VERSION ""

NS_ :

BS_:

BU_: ACSM CAS CCC CCC_GW CID CID_C DME DSC DWA Diverse_Sender EGS FLA FRMFA FZD IHKA JBBF KBM KGM KOMBI Kombi MRSZ M_ASK PDC SM_BF SM_FA SZL SZM VDM ZBE

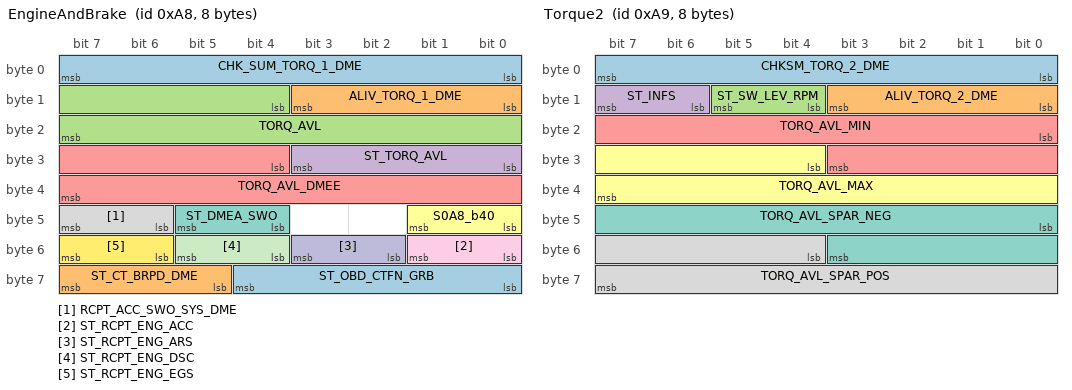
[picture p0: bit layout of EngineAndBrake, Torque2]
BO_ 168 EngineAndBrake: 8 DME
 SG_ CHK_SUM_TORQ_1_DME : 0|8@1+ (1,0) [0|255] "" Vector__XXX
 SG_ ALIV_TORQ_1_DME : 8|4@1+ (1,0) [0|15] "" Vector__XXX
 SG_ TORQ_AVL : 12|12@1- (0.5,0) [-1024|1023.5] "Nm" Vector__XXX
 SG_ ST_TORQ_AVL : 24|4@1+ (1,0) [0|15] "" Vector__XXX
 SG_ TORQ_AVL_DMEE : 28|12@1- (0.5,0) [-1024|1023.5] "Nm" Vector__XXX
 SG_ S0A8_b40 : 40|2@1+ (1,0) [0|3] "" Vector__XXX
 SG_ ST_DMEA_SWO : 44|2@1+ (1,0) [0|3] "" Vector__XXX
 SG_ RCPT_ACC_SWO_SYS_DME : 46|2@1+ (1,0) [0|3] "" Vector__XXX
 SG_ ST_RCPT_ENG_ACC : 48|2@1+ (1,0) [0|3] "" Vector__XXX
 SG_ ST_RCPT_ENG_ARS : 50|2@1+ (1,0) [0|3] "" Vector__XXX
 SG_ ST_RCPT_ENG_DSC : 52|2@1+ (1,0) [0|3] "" Vector__XXX
 SG_ ST_RCPT_ENG_EGS : 54|2@1+ (1,0) [0|3] "" Vector__XXX
 SG_ ST_OBD_CTFN_GRB : 56|5@1+ (1,0) [0|31] "" Vector__XXX
 SG_ ST_CT_BRPD_DME : 61|3@1+ (1,0) [0|7] "" Vector__XXX

BO_ 169 Torque2: 8 DME
 SG_ CHKSM_TORQ_2_DME : 0|8@1+ (1,0) [0|255] "" Vector__XXX
 SG_ ALIV_TORQ_2_DME : 8|4@1+ (1,0) [0|15] "" Vector__XXX
 SG_ ST_SW_LEV_RPM : 12|2@1+ (1,0) [0|3] "" Vector__XXX
 SG_ ST_INFS : 14|2@1+ (1,0) [0|3] "" Vector__XXX
 SG_ TORQ_AVL_MIN : 16|12@1- (0.5,0) [-1024|1023.5] "Nm" Vector__XXX
 SG_ TORQ_AVL_MAX : 28|12@1- (0.5,0) [-1024|1023.5] "Nm" Vector__XXX
 SG_ TORQ_AVL_SPAR_NEG : 40|12@1- (0.5,0) [-1024|1023.5] "Nm" Vector__XXX
 SG_ TORQ_AVL_SPAR_POS : 52|12@1- (0.5,0) [-1024|1023.5] "Nm" Vector__XXX

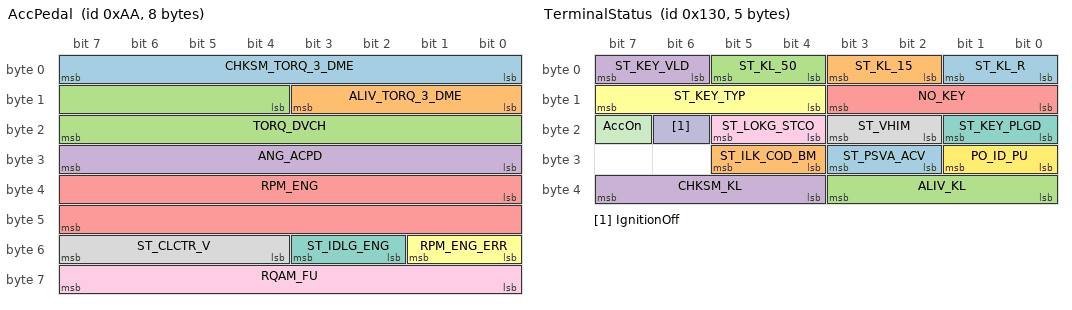
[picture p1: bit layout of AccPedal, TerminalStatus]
BO_ 170 AccPedal: 8 DME
 SG_ CHKSM_TORQ_3_DME : 0|8@1+ (1,0) [0|255] "" Vector__XXX
 SG_ ALIV_TORQ_3_DME : 8|4@1+ (1,0) [0|15] "" Vector__XXX
 SG_ TORQ_DVCH : 12|12@1- (0.5,0) [-1024|1023.5] "Nm" Vector__XXX
 SG_ ANG_ACPD : 24|8@1+ (0.39063,0) [0|99.61065] "%" Vector__XXX
 SG_ RPM_ENG : 32|16@1+ (0.25,0) [0|16383.75] "rpm" Vector__XXX
 SG_ RPM_ENG_ERR : 48|2@1+ (1,0) [0|3] "" Vector__XXX
 SG_ ST_IDLG_ENG : 50|2@1+ (1,0) [0|3] "" Vector__XXX
 SG_ ST_CLCTR_V : 52|4@1+ (1,0) [0|15] "" Vector__XXX
 SG_ RQAM_FU : 56|8@1+ (1,0) [0|255] "" Vector__XXX

BO_ 192 Alive_Central_Gateway: 2 JBBF

BO_ 196 SteeringWheelAngle: 7 DSC
 SG_ SteeringPosition : 0|16@1- (0.04395,0) [-1440.1536|1440.10965] "deg" Vector__XXX
 SG_ S0C4_b16 : 16|2@1+ (1,0) [0|3] "" Vector__XXX
 SG_ SteeringSpeed : 24|16@1- (0.04395,0) [-1440.1536|1440.10965] "deg/s" Vector__XXX
 SG_ S0C4_b40 : 40|8@1+ (1,0) [0|255] "" Vector__XXX
 SG_ S0C4_b48 : 48|2@1+ (1,0) [0|3] "" Vector__XXX
 SG_ S0C4_b50 : 50|2@1+ (1,0) [0|3] "" Vector__XXX

BO_ 200 SteeringWheelAngle_slow: 6 SZL
 SG_ SteeringPosition : 0|16@1- (0.04395,0) [-1440.1536|1440.10965] "deg" Vector__XXX
 SG_ Counter_200 : 20|4@1+ (1,0) [0|15] "" Vector__XXX
 SG_ SteeringSpeed : 24|16@1- (0.04395,0) [-1440.1536|1440.10965] "deg/s" Vector__XXX

BO_ 206 GESCHWINDIGKEIT_RAD: 8 DSC
 SG_ V_WHL_FLH : 0|16@1- (0.0625,0) [-2048|2047.9375] "km/h" Vector__XXX
 SG_ V_WHL_FRH : 16|16@1- (0.0625,0) [-2048|2047.9375] "km/h" Vector__XXX
 SG_ V_WHL_RLH : 32|16@1- (0.0625,0) [-2048|2047.9375] "km/h" Vector__XXX
 SG_ V_WHL_RRH : 48|16@1- (0.0625,0) [-2048|2047.9375] "km/h" Vector__XXX

BO_ 215 Alive_Counter_Security: 2 ACSM

BO_ 226 Status_central_locking_BFT: 8 JBBF

BO_ 230 Status_central_locking_BFTH: 8 JBBF

BO_ 234 Status_central_locking_FAT: 8 JBBF

BO_ 238 Central_locking_status_FATH: 8 JBBF

BO_ 242 Status_central_locking_HK: 8 JBBF

BO_ 246 SteuerungAu_enspiegel: 2 KGM

BO_ 250 Control_window_lifter_FAT: 3 FRMFA

BO_ 304 TerminalStatus: 5 CAS
 SG_ ST_KL_R : 0|2@1+ (1,0) [0|3] "" Vector__XXX
 SG_ ST_KL_15 : 2|2@1+ (1,0) [0|3] "" Vector__XXX
 SG_ ST_KL_50 : 4|2@1+ (1,0) [0|3] "" Vector__XXX
 SG_ ST_KEY_VLD : 6|2@1+ (1,0) [0|3] "" Vector__XXX
 SG_ NO_KEY : 8|4@1+ (1,0) [0|15] "" Vector__XXX
 SG_ ST_KEY_TYP : 12|4@1+ (1,0) [0|15] "" Vector__XXX
 SG_ ST_KEY_PLGD : 16|2@1+ (1,0) [0|3] "" Vector__XXX
 SG_ ST_VHIM : 18|2@1+ (1,0) [0|3] "" Vector__XXX
 SG_ ST_LOKG_STCO : 20|2@1+ (1,0) [0|3] "" Vector__XXX
 SG_ IgnitionOff : 22|1@1+ (1,0) [0|3] "" Vector__XXX
 SG_ AccOn : 23|1@1+ (1,0) [0|255] "" Vector__XXX
 SG_ PO_ID_PU : 24|2@1+ (1,0) [0|3] "" Vector__XXX
 SG_ ST_PSVA_ACV : 26|2@1+ (1,0) [0|3] "" Vector__XXX
 SG_ ST_ILK_COD_BM : 28|2@1+ (1,0) [0|3] "" Vector__XXX
 SG_ ALIV_KL : 32|4@1+ (1,0) [0|15] "" Vector__XXX
 SG_ CHKSM_KL : 36|4@1+ (1,0) [0|15] "" Vector__XXX

BO_ 309 CrashDisconnectControl: 2 ACSM
 SG_ CTR_CR_SWO_EKP : 0|4@1+ (1,0) [0|15] "" Vector__XXX

BO_ 370 Acknowledgment_request_KOMBInati: 5 CCC

BO_ 373 Display_motor_data: 3 DME

BO_ 405 Operation_push_button_MSA: 2 IHKA

BO_ 414 STAT_DSC: 8 DSC
 SG_ ST_CLCTR : 0|8@1+ (1,0) [0|255] "" Vector__XXX
 SG_ S19E_b8 : 8|2@1+ (1,0) [0|3] "" Vector__XXX
 SG_ ST_DSC : 10|3@1+ (1,0) [0|7] "" Vector__XXX
 SG_ S19E_b14 : 14|2@1+ (1,0) [0|3] "" Vector__XXX
 SG_ S19E_b16 : 16|2@1+ (1,0) [0|3] "" Vector__XXX
 SG_ S19E_b18 : 18|2@1+ (1,0) [0|3] "" Vector__XXX
 SG_ ALIV_19E : 20|4@1+ (1,0) [0|15] "" Vector__XXX
 SG_ S19E_b24 : 24|2@1+ (1,0) [0|3] "" Vector__XXX
 SG_ S19E_b26 : 26|2@1+ (1,0) [0|3] "" Vector__XXX
 SG_ S19E_b28 : 28|2@1+ (1,0) [0|3] "" Vector__XXX
 SG_ S19E_b30 : 30|2@1+ (1,0) [0|3] "" Vector__XXX
 SG_ ST_DCRN_AVL : 32|4@1+ (1,0) [0|15] "" Vector__XXX
 SG_ S19E_b36 : 36|2@1+ (1,0) [0|3] "" Vector__XXX
 SG_ S19E_b38 : 38|2@1+ (1,0) [0|3] "" Vector__XXX
 SG_ S19E_b40 : 40|2@1+ (1,0) [0|3] "" Vector__XXX
 SG_ S19E_b42 : 42|2@1+ (1,0) [0|3] "" Vector__XXX
 SG_ S19E_b44 : 44|2@1+ (1,0) [0|3] "" Vector__XXX
 SG_ S19E_b46 : 46|2@1+ (1,0) [0|3] "" Vector__XXX
 SG_ S19E_b48 : 48|8@1+ (1,0) [0|255] "" Vector__XXX
 SG_ CHKSM_19E : 56|8@1+ (1,0) [0|255] "" Vector__XXX

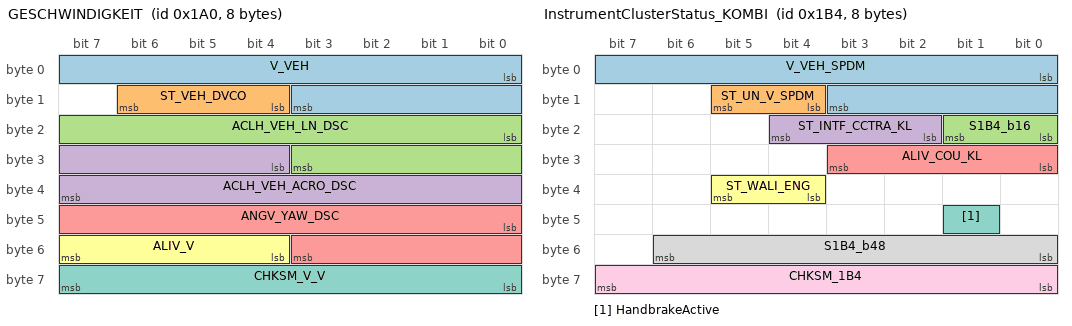
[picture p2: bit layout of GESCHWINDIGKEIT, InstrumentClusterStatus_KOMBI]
BO_ 416 GESCHWINDIGKEIT: 8 DSC
 SG_ V_VEH : 0|12@1+ (0.1,0) [0|409.5] "km/h" Vector__XXX
 SG_ ST_VEH_DVCO : 12|3@1+ (1,0) [0|7] "" Vector__XXX
 SG_ ACLH_VEH_LN_DSC : 16|12@1- (0.025,0) [-51.2|51.175] "m/s^2" Vector__XXX
 SG_ ACLH_VEH_ACRO_DSC : 28|12@1- (0.025,0) [-51.2|51.175] "m/s^2" Vector__XXX
 SG_ ANGV_YAW_DSC : 40|12@1- (0.05,0) [-102.4|102.35] "deg/s" Vector__XXX
 SG_ ALIV_V : 52|4@1+ (1,0) [0|15] "" Vector__XXX
 SG_ CHKSM_V_V : 56|8@1+ (1,0) [0|255] "" Vector__XXX

BO_ 422 DistanceRoute: 8 DSC
 SG_ S1A6_b0 : 0|16@1+ (1,0) [0|65535] "" Vector__XXX
 SG_ S1A6_b16 : 16|16@1+ (1,0) [0|65535] "" Vector__XXX
 SG_ S1A6_b32 : 32|16@1+ (1,0) [0|65535] "" Vector__XXX
 SG_ S1A6_b48 : 48|12@1+ (1,0) [0|4095] "" Vector__XXX

BO_ 426 Effect_ErgoCommander: 8 CCC

BO_ 436 InstrumentClusterStatus_KOMBI: 8 KOMBI
 SG_ V_VEH_SPDM : 0|12@1+ (0.1,0) [0|409.5] "km/h" Vector__XXX
 SG_ ST_UN_V_SPDM : 12|2@1+ (1,0) [0|3] "" Vector__XXX
 SG_ S1B4_b16 : 16|2@1+ (1,0) [0|3] "" Vector__XXX
 SG_ ST_INTF_CCTRA_KL : 18|3@1+ (1,0) [0|7] "" Vector__XXX
 SG_ ALIV_COU_KL : 24|4@1+ (1,0) [0|15] "" Vector__XXX
 SG_ ST_WALI_ENG : 36|2@1+ (1,0) [0|3] "" Vector__XXX
 SG_ HandbrakeActive : 41|1@1+ (1,0) [0|3] "" Vector__XXX
 SG_ S1B4_b48 : 48|7@1+ (1,0) [0|127] "" Vector__XXX
 SG_ CHKSM_1B4 : 56|8@1+ (1,0) [0|255] "" Vector__XXX

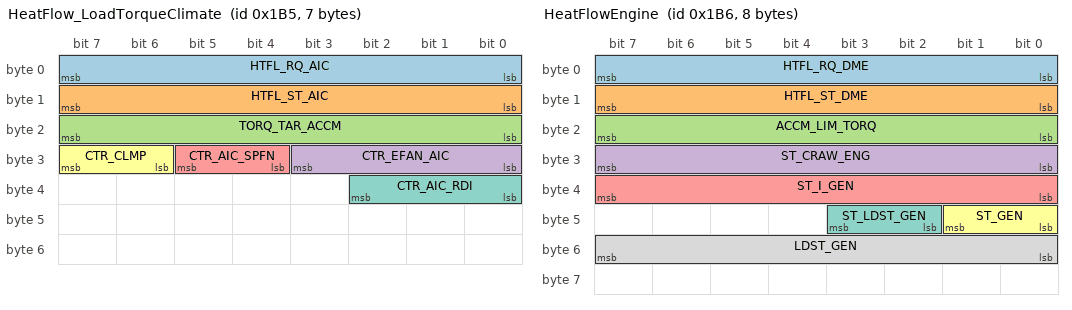
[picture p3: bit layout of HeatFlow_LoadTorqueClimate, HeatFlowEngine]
BO_ 437 HeatFlow_LoadTorqueClimate: 7 IHKA
 SG_ HTFL_RQ_AIC : 0|8@1+ (1,0) [0|255] "" Vector__XXX
 SG_ HTFL_ST_AIC : 8|8@1+ (1,0) [0|255] "" Vector__XXX
 SG_ TORQ_TAR_ACCM : 16|8@1+ (0.5,0) [0|127.5] "Nm" Vector__XXX
 SG_ CTR_EFAN_AIC : 24|4@1+ (1,0) [0|15] "" Vector__XXX
 SG_ CTR_AIC_SPFN : 28|2@1+ (1,0) [0|3] "" Vector__XXX
 SG_ CTR_CLMP : 30|2@1+ (1,0) [0|3] "" Vector__XXX
 SG_ CTR_AIC_RDI : 32|3@1+ (1,0) [0|7] "" Vector__XXX

BO_ 438 HeatFlowEngine: 8 DME
 SG_ HTFL_RQ_DME : 0|8@1+ (1,0) [0|255] "" Vector__XXX
 SG_ HTFL_ST_DME : 8|8@1+ (1,0) [0|255] "" Vector__XXX
 SG_ ACCM_LIM_TORQ : 16|8@1+ (0.5,0) [0|127.5] "Nm" Vector__XXX
 SG_ ST_CRAW_ENG : 24|8@1+ (1,0) [0|255] "A" Vector__XXX
 SG_ ST_I_GEN : 32|8@1+ (1,0) [0|255] "A" Vector__XXX
 SG_ ST_GEN : 40|2@1+ (1,0) [0|3] "" Vector__XXX
 SG_ ST_LDST_GEN : 42|2@1+ (1,0) [0|3] "" Vector__XXX
 SG_ LDST_GEN : 48|8@1+ (1,0) [0|255] "%" Vector__XXX

BO_ 450 Distance_message_PDC: 8 PDC

BO_ 454 Acoustic_message_PDC: 4 PDC

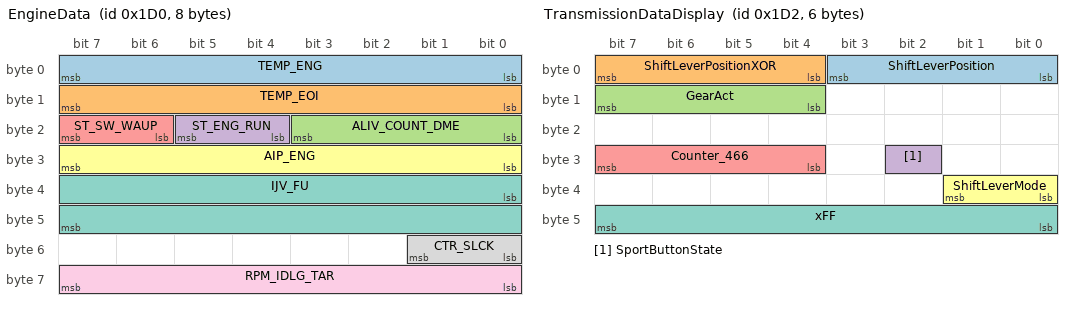
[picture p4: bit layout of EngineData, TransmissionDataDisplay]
BO_ 464 EngineData: 8 DME
 SG_ TEMP_ENG : 0|8@1+ (1,-48) [-48|207] "degC" Vector__XXX
 SG_ TEMP_EOI : 8|8@1+ (1,-48) [-48|207] "degC" Vector__XXX
 SG_ ALIV_COUNT_DME : 16|4@1+ (1,0) [0|15] "" Vector__XXX
 SG_ ST_ENG_RUN : 20|2@1+ (1,0) [0|3] "" Vector__XXX
 SG_ ST_SW_WAUP : 22|2@1+ (1,0) [0|3] "" Vector__XXX
 SG_ AIP_ENG : 24|8@1+ (2,598) [598|1108] "hPa" Vector__XXX
 SG_ IJV_FU : 32|16@1+ (1,0) [0|65535] "ul" Vector__XXX
 SG_ CTR_SLCK : 48|2@1+ (1,0) [0|3] "" Vector__XXX
 SG_ RPM_IDLG_TAR : 56|8@1+ (5,0) [0|1275] "rpm" Vector__XXX

BO_ 466 TransmissionDataDisplay: 6 EGS
 SG_ ShiftLeverPosition : 0|4@1+ (1,0) [0|8] "" Vector__XXX
 SG_ ShiftLeverPositionXOR : 4|4@1+ (1,0) [0|15] "" Vector__XXX
 SG_ GearAct : 12|4@1+ (1,-4) [0|15] "" Vector__XXX
 SG_ SportButtonState : 26|1@1+ (1,0) [0|1] "" Vector__XXX
 SG_ Counter_466 : 28|4@1+ (1,0) [0|14] "" Vector__XXX
 SG_ ShiftLeverMode : 32|2@1+ (1,0) [0|3] "" Vector__XXX
 SG_ xFF : 40|8@1+ (1,0) [0|255] "" Vector__XXX

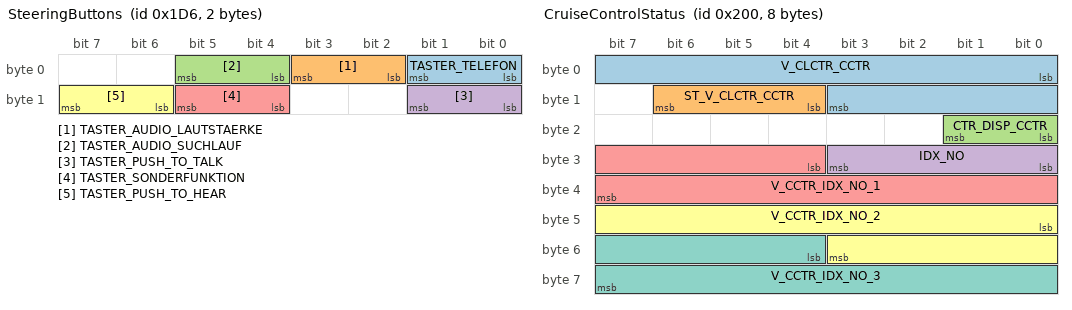
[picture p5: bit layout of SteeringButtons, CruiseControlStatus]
BO_ 470 SteeringButtons: 2 SZL
 SG_ TASTER_TELEFON : 0|2@1+ (1,0) [0|3] "" Vector__XXX
 SG_ TASTER_AUDIO_LAUTSTAERKE : 2|2@1+ (1,0) [0|3] "" Vector__XXX
 SG_ TASTER_AUDIO_SUCHLAUF : 4|2@1+ (1,0) [0|3] "" Vector__XXX
 SG_ TASTER_PUSH_TO_TALK : 8|2@1+ (1,0) [0|3] "" Vector__XXX
 SG_ TASTER_SONDERFUNKTION : 12|2@1+ (1,0) [0|3] "" Vector__XXX
 SG_ TASTER_PUSH_TO_HEAR : 14|2@1+ (1,0) [0|3] "" Vector__XXX

BO_ 473 Operation_pushbutton_MDrive: 3 SZL
 SG_ MDriveButton_inv : 6|1@1+ (1,0) [0|1] "" Vector__XXX
 SG_ MDriveButton : 14|1@1+ (1,0) [0|1] "" Vector__XXX
 SG_ Counter_1D9 : 16|4@1+ (1,0) [0|15] "" Vector__XXX

BO_ 481 Unknown_1E1: 6 Vector__XXX

BO_ 483 Operation_pushbutton_interior_li: 2 FZD

BO_ 487 Operation_seat_heating_seat_clim: 2 IHKA
 SG_ SeatHeatingButton_FA : 0|2@1+ (1,0) [0|3] "" Vector__XXX

BO_ 488 Operation_seat_heating_seat_1E8: 2 IHKA
 SG_ SeatHeatingButton_BF : 0|2@1+ (1,0) [0|3] "" Vector__XXX

BO_ 494 Steering_column_switch_operation: 2 FRMFA

BO_ 512 CruiseControlStatus: 8 DME
 SG_ V_CLCTR_CCTR : 0|12@1+ (0.1,0) [0|409.5] "km/h" Vector__XXX
 SG_ ST_V_CLCTR_CCTR : 12|3@1+ (1,0) [0|7] "" Vector__XXX
 SG_ CTR_DISP_CCTR : 16|2@1+ (1,0) [0|3] "" Vector__XXX
 SG_ IDX_NO : 24|4@1+ (1,0) [0|15] "" Vector__XXX
 SG_ V_CCTR_IDX_NO_1 : 28|12@1+ (0.1,0) [0|409.5] "km/h" Vector__XXX
 SG_ V_CCTR_IDX_NO_2 : 40|12@1+ (0.1,0) [0|409.5] "km/h" Vector__XXX
 SG_ V_CCTR_IDX_NO_3 : 52|12@1+ (0.1,0) [0|409.5] "km/h" Vector__XXX

BO_ 514 Dimming: 2 FRMFA
 SG_ DimmerPosition : 0|8@1+ (1,0) [0|255] "" Vector__XXX

BO_ 517 Acoustic_request_KOMBI: 2 KOMBI
 SG_ GongRequest : 0|4@1+ (1,0) [0|15] "" Vector__XXX

BO_ 518 Control_Display_Shiftlights: 2 DME
 SG_ ShiftlightMode : 0|8@1+ (1,0) [0|255] "" Vector__XXX
 SG_ ShiftlightParameter : 8|8@1+ (1,0) [0|255] "" Vector__XXX

BO_ 538 LampStatus: 3 FRMFA

BO_ 550 RainSensorWiperSpeed: 5 FZD
 SG_ S226_b0 : 0|8@1+ (1,0) [0|255] "" Vector__XXX
 SG_ S226_b8 : 8|16@1+ (1,0) [0|65535] "" Vector__XXX
 SG_ S226_b24 : 24|4@1+ (1,0) [0|15] "" Vector__XXX

BO_ 552 Operation_special_function: 2 CCC

BO_ 554 Status_BFS: 3 JBBF

BO_ 556 Operation_push_button_NSL: 2 FRMFA

BO_ 562 Status_FAS: 3 JBBF

BO_ 570 Status_radio_key: 4 CAS
 SG_ S23A_b8 : 8|8@1+ (1,0) [0|255] "" Vector__XXX
 SG_ KeyFobButton : 16|8@1+ (1,0) [0|255] "" Vector__XXX

BO_ 578 ClimateFrontStatus: 5 IHKA

BO_ 582 Status_air_conditioning_front_co: 5 IHKA

BO_ 586 Status_PDC: 2 PDC
 SG_ PDC_Status : 0|8@1+ (1,0) [0|255] "" Vector__XXX

BO_ 587 Status_door_sensors: 2 FRMFA

BO_ 594 Wiper_status: 2 JBBF
 SG_ WiperState : 0|8@1+ (1,0) [0|255] "" Vector__XXX

BO_ 612 iDrive_Controller_Rotation: 6 ZBE
 SG_ Counter_264 : 16|8@1+ (1,0) [0|255] "" Vector__XXX
 SG_ ControllerRotation : 24|8@1- (1,0) [-128|127] "" Vector__XXX

BO_ 615 iDrive_Controller_Buttons: 6 ZBE
 SG_ Counter_267 : 16|8@1+ (1,0) [0|255] "" Vector__XXX
 SG_ ControllerButtonPressed : 24|4@1+ (1,0) [0|15] "" Vector__XXX
 SG_ ControllerDirection : 28|4@1+ (1,0) [0|15] "" Vector__XXX
 SG_ ControllerButton : 32|8@1+ (1,0) [0|255] "" Vector__XXX

BO_ 621 Operation_blinds_MK: 3 IHKA

BO_ 622 Control_FH_SHD_central_comfort: 8 CAS

BO_ 627 EZbeCicStatusResponse: 8 Vector__XXX
 SG_ Counter_273 : 56|8@1+ (1,0) [0|255] "" Vector__XXX

BO_ 631 EZbeCicStatusResponse_277: 4 Vector__XXX
 SG_ EchoCounter_273 : 16|8@1+ (1,0) [0|255] "" Vector__XXX

BO_ 632 Navigationsgraph: 8 CCC

BO_ 634 Synchronisation_Navigationsgraph: 8 CCC

BO_ 646 Electrochromic_control: 2 FZD

BO_ 658 Control_high_beam_assistant: 2 FLA

BO_ 672 Central_locking_control: 8 CAS

BO_ 678 WiperSwitch: 2 SZL
 SG_ WISCHERTASTER : 0|8@1+ (1,0) [0|255] "" Vector__XXX
 SG_ WISCHERPOTI : 8|3@1+ (1,0) [0|7] "" Vector__XXX

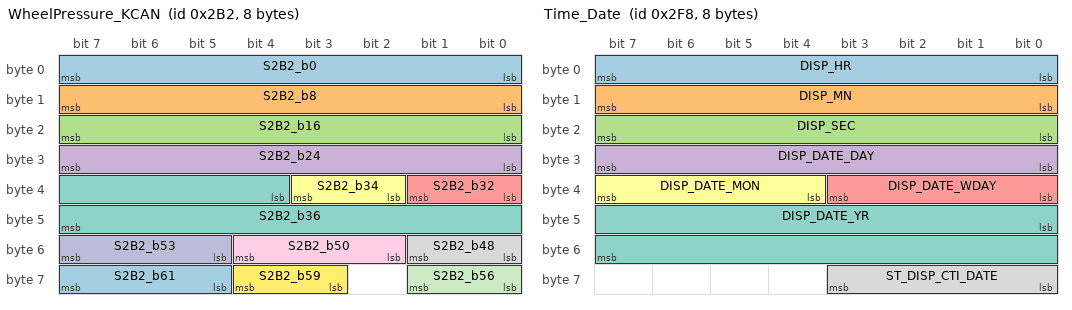
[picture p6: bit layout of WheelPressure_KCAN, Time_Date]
BO_ 690 WheelPressure_KCAN: 8 DSC
 SG_ S2B2_b0 : 0|8@1+ (1,0) [0|255] "" Vector__XXX
 SG_ S2B2_b8 : 8|8@1+ (1,0) [0|255] "" Vector__XXX
 SG_ S2B2_b16 : 16|8@1+ (1,0) [0|255] "" Vector__XXX
 SG_ S2B2_b24 : 24|8@1+ (1,0) [0|255] "" Vector__XXX
 SG_ S2B2_b32 : 32|2@1+ (1,0) [0|3] "" Vector__XXX
 SG_ S2B2_b34 : 34|2@1+ (1,0) [0|3] "" Vector__XXX
 SG_ S2B2_b36 : 36|12@1- (1,0) [-2048|2047] "" Vector__XXX
 SG_ S2B2_b48 : 48|2@1+ (1,0) [0|3] "" Vector__XXX
 SG_ S2B2_b50 : 50|3@1+ (1,0) [0|7] "" Vector__XXX
 SG_ S2B2_b53 : 53|3@1+ (1,0) [0|7] "" Vector__XXX
 SG_ S2B2_b56 : 56|2@1+ (1,0) [0|3] "" Vector__XXX
 SG_ S2B2_b59 : 59|2@1+ (1,0) [0|3] "" Vector__XXX
 SG_ S2B2_b61 : 61|3@1+ (1,0) [0|7] "" Vector__XXX

BO_ 692 DWA_Alarm: 2 DWA
 SG_ AlarmFlashHazards : 0|1@1+ (1,0) [0|1] "" Vector__XXX
 SG_ AlarmFlashXenon : 1|1@1+ (1,0) [0|1] "" Vector__XXX
 SG_ AlarmFlashAngelEyes : 2|1@1+ (1,0) [0|1] "" Vector__XXX
 SG_ ConfirmationFlash : 8|4@1+ (1,0) [0|15] "" Vector__XXX

BO_ 696 Operation_onboard_computer: 6 CCC
 SG_ SpeedWarningOn : 6|1@1+ (1,0) [0|1] "" Vector__XXX
 SG_ SpeedWarningLimit : 8|12@1+ (1,0) [0|4095] "km/h" Vector__XXX

BO_ 698 Stopwatch: 5 KOMBI

BO_ 704 LCD_lighting: 3 KOMBI
 SG_ LCD_Brightness : 0|8@1+ (1,0) [0|255] "" Vector__XXX
 SG_ S2C0_b8 : 8|8@1+ (1,0) [0|255] "" Vector__XXX
 SG_ CID_Brightness : 16|8@1+ (1,0) [0|255] "" Vector__XXX

BO_ 707 KCAN_2C3: 5 Vector__XXX

BO_ 714 Outside_temperature: 2 KOMBI

BO_ 718 Control_monitor: 3 CCC

BO_ 719 Status_of_auxiliary_water_pump: 2 JBBF

BO_ 720 Status_Sensor_AUC: 2 JBBF

BO_ 721 Status_fitting_window_V: 2 FZD

BO_ 722 Status_pressure_refrigeration_ci: 3 JBBF

BO_ 723 Status_stratification_rear: 4 JBBF

BO_ 725 Status_heating_rear_window: 2 JBBF

BO_ 726 Status_valve_air_conditioning_co: 3 JBBF

BO_ 742 Status_of_air_distribution_FA: 8 IHKA
 SG_ AutoAirDistribution : 37|1@1+ (1,0) [0|1] "" Vector__XXX
 SG_ AutoFan : 54|1@1+ (1,0) [0|1] "" Vector__XXX

BO_ 746 Status_air_distribution_BF: 8 IHKA

BO_ 750 Status_climate_additional_progra: 2 IHKA

BO_ 752 Status_air_condition_functions: 2 IHKA

BO_ 753 Status_driver_detection: 3 MRSZ

BO_ 756 Air_conditioning_control_SH_ZH_a: 4 IHKA

BO_ 758 LightControl: 2 FRMFA

BO_ 759 Units: 4 KOMBI
 SG_ DistanceUnit : 22|2@1+ (1,0) [0|3] "" Vector__XXX

BO_ 760 Time_Date: 8 KOMBI
 SG_ DISP_HR : 0|8@1+ (1,0) [0|255] "" Vector__XXX
 SG_ DISP_MN : 8|8@1+ (1,0) [0|255] "" Vector__XXX
 SG_ DISP_SEC : 16|8@1+ (1,0) [0|255] "" Vector__XXX
 SG_ DISP_DATE_DAY : 24|8@1+ (1,0) [0|255] "" Vector__XXX
 SG_ DISP_DATE_WDAY : 32|4@1+ (1,0) [0|15] "" Vector__XXX
 SG_ DISP_DATE_MON : 36|4@1+ (1,0) [0|15] "" Vector__XXX
 SG_ DISP_DATE_YR : 40|16@1+ (1,0) [0|65535] "" Vector__XXX
 SG_ ST_DISP_CTI_DATE : 56|4@1- (1,0) [-8|7] "" Vector__XXX

BO_ 762 OccupancySeatBeltContact: 5 ACSM
 SG_ NEW_SIGNAL_2 : 0|8@1+ (1,0) [0|15] "" Vector__XXX
 SG_ NEW_SIGNAL_1 : 8|8@1+ (1,0) [0|255] "" Vector__XXX

BO_ 764 TrunkStatus: 7 CAS
 SG_ ST_DSW_DRD : 8|2@1+ (1,0) [0|3] "" Vector__XXX
 SG_ ST_CT_BON : 18|2@1+ (1,0) [0|3] "" Vector__XXX

BO_ 772 Status_Gang: 2 EGS

BO_ 774 Vehicle_tilt: 2 FRMFA

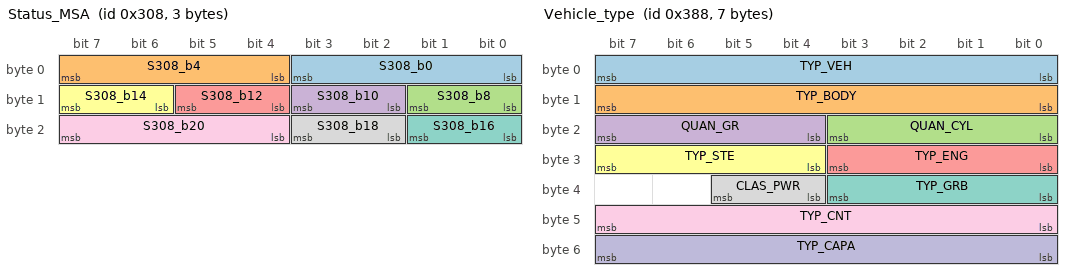
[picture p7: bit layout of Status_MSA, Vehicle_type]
BO_ 776 Status_MSA: 3 DME
 SG_ S308_b0 : 0|4@1+ (1,0) [0|15] "" Vector__XXX
 SG_ S308_b4 : 4|4@1+ (1,0) [0|15] "" Vector__XXX
 SG_ S308_b8 : 8|2@1+ (1,0) [0|3] "" Vector__XXX
 SG_ S308_b10 : 10|2@1+ (1,0) [0|3] "" Vector__XXX
 SG_ S308_b12 : 12|2@1+ (1,0) [0|3] "" Vector__XXX
 SG_ S308_b14 : 14|2@1+ (1,0) [0|3] "" Vector__XXX
 SG_ S308_b16 : 16|2@1+ (1,0) [0|3] "" Vector__XXX
 SG_ S308_b18 : 18|2@1+ (1,0) [0|3] "" Vector__XXX
 SG_ S308_b20 : 20|4@1+ (1,0) [0|15] "" Vector__XXX

BO_ 785 Refill_quantity: 2 KOMBI

BO_ 786 Service_Call_Teleservice: 2 KOMBI

BO_ 787 Status_Service_Call_Teleservice: 2 CCC

BO_ 788 Status_driving_light: 3 FZD
 SG_ HeadlightRequest : 8|8@1+ (1,0) [0|255] "" Vector__XXX

BO_ 789 Vehicle_mode: 2 SZM
 SG_ S315_b0 : 0|4@1+ (1,0) [0|15] "" Vector__XXX
 SG_ Counter_315 : 4|4@1+ (1,0) [0|15] "" Vector__XXX
 SG_ VehicleMode : 8|4@1+ (1,0) [0|15] "" Vector__XXX

BO_ 791 Operation_button_parking_aids: 2 IHKA
 SG_ PDC_Button : 0|2@1+ (1,0) [0|3] "" Vector__XXX

BO_ 793 Operation_push_button_RDC: 2 JBBF
 SG_ S319_b0 : 0|2@1+ (1,0) [0|3] "" Vector__XXX

BO_ 797 TirePressureStatus: 2 DSC
 SG_ S31D_b0 : 0|3@1+ (1,0) [0|7] "" Vector__XXX
 SG_ S31D_b3 : 3|5@1+ (1,0) [0|31] "" Vector__XXX
 SG_ S31D_b8 : 8|2@1+ (1,0) [0|3] "" Vector__XXX

BO_ 806 Status_damper_program: 2 VDM
 SG_ DamperProgram : 0|4@1+ (1,0) [0|15] "" Vector__XXX
 SG_ Counter_326 : 4|4@1+ (1,0) [0|15] "" Vector__XXX

BO_ 808 Relativzeit: 6 KOMBI

BO_ 814 Status_climate_internal_control_: 8 IHKA

BO_ 818 Driver_display_speed_range: 2 DME
 SG_ RPM_TEMP_DOM_1 : 0|8@1+ (50,0) [0|12750] "rpm" Vector__XXX
 SG_ RPM_TEMP_DOM_2 : 8|8@1+ (50,0) [0|12750] "rpm" Vector__XXX

BO_ 822 Display_check_control_message_ro: 7 KOMBI
 SG_ CC_List_MsgIndex : 0|4@1+ (1,0) [0|15] "" Vector__XXX
 SG_ CC_List_MsgCount : 4|4@1+ (1,0) [0|15] "" Vector__XXX
 SG_ CC_List_ID1 : 8|16@1+ (1,0) [0|65535] "" Vector__XXX
 SG_ CC_List_ID2 : 24|16@1+ (1,0) [0|65535] "" Vector__XXX
 SG_ CC_List_ID3 : 40|16@1+ (1,0) [0|65535] "" Vector__XXX

BO_ 824 Control_display_check_control_me: 8 KOMBI

BO_ 825 Status_display_climate: 2 CCC

BO_ 826 Status_Monitor_Front: 5 CID

BO_ 840 Uebereinstimmung_Navigationsgrap: 8 CCC

BO_ 841 Raw_data_level_tank: 5 JBBF

BO_ 844 Navigation_Gps_2: 8 CCC

BO_ 846 Navigation_System_Information: 8 CCC

BO_ 847 Status_contact_handbrake: 2 JBBF
 SG_ Handbrake_push : 0|2@1+ (1,0) [0|3] "" Vector__XXX

BO_ 860 Status_onboard_computer: 4 KOMBI
 SG_ SpeedWarningOn : 8|4@1+ (1,0) [0|15] "" Vector__XXX
 SG_ SpeedWarningLimit : 12|12@1+ (1,0) [0|4095] "km/h" Vector__XXX

BO_ 862 Onboard_computer_data_trip_data: 8 KOMBI

BO_ 864 Data_onboard_computer_start_of_j: 7 KOMBI

BO_ 866 Data_onboard_computer_average_va: 7 KOMBI

BO_ 868 Data_onboard_computer_arrival: 7 KOMBI

BO_ 870 Display_KOMBInation_external_dis: 4 KOMBI

BO_ 871 Control_display_of_demand_orient: 7 KOMBI

BO_ 877 Setting_the_driving_dynamics_swi: 6 JBBF
 SG_ PDC_Rear_OuterRight : 8|8@1+ (1,0) [0|255] "" Vector__XXX
 SG_ PDC_Rear_InnerRight : 16|8@1+ (1,0) [0|255] "" Vector__XXX
 SG_ PDC_Rear_InnerLeft : 24|8@1+ (1,0) [0|255] "" Vector__XXX
 SG_ PDC_Rear_OuterLeft : 32|8@1+ (1,0) [0|255] "" Vector__XXX

BO_ 897 EngineOilLevel: 2 DME
 SG_ FLLV_EOI : 0|8@1+ (1,0) [0|255] "" Vector__XXX
 SG_ RECM_RFLV_EOI : 8|4@1+ (1,0) [0|15] "" Vector__XXX

BO_ 904 Vehicle_type: 7 CAS
 SG_ TYP_VEH : 0|8@1+ (1,0) [0|255] "" Vector__XXX
 SG_ TYP_BODY : 8|8@1+ (1,0) [0|255] "" Vector__XXX
 SG_ QUAN_CYL : 16|4@1+ (1,0) [0|15] "" Vector__XXX
 SG_ QUAN_GR : 20|4@1+ (1,0) [0|15] "" Vector__XXX
 SG_ TYP_ENG : 24|4@1+ (1,0) [0|15] "" Vector__XXX
 SG_ TYP_STE : 28|4@1+ (1,0) [0|15] "" Vector__XXX
 SG_ TYP_GRB : 32|4@1+ (1,0) [0|15] "" Vector__XXX
 SG_ CLAS_PWR : 36|2@1+ (1,0) [0|3] "" Vector__XXX
 SG_ TYP_CNT : 40|8@1+ (1,0) [0|255] "" Vector__XXX
 SG_ TYP_CAPA : 48|8@1+ (100,0) [0|25500] "ccm" Vector__XXX

BO_ 906 KCAN_38A: 2 Vector__XXX

BO_ 907 Status_battery: 5 DME

BO_ 911 RearViewCameraSettings: 4 Vector__XXX
 SG_ Camera : 0|2@1+ (1,0) [0|3] "" Vector__XXX
 SG_ TowView : 3|1@1+ (1,0) [0|1] "" Vector__XXX
 SG_ CameraSetting1 : 8|8@1+ (1,0) [0|255] "" Vector__XXX
 SG_ CameraSetting2 : 16|8@1+ (1,0) [0|255] "" Vector__XXX

BO_ 916 RDA_request_data_storage: 8 KOMBI

BO_ 917 Coding_power_management: 5 CAS
 SG_ CLAS_BT : 0|8@1+ (1,0) [0|255] "" Vector__XXX
 SG_ QC_VEH : 8|8@1+ (1,0) [0|255] "mA" Vector__XXX
 SG_ I_SC_MIN_VEH : 16|8@1+ (1,0) [0|255] "A" Vector__XXX
 SG_ I_SC_MAX_VEH : 24|8@1+ (1,0) [0|255] "A" Vector__XXX

BO_ 921 Status_MDrive: 6 DME
 SG_ CHKSM_399 : 0|4@1+ (1,0) [0|15] "" Vector__XXX
 SG_ ALIV_399 : 4|4@1+ (1,0) [0|15] "" Vector__XXX
 SG_ S399_b8 : 8|2@1+ (1,0) [0|3] "" Vector__XXX
 SG_ S399_b10 : 10|3@1+ (1,0) [0|7] "" Vector__XXX

BO_ 923 RearViewCameraSettings_39B: 4 Vector__XXX
 SG_ CameraStatus : 0|8@1+ (1,0) [0|255] "" Vector__XXX
 SG_ CameraSetting1 : 8|8@1+ (1,0) [0|255] "" Vector__XXX
 SG_ CameraSetting2 : 16|8@1+ (1,0) [0|255] "" Vector__XXX
 SG_ TowView : 25|1@1+ (1,0) [0|1] "" Vector__XXX

BO_ 936 DmePowerCkm: 2 Vector__XXX
 SG_ PowerMode_CKM : 0|4@1+ (1,0) [0|15] "" Vector__XXX

BO_ 937 Status_motor_control_CKM: 2 DME
 SG_ PowerMode_CKM : 0|4@1+ (1,0) [0|15] "" Vector__XXX

BO_ 939 Status_Shiftlights_CKM: 2 KOMBI

BO_ 940 RunOnTimeTerminal30: 2 JBBF

BO_ 942 CameraControlFromIdrive: 2 Vector__XXX
 SG_ CameraControl : 0|8@1+ (1,0) [0|255] "" Vector__XXX

BO_ 943 PdcBusStates: 4 Vector__XXX
 SG_ Counter_3AF : 8|4@1+ (1,0) [0|15] "" Vector__XXX
 SG_ PDC_Active : 16|1@1+ (1,0) [0|1] "" Vector__XXX
 SG_ Camera_Active : 18|1@1+ (1,0) [0|1] "" Vector__XXX
 SG_ PDC_DisplayActive : 21|1@1+ (1,0) [0|1] "" Vector__XXX

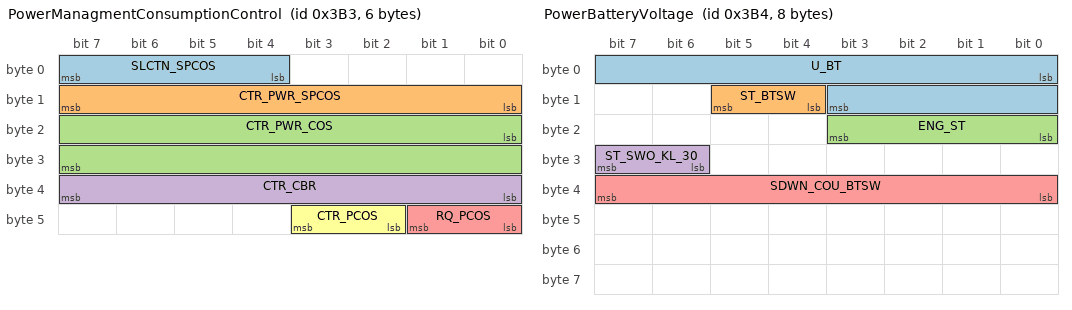
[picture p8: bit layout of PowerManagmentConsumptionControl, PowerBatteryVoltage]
BO_ 947 PowerManagmentConsumptionControl: 6 DME
 SG_ SLCTN_SPCOS : 4|4@1+ (1,0) [0|15] "" Vector__XXX
 SG_ CTR_PWR_SPCOS : 8|8@1+ (1,0) [0|255] "" Vector__XXX
 SG_ CTR_PWR_COS : 16|16@1+ (1,0) [0|65535] "" Vector__XXX
 SG_ CTR_CBR : 32|8@1+ (1,0) [0|255] "" Vector__XXX
 SG_ RQ_PCOS : 40|2@1+ (1,0) [0|3] "" Vector__XXX
 SG_ CTR_PCOS : 42|2@1+ (1,0) [0|3] "" Vector__XXX

BO_ 948 PowerBatteryVoltage: 8 DME
 SG_ U_BT : 0|12@1+ (0.015,0) [0|61.425] "V" Vector__XXX
 SG_ ST_BTSW : 12|2@1+ (1,0) [0|3] "" Vector__XXX
 SG_ ENG_ST : 16|4@1+ (1,0) [0|15] "" Vector__XXX
 SG_ ST_SWO_KL_30 : 30|2@1+ (1,0) [0|3] "" Vector__XXX
 SG_ SDWN_COU_BTSW : 32|8@1+ (1,0) [0|255] "" Vector__XXX

BO_ 950 Position_window_lifter_FAT: 3 FRMFA

BO_ 951 Position_window_lifter_FATH: 3 JBBF

BO_ 952 Position_window_regulator_BFT: 3 FRMFA

BO_ 953 Position_window_regulator_BFTH: 3 JBBF

BO_ 957 Status_consumer_shutdown: 2 FRMFA
 SG_ ConsumerShutdown : 0|2@1+ (1,0) [0|3] "" Vector__XXX

BO_ 958 PowerRunningTime: 2 CAS
 SG_ FLLUPT_GPWSUP : 0|12@1+ (10,0) [0|40950] "s" Vector__XXX

BO_ 961 Configuration_BFS: 3 SM_BF

BO_ 964 Status_EDCK_CKM: 2 JBBF

BO_ 970 KonfigurationM_Drive: 5 M_ASK

BO_ 972 KCAN_3CC: 7 Vector__XXX

BO_ 981 Status_central_locking_CKM: 2 CAS

BO_ 983 Status_DWA_CKM: 3 FZD
 SG_ LockVisualSignal_CKM : 0|2@1+ (1,0) [0|3] "" Vector__XXX

BO_ 985 Status_RLS_CKM: 2 FZD

BO_ 987 Status_memory_positions_CKM: 2 SM_FA
 SG_ SeatLastPosition_CKM : 0|8@1+ (1,0) [0|255] "" Vector__XXX

BO_ 989 Status_light_CKM: 3 FRMFA
 SG_ DaytimeRunningLights_CKM : 16|2@1+ (1,0) [0|3] "" Vector__XXX

BO_ 991 Status_Klima_CKM: 3 IHKA
 SG_ AutoFanIntensity : 4|4@1+ (1,0) [0|15] "" Vector__XXX

BO_ 1009 StatusLichtErweitertCkm: 2 FRMFA

BO_ 1015 KCAN_3F7: 8 Vector__XXX

BO_ 1040 KCAN_410: 4 Vector__XXX

BO_ 1041 KCAN_411: 3 Vector__XXX

BO_ 1043 KCAN_413: 8 Vector__XXX

BO_ 1045 KCAN_415: 7 Vector__XXX

BO_ 1078 KCAN_436: 2 Vector__XXX

BO_ 1152 NetworkManagmentKGM: 8 KGM
 SG_ S480_b0 : 0|1@1+ (1,0) [0|1] "" Vector__XXX

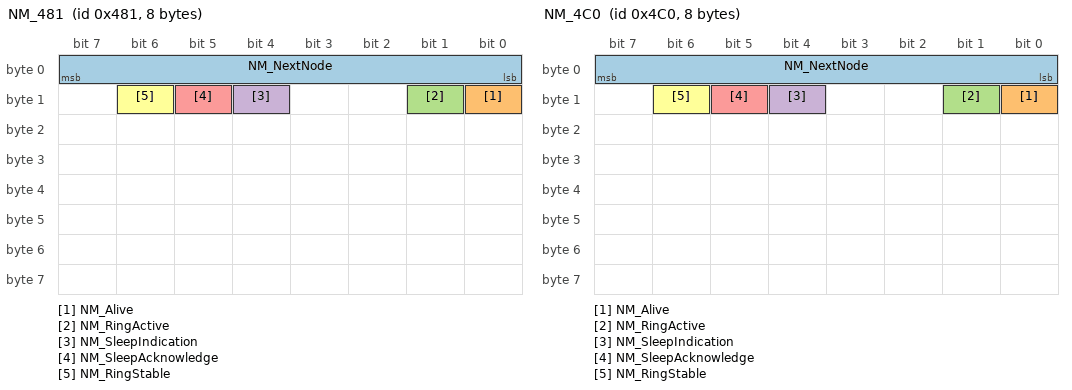
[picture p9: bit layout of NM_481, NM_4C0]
BO_ 1153 NM_481: 8 ACSM
 SG_ NM_NextNode : 0|8@1+ (1,0) [0|255] "" Vector__XXX
 SG_ NM_Alive : 8|1@1+ (1,0) [0|1] "" Vector__XXX
 SG_ NM_RingActive : 9|1@1+ (1,0) [0|1] "" Vector__XXX
 SG_ NM_SleepIndication : 12|1@1+ (1,0) [0|1] "" Vector__XXX
 SG_ NM_SleepAcknowledge : 13|1@1+ (1,0) [0|1] "" Vector__XXX
 SG_ NM_RingStable : 14|1@1+ (1,0) [0|1] "" Vector__XXX

BO_ 1216 NM_4C0: 8 CAS
 SG_ NM_NextNode : 0|8@1+ (1,0) [0|255] "" Vector__XXX
 SG_ NM_Alive : 8|1@1+ (1,0) [0|1] "" Vector__XXX
 SG_ NM_RingActive : 9|1@1+ (1,0) [0|1] "" Vector__XXX
 SG_ NM_SleepIndication : 12|1@1+ (1,0) [0|1] "" Vector__XXX
 SG_ NM_SleepAcknowledge : 13|1@1+ (1,0) [0|1] "" Vector__XXX
 SG_ NM_RingStable : 14|1@1+ (1,0) [0|1] "" Vector__XXX

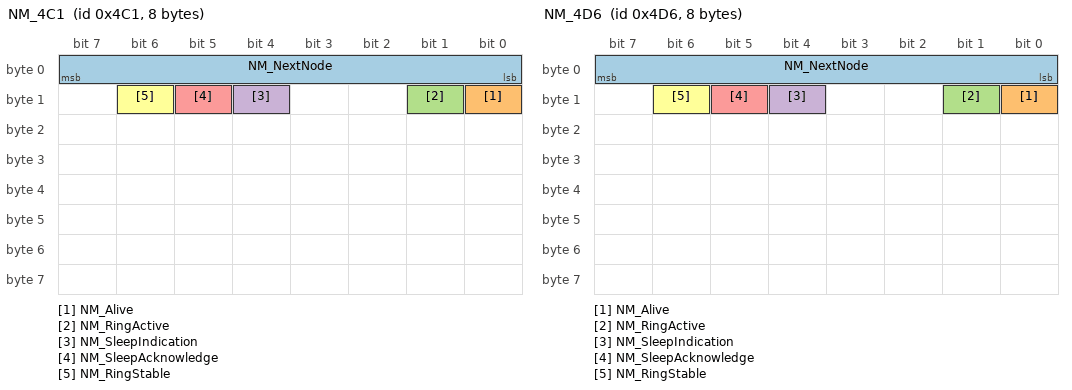
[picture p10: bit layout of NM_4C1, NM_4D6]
BO_ 1217 NM_4C1: 8 DWA
 SG_ NM_NextNode : 0|8@1+ (1,0) [0|255] "" Vector__XXX
 SG_ NM_Alive : 8|1@1+ (1,0) [0|1] "" Vector__XXX
 SG_ NM_RingActive : 9|1@1+ (1,0) [0|1] "" Vector__XXX
 SG_ NM_SleepIndication : 12|1@1+ (1,0) [0|1] "" Vector__XXX
 SG_ NM_SleepAcknowledge : 13|1@1+ (1,0) [0|1] "" Vector__XXX
 SG_ NM_RingStable : 14|1@1+ (1,0) [0|1] "" Vector__XXX

BO_ 1238 NM_4D6: 8 FZD
 SG_ NM_NextNode : 0|8@1+ (1,0) [0|255] "" Vector__XXX
 SG_ NM_Alive : 8|1@1+ (1,0) [0|1] "" Vector__XXX
 SG_ NM_RingActive : 9|1@1+ (1,0) [0|1] "" Vector__XXX
 SG_ NM_SleepIndication : 12|1@1+ (1,0) [0|1] "" Vector__XXX
 SG_ NM_SleepAcknowledge : 13|1@1+ (1,0) [0|1] "" Vector__XXX
 SG_ NM_RingStable : 14|1@1+ (1,0) [0|1] "" Vector__XXX

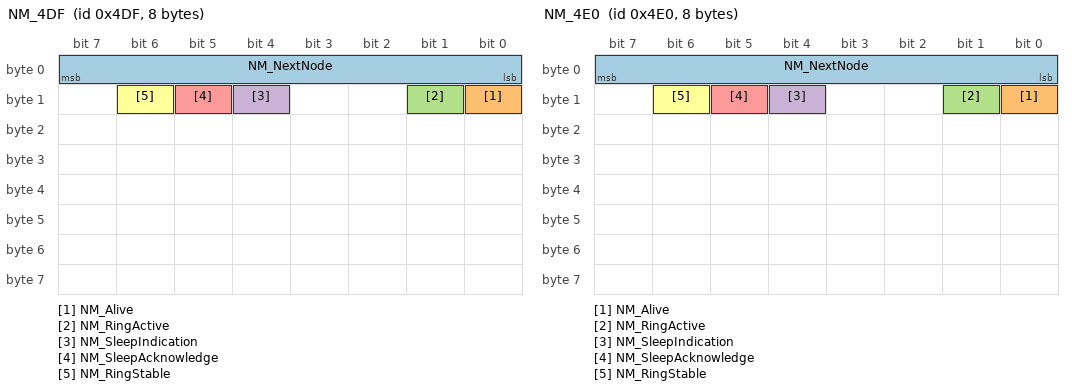
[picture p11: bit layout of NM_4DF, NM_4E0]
BO_ 1247 NM_4DF: 8 FLA
 SG_ NM_NextNode : 0|8@1+ (1,0) [0|255] "" Vector__XXX
 SG_ NM_Alive : 8|1@1+ (1,0) [0|1] "" Vector__XXX
 SG_ NM_RingActive : 9|1@1+ (1,0) [0|1] "" Vector__XXX
 SG_ NM_SleepIndication : 12|1@1+ (1,0) [0|1] "" Vector__XXX
 SG_ NM_SleepAcknowledge : 13|1@1+ (1,0) [0|1] "" Vector__XXX
 SG_ NM_RingStable : 14|1@1+ (1,0) [0|1] "" Vector__XXX

BO_ 1248 NM_4E0: 8 Kombi
 SG_ NM_NextNode : 0|8@1+ (1,0) [0|255] "" Vector__XXX
 SG_ NM_Alive : 8|1@1+ (1,0) [0|1] "" Vector__XXX
 SG_ NM_RingActive : 9|1@1+ (1,0) [0|1] "" Vector__XXX
 SG_ NM_SleepIndication : 12|1@1+ (1,0) [0|1] "" Vector__XXX
 SG_ NM_SleepAcknowledge : 13|1@1+ (1,0) [0|1] "" Vector__XXX
 SG_ NM_RingStable : 14|1@1+ (1,0) [0|1] "" Vector__XXX

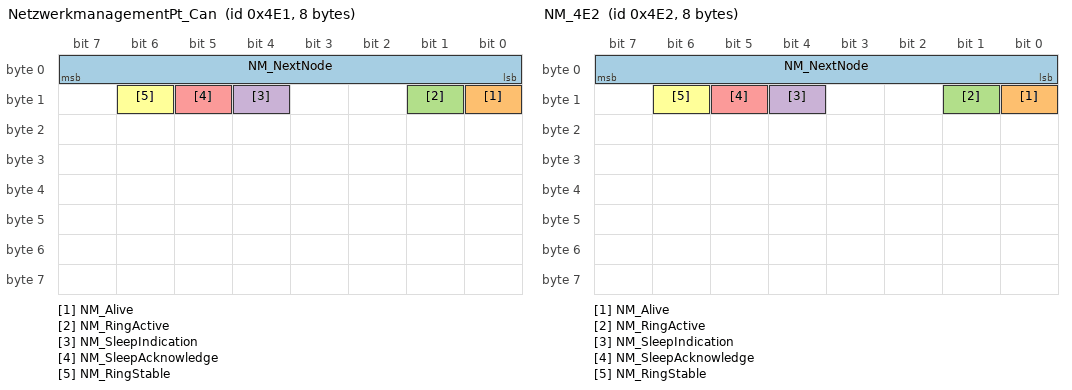
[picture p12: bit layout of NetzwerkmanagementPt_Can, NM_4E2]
BO_ 1249 NetzwerkmanagementPt_Can: 8 Diverse_Sender
 SG_ NM_NextNode : 0|8@1+ (1,0) [0|255] "" Vector__XXX
 SG_ NM_Alive : 8|1@1+ (1,0) [0|1] "" Vector__XXX
 SG_ NM_RingActive : 9|1@1+ (1,0) [0|1] "" Vector__XXX
 SG_ NM_SleepIndication : 12|1@1+ (1,0) [0|1] "" Vector__XXX
 SG_ NM_SleepAcknowledge : 13|1@1+ (1,0) [0|1] "" Vector__XXX
 SG_ NM_RingStable : 14|1@1+ (1,0) [0|1] "" Vector__XXX

BO_ 1250 NM_4E2: 8 CCC_GW
 SG_ NM_NextNode : 0|8@1+ (1,0) [0|255] "" Vector__XXX
 SG_ NM_Alive : 8|1@1+ (1,0) [0|1] "" Vector__XXX
 SG_ NM_RingActive : 9|1@1+ (1,0) [0|1] "" Vector__XXX
 SG_ NM_SleepIndication : 12|1@1+ (1,0) [0|1] "" Vector__XXX
 SG_ NM_SleepAcknowledge : 13|1@1+ (1,0) [0|1] "" Vector__XXX
 SG_ NM_RingStable : 14|1@1+ (1,0) [0|1] "" Vector__XXX

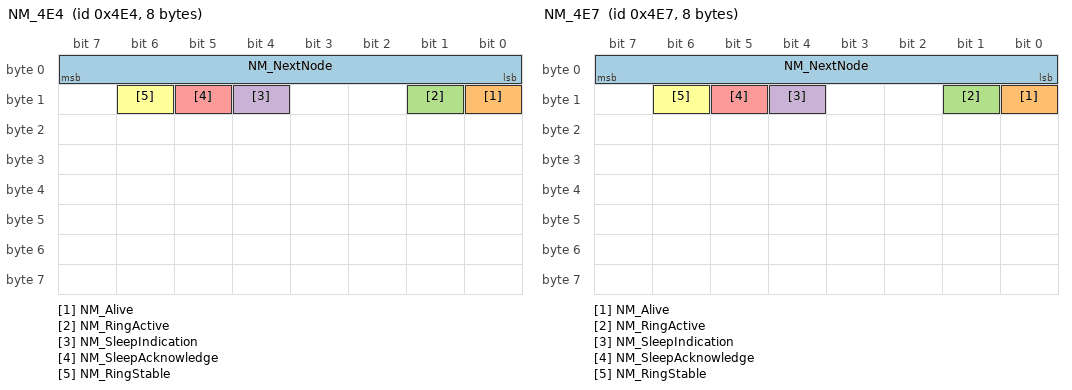
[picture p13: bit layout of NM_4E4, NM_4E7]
BO_ 1252 NM_4E4: 8 PDC
 SG_ NM_NextNode : 0|8@1+ (1,0) [0|255] "" Vector__XXX
 SG_ NM_Alive : 8|1@1+ (1,0) [0|1] "" Vector__XXX
 SG_ NM_RingActive : 9|1@1+ (1,0) [0|1] "" Vector__XXX
 SG_ NM_SleepIndication : 12|1@1+ (1,0) [0|1] "" Vector__XXX
 SG_ NM_SleepAcknowledge : 13|1@1+ (1,0) [0|1] "" Vector__XXX
 SG_ NM_RingStable : 14|1@1+ (1,0) [0|1] "" Vector__XXX

BO_ 1255 NM_4E7: 8 ZBE
 SG_ NM_NextNode : 0|8@1+ (1,0) [0|255] "" Vector__XXX
 SG_ NM_Alive : 8|1@1+ (1,0) [0|1] "" Vector__XXX
 SG_ NM_RingActive : 9|1@1+ (1,0) [0|1] "" Vector__XXX
 SG_ NM_SleepIndication : 12|1@1+ (1,0) [0|1] "" Vector__XXX
 SG_ NM_SleepAcknowledge : 13|1@1+ (1,0) [0|1] "" Vector__XXX
 SG_ NM_RingStable : 14|1@1+ (1,0) [0|1] "" Vector__XXX

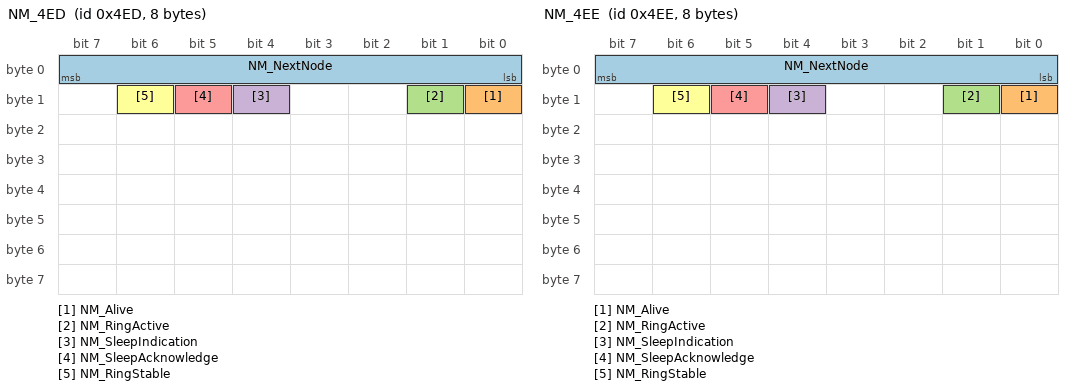
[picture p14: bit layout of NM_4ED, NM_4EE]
BO_ 1261 NM_4ED: 8 SM_FA
 SG_ NM_NextNode : 0|8@1+ (1,0) [0|255] "" Vector__XXX
 SG_ NM_Alive : 8|1@1+ (1,0) [0|1] "" Vector__XXX
 SG_ NM_RingActive : 9|1@1+ (1,0) [0|1] "" Vector__XXX
 SG_ NM_SleepIndication : 12|1@1+ (1,0) [0|1] "" Vector__XXX
 SG_ NM_SleepAcknowledge : 13|1@1+ (1,0) [0|1] "" Vector__XXX
 SG_ NM_RingStable : 14|1@1+ (1,0) [0|1] "" Vector__XXX

BO_ 1262 NM_4EE: 8 SM_BF
 SG_ NM_NextNode : 0|8@1+ (1,0) [0|255] "" Vector__XXX
 SG_ NM_Alive : 8|1@1+ (1,0) [0|1] "" Vector__XXX
 SG_ NM_RingActive : 9|1@1+ (1,0) [0|1] "" Vector__XXX
 SG_ NM_SleepIndication : 12|1@1+ (1,0) [0|1] "" Vector__XXX
 SG_ NM_SleepAcknowledge : 13|1@1+ (1,0) [0|1] "" Vector__XXX
 SG_ NM_RingStable : 14|1@1+ (1,0) [0|1] "" Vector__XXX

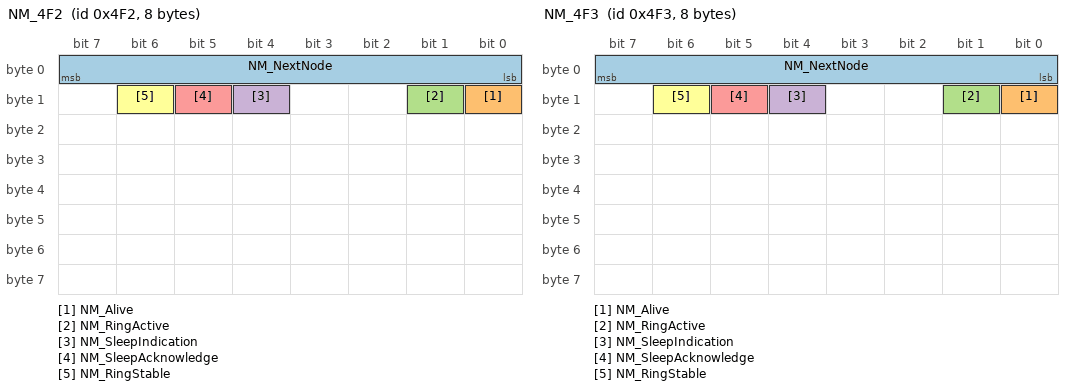
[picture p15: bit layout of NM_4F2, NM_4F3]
BO_ 1266 NM_4F2: 8 FRMFA
 SG_ NM_NextNode : 0|8@1+ (1,0) [0|255] "" Vector__XXX
 SG_ NM_Alive : 8|1@1+ (1,0) [0|1] "" Vector__XXX
 SG_ NM_RingActive : 9|1@1+ (1,0) [0|1] "" Vector__XXX
 SG_ NM_SleepIndication : 12|1@1+ (1,0) [0|1] "" Vector__XXX
 SG_ NM_SleepAcknowledge : 13|1@1+ (1,0) [0|1] "" Vector__XXX
 SG_ NM_RingStable : 14|1@1+ (1,0) [0|1] "" Vector__XXX

BO_ 1267 NM_4F3: 8 CID_C
 SG_ NM_NextNode : 0|8@1+ (1,0) [0|255] "" Vector__XXX
 SG_ NM_Alive : 8|1@1+ (1,0) [0|1] "" Vector__XXX
 SG_ NM_RingActive : 9|1@1+ (1,0) [0|1] "" Vector__XXX
 SG_ NM_SleepIndication : 12|1@1+ (1,0) [0|1] "" Vector__XXX
 SG_ NM_SleepAcknowledge : 13|1@1+ (1,0) [0|1] "" Vector__XXX
 SG_ NM_RingStable : 14|1@1+ (1,0) [0|1] "" Vector__XXX

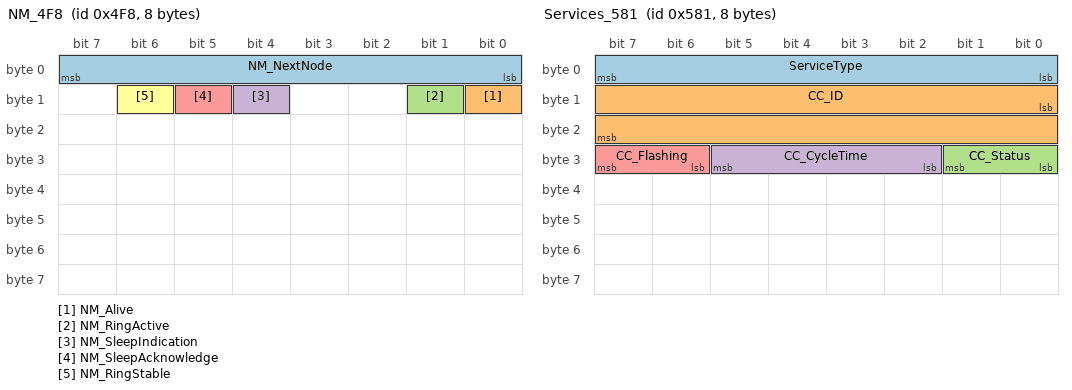
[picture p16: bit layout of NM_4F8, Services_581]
BO_ 1272 NM_4F8: 8 IHKA
 SG_ NM_NextNode : 0|8@1+ (1,0) [0|255] "" Vector__XXX
 SG_ NM_Alive : 8|1@1+ (1,0) [0|1] "" Vector__XXX
 SG_ NM_RingActive : 9|1@1+ (1,0) [0|1] "" Vector__XXX
 SG_ NM_SleepIndication : 12|1@1+ (1,0) [0|1] "" Vector__XXX
 SG_ NM_SleepAcknowledge : 13|1@1+ (1,0) [0|1] "" Vector__XXX
 SG_ NM_RingStable : 14|1@1+ (1,0) [0|1] "" Vector__XXX

BO_ 1408 ServicesKGM: 8 KGM
 SG_ S580_b0 : 0|1@1+ (1,0) [0|1] "" Vector__XXX

BO_ 1409 Services_581: 8 ACSM
 SG_ ServiceType : 0|8@1+ (1,0) [0|255] "" Vector__XXX
 SG_ CC_ID : 8|16@1+ (1,0) [0|65535] "" Vector__XXX
 SG_ CC_Status : 24|2@1+ (1,0) [0|3] "" Vector__XXX
 SG_ CC_CycleTime : 26|4@1+ (1,0) [0|15] "s" Vector__XXX
 SG_ CC_Flashing : 30|2@1+ (1,0) [0|3] "" Vector__XXX

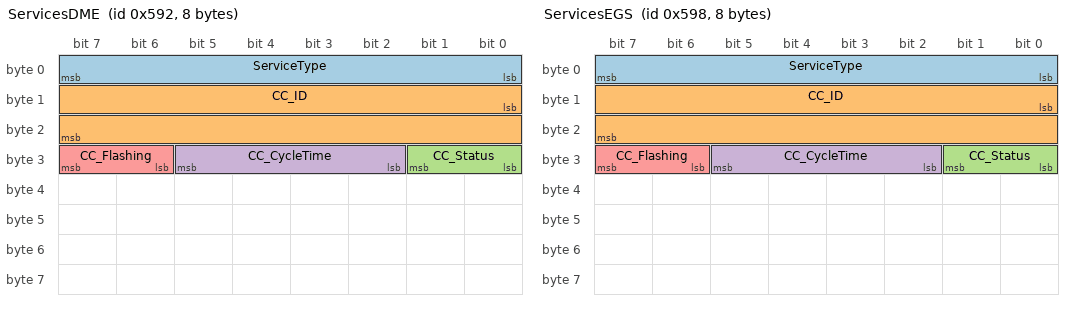
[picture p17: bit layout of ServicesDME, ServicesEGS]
BO_ 1426 ServicesDME: 8 DME
 SG_ ServiceType : 0|8@1+ (1,0) [0|255] "" Vector__XXX
 SG_ CC_ID : 8|16@1+ (1,0) [0|65535] "" Vector__XXX
 SG_ CC_Status : 24|2@1+ (1,0) [0|3] "" Vector__XXX
 SG_ CC_CycleTime : 26|4@1+ (1,0) [0|15] "s" Vector__XXX
 SG_ CC_Flashing : 30|2@1+ (1,0) [0|3] "" Vector__XXX

BO_ 1432 ServicesEGS: 8 EGS
 SG_ ServiceType : 0|8@1+ (1,0) [0|255] "" Vector__XXX
 SG_ CC_ID : 8|16@1+ (1,0) [0|65535] "" Vector__XXX
 SG_ CC_Status : 24|2@1+ (1,0) [0|3] "" Vector__XXX
 SG_ CC_CycleTime : 26|4@1+ (1,0) [0|15] "s" Vector__XXX
 SG_ CC_Flashing : 30|2@1+ (1,0) [0|3] "" Vector__XXX

BO_ 1449 ServicesDSC: 8 DSC
 SG_ S5A9_b0 : 0|1@1+ (1,0) [0|1] "" Vector__XXX

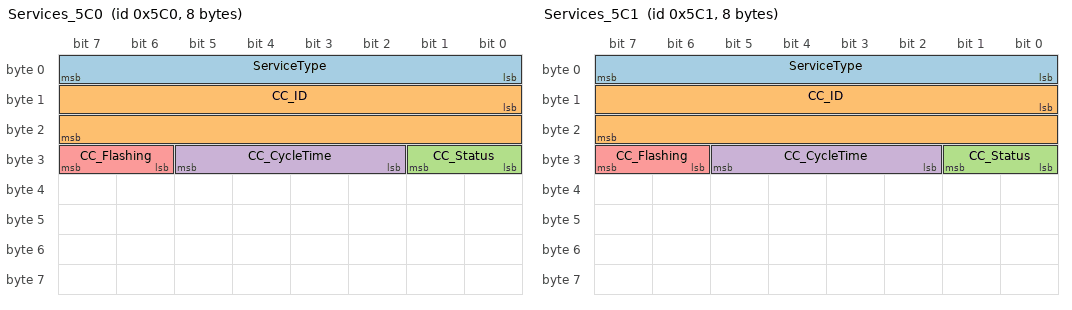
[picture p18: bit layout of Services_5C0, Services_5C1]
BO_ 1472 Services_5C0: 8 CAS
 SG_ ServiceType : 0|8@1+ (1,0) [0|255] "" Vector__XXX
 SG_ CC_ID : 8|16@1+ (1,0) [0|65535] "" Vector__XXX
 SG_ CC_Status : 24|2@1+ (1,0) [0|3] "" Vector__XXX
 SG_ CC_CycleTime : 26|4@1+ (1,0) [0|15] "s" Vector__XXX
 SG_ CC_Flashing : 30|2@1+ (1,0) [0|3] "" Vector__XXX

BO_ 1473 Services_5C1: 8 DWA
 SG_ ServiceType : 0|8@1+ (1,0) [0|255] "" Vector__XXX
 SG_ CC_ID : 8|16@1+ (1,0) [0|65535] "" Vector__XXX
 SG_ CC_Status : 24|2@1+ (1,0) [0|3] "" Vector__XXX
 SG_ CC_CycleTime : 26|4@1+ (1,0) [0|15] "s" Vector__XXX
 SG_ CC_Flashing : 30|2@1+ (1,0) [0|3] "" Vector__XXX

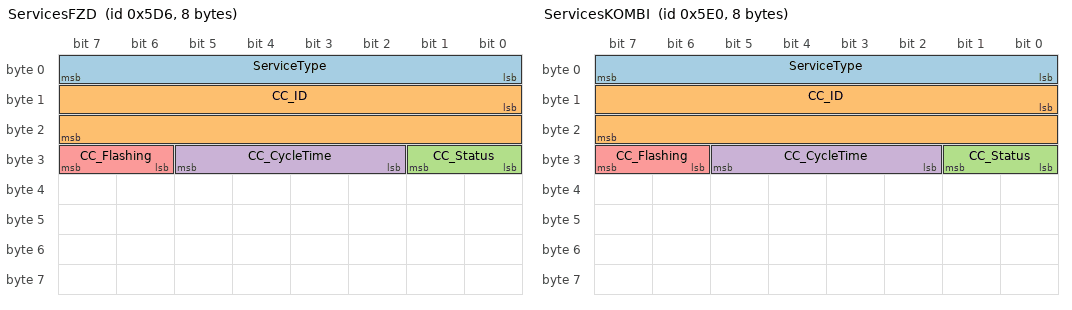
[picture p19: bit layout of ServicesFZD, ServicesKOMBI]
BO_ 1494 ServicesFZD: 8 FZD
 SG_ ServiceType : 0|8@1+ (1,0) [0|255] "" Vector__XXX
 SG_ CC_ID : 8|16@1+ (1,0) [0|65535] "" Vector__XXX
 SG_ CC_Status : 24|2@1+ (1,0) [0|3] "" Vector__XXX
 SG_ CC_CycleTime : 26|4@1+ (1,0) [0|15] "s" Vector__XXX
 SG_ CC_Flashing : 30|2@1+ (1,0) [0|3] "" Vector__XXX

BO_ 1504 ServicesKOMBI: 8 KOMBI
 SG_ ServiceType : 0|8@1+ (1,0) [0|255] "" Vector__XXX
 SG_ CC_ID : 8|16@1+ (1,0) [0|65535] "" Vector__XXX
 SG_ CC_Status : 24|2@1+ (1,0) [0|3] "" Vector__XXX
 SG_ CC_CycleTime : 26|4@1+ (1,0) [0|15] "s" Vector__XXX
 SG_ CC_Flashing : 30|2@1+ (1,0) [0|3] "" Vector__XXX

BO_ 1506 Services_5E2: 8 CCC_GW
 SG_ ServiceType : 0|8@1+ (1,0) [0|255] "" Vector__XXX
 SG_ CC_ID : 8|16@1+ (1,0) [0|65535] "" Vector__XXX
 SG_ CC_Status : 24|2@1+ (1,0) [0|3] "" Vector__XXX
 SG_ CC_CycleTime : 26|4@1+ (1,0) [0|15] "s" Vector__XXX
 SG_ CC_Flashing : 30|2@1+ (1,0) [0|3] "" Vector__XXX

BO_ 1511 Services_5E7: 8 ZBE
 SG_ ServiceType : 0|8@1+ (1,0) [0|255] "" Vector__XXX
 SG_ CC_ID : 8|16@1+ (1,0) [0|65535] "" Vector__XXX
 SG_ CC_Status : 24|2@1+ (1,0) [0|3] "" Vector__XXX
 SG_ CC_CycleTime : 26|4@1+ (1,0) [0|15] "s" Vector__XXX
 SG_ CC_Flashing : 30|2@1+ (1,0) [0|3] "" Vector__XXX

BO_ 1522 ServicesKBM: 8 KBM
 SG_ ServiceType : 0|8@1+ (1,0) [0|255] "" Vector__XXX
 SG_ CC_ID : 8|16@1+ (1,0) [0|65535] "" Vector__XXX
 SG_ CC_Status : 24|2@1+ (1,0) [0|3] "" Vector__XXX
 SG_ CC_CycleTime : 26|4@1+ (1,0) [0|15] "s" Vector__XXX
 SG_ CC_Flashing : 30|2@1+ (1,0) [0|3] "" Vector__XXX

BO_ 1523 Services_5F3: 8 CID_C
 SG_ ServiceType : 0|8@1+ (1,0) [0|255] "" Vector__XXX
 SG_ CC_ID : 8|16@1+ (1,0) [0|65535] "" Vector__XXX
 SG_ CC_Status : 24|2@1+ (1,0) [0|3] "" Vector__XXX
 SG_ CC_CycleTime : 26|4@1+ (1,0) [0|15] "s" Vector__XXX
 SG_ CC_Flashing : 30|2@1+ (1,0) [0|3] "" Vector__XXX

BO_ 1528 Services_5F8: 8 IHKA
 SG_ ServiceType : 0|8@1+ (1,0) [0|255] "" Vector__XXX
 SG_ CC_ID : 8|16@1+ (1,0) [0|65535] "" Vector__XXX
 SG_ CC_Status : 24|2@1+ (1,0) [0|3] "" Vector__XXX
 SG_ CC_CycleTime : 26|4@1+ (1,0) [0|15] "s" Vector__XXX
 SG_ CC_Flashing : 30|2@1+ (1,0) [0|3] "" Vector__XXX

BO_ 1987 CasSteuerung1: 8 CAS

CM_ "BMW E8x/E9x K-CAN (body CAN, 100 kbit/s): frames seen on the K-CAN of an E92 M3 DCT 2011 trace (superwofy/E9X-M-CAN-Integration-Module, MIT), plus K-CAN frames from the superwofy notes. Generated by build_kcan_dbc.py. Signals from BMW_E9x_PT-CAN_full.dbc (frames the JBE copies from PT-CAN) and from the superwofy notes; names from SPdaten JBBF70.prg, community DBC and E65 list. See BMW_E9x_K-CAN.md";
CM_ BO_ 168 "E92 M3 DCT 2011 K-CAN trace (superwofy/E9X-M-CAN-Integration-Module, MIT): 5185 frames, DLC {8: 5185}, median interval 100 ms | Also on PT-CAN (JBE gateway); signals copied from BMW_E9x_PT-CAN_full.dbc | community DBC name: EngineAndBrake | SPdaten JBBF70.prg: 'Drehmoment 1 K-CAN' from DME1/DDE1 | E65 message list: 'Drehmoment 1 K-CAN' from DME1/DDE1";
CM_ SG_ 168 CHK_SUM_TORQ_1_DME "BMW 8-bit checksum: s = sum(other bytes) + (ID & 0xFF) + (ID >> 8); chk = (s & 0xFF) + (s >> 8) - verified 100 % in 320i log | previous name (community DBC): Checksum_EngineAndBrake | BMW name CHK_SUM_TORQ_1_DME - E65 doc (HeinrichG-V12/E65_ReverseEngineering, Bosch MED9.2.1)";
CM_ SG_ 168 ALIV_TORQ_1_DME "Counter TORQ_1 | 4-bit alive counter, counts 0..14 (320i log) | BMW name ALIV_TORQ_1_DME - E65 doc (HeinrichG-V12/E65_ReverseEngineering, Bosch MED9.2.1)";
CM_ SG_ 168 TORQ_AVL "Engine torque without inertia - combustion torque | factor 0.5 Nm (log-verified) | previous name (community DBC): EngineTorque | BMW name TORQ_AVL - E65 doc (HeinrichG-V12/E65_ReverseEngineering, Bosch MED9.2.1)";
CM_ SG_ 168 ST_TORQ_AVL "MK60E5 FW 7846816A (M3) signal (internal var 0xB4), meaning unknown | community DBC defined EngineTorqueWoInterv 24|16@1 here | previous name (firmware field): S0A8_b24 | BMW name ST_TORQ_AVL (status moment intervention) - E65 doc (HeinrichG-V12/E65_ReverseEngineering, Bosch MED9.2.1)";
CM_ SG_ 168 TORQ_AVL_DMEE "BMW name TORQ_AVL_DMEE - E65 doc (HeinrichG-V12/E65_ReverseEngineering, Bosch MED9.2.1); E65 definition, not yet verified on E9x";
CM_ SG_ 168 S0A8_b40 "MK60E5 FW 7846816A (M3) signal (internal var 0xB0), meaning unknown";
CM_ SG_ 168 ST_DMEA_SWO "BMW name ST_DMEA_SWO (acc relevant motronic error) - E65 doc (HeinrichG-V12/E65_ReverseEngineering, Bosch MED9.2.1)";
CM_ SG_ 168 RCPT_ACC_SWO_SYS_DME "BMW name RCPT_ACC_SWO_SYS_DME - E65 doc (HeinrichG-V12/E65_ReverseEngineering, Bosch MED9.2.1); E65 definition, not yet verified on E9x";
CM_ SG_ 168 ST_RCPT_ENG_ACC "BMW name ST_RCPT_ENG_ACC - E65 doc (HeinrichG-V12/E65_ReverseEngineering, Bosch MED9.2.1)";
CM_ SG_ 168 ST_RCPT_ENG_ARS "BMW name ST_RCPT_ENG_ARS - E65 doc (HeinrichG-V12/E65_ReverseEngineering, Bosch MED9.2.1)";
CM_ SG_ 168 ST_RCPT_ENG_DSC "BMW name ST_RCPT_ENG_DSC - E65 doc (HeinrichG-V12/E65_ReverseEngineering, Bosch MED9.2.1)";
CM_ SG_ 168 ST_RCPT_ENG_EGS "BMW name ST_RCPT_ENG_EGS - E65 doc (HeinrichG-V12/E65_ReverseEngineering, Bosch MED9.2.1)";
CM_ SG_ 168 ST_OBD_CTFN_GRB "BMW name ST_OBD_CTFN_GRB - E65 doc (HeinrichG-V12/E65_ReverseEngineering, Bosch MED9.2.1); E65 definition, not yet verified on E9x";
CM_ SG_ 168 ST_CT_BRPD_DME "MK60E5 FW 7846816A (M3) signal (internal var 0xAC), meaning unknown | community DBC flags here: bit 61 = BrakePressed, bit 62 = Brake_active2 | previous name (firmware field): S0A8_b61 | BMW name ST_CT_BRPD_DME - E65 doc (HeinrichG-V12/E65_ReverseEngineering, Bosch MED9.2.1)";
CM_ BO_ 169 "E92 M3 DCT 2011 K-CAN trace (superwofy/E9X-M-CAN-Integration-Module, MIT): 5185 frames, DLC {8: 5185}, median interval 100 ms | Also on PT-CAN (JBE gateway); signals copied from BMW_E9x_PT-CAN_full.dbc | community DBC name: Torque2 | SPdaten JBBF70.prg: 'Drehmoment 2' from DME1/DDE1 | E65 message list: 'Drehmoment 2' from DME1/DDE1";
CM_ SG_ 169 CHKSM_TORQ_2_DME "BMW 8-bit checksum: s = sum(other bytes) + (ID & 0xFF) + (ID >> 8); chk = (s & 0xFF) + (s >> 8) - verified 100 % in 320i log | BMW name CHKSM_TORQ_2_DME - E65 doc (HeinrichG-V12/E65_ReverseEngineering, Bosch MED9.2.1)";
CM_ SG_ 169 ALIV_TORQ_2_DME "Counter TORQ_2 | 4-bit alive counter, counts 0..14 (320i log) | BMW name ALIV_TORQ_2_DME - E65 doc (HeinrichG-V12/E65_ReverseEngineering, Bosch MED9.2.1)";
CM_ SG_ 169 ST_SW_LEV_RPM "BMW name ST_SW_LEV_RPM - E65 doc (HeinrichG-V12/E65_ReverseEngineering, Bosch MED9.2.1)";
CM_ SG_ 169 ST_INFS "BMW name ST_INFS - E65 doc (HeinrichG-V12/E65_ReverseEngineering, Bosch MED9.2.1)";
CM_ SG_ 169 TORQ_AVL_MIN "BMW name TORQ_AVL_MIN - E65 doc (HeinrichG-V12/E65_ReverseEngineering, Bosch MED9.2.1)";
CM_ SG_ 169 TORQ_AVL_MAX "BMW name TORQ_AVL_MAX - E65 doc (HeinrichG-V12/E65_ReverseEngineering, Bosch MED9.2.1)";
CM_ SG_ 169 TORQ_AVL_SPAR_NEG "BMW name TORQ_AVL_SPAR_NEG - E65 doc (HeinrichG-V12/E65_ReverseEngineering, Bosch MED9.2.1)";
CM_ SG_ 169 TORQ_AVL_SPAR_POS "BMW name TORQ_AVL_SPAR_POS - E65 doc (HeinrichG-V12/E65_ReverseEngineering, Bosch MED9.2.1)";
CM_ BO_ 170 "E92 M3 DCT 2011 K-CAN trace (superwofy/E9X-M-CAN-Integration-Module, MIT): 5185 frames, DLC {8: 5185}, median interval 100 ms | Also on PT-CAN (JBE gateway); signals copied from BMW_E9x_PT-CAN_full.dbc | community DBC name: AccPedal | SPdaten JBBF70.prg: 'Drehmoment 3 K-CAN' from DME1/DDE1 | E65 message list: 'Drehmoment 3 K-CAN' from DME1/DDE1";
CM_ SG_ 170 CHKSM_TORQ_3_DME "BMW 8-bit checksum: s = sum(other bytes) + (ID & 0xFF) + (ID >> 8); chk = (s & 0xFF) + (s >> 8) - verified 100 % in 320i log | previous name (community DBC): Checksum_170 | BMW name CHKSM_TORQ_3_DME - E65 doc (HeinrichG-V12/E65_ReverseEngineering, Bosch MED9.2.1)";
CM_ SG_ 170 ALIV_TORQ_3_DME "4-bit alive counter, counts 0..14 (320i log) | previous name (community DBC): Counter_170 | BMW name ALIV_TORQ_3_DME - E65 doc (HeinrichG-V12/E65_ReverseEngineering, Bosch MED9.2.1)";
CM_ SG_ 170 TORQ_DVCH "'Drehmoment 3' (BN2000). Scale 0.5 Nm assumed like 0x0A8/0x0A9; -0.5..3 Nm at idle. Replaces community AcceleratorPedalPercentage 16|16, which overlaps this field (phantom 10.2 % whenever the torque is negative) | previous name (firmware field): TORQ_3 | BMW name TORQ_DVCH - E65 doc (HeinrichG-V12/E65_ReverseEngineering, Bosch MED9.2.1)";
CM_ SG_ 170 ANG_ACPD "Accelerator pedal angle byte read by DSC (brake standby, TIS); 0 at idle; scaling unknown | previous name (firmware field): PedalAngle_raw | BMW name ANG_ACPD (accelerator pedal angle) - E65 doc (HeinrichG-V12/E65_ReverseEngineering, Bosch MED9.2.1)";
CM_ SG_ 170 RPM_ENG "previous name (community DBC): EngineSpeed | BMW name RPM_ENG - E65 doc (HeinrichG-V12/E65_ReverseEngineering, Bosch MED9.2.1)";
CM_ SG_ 170 RPM_ENG_ERR "MK60E5 FW 7846816A (M3) signal (internal var 0x82), meaning unknown | previous name (firmware field): S0AA_b48 | BMW name RPM_ENG_ERR - E65 doc (HeinrichG-V12/E65_ReverseEngineering, Bosch MED9.2.1)";
CM_ SG_ 170 ST_IDLG_ENG "MK60E5 FW 7846816A (M3) signal (internal var 0x98), meaning unknown | community DBC flags here: bit 50 = ThrottlelPressed | previous name (firmware field): S0AA_b50 | BMW name ST_IDLG_ENG - E65 doc (HeinrichG-V12/E65_ReverseEngineering, Bosch MED9.2.1)";
CM_ SG_ 170 ST_CLCTR_V "MK60E5 FW 7846816A (M3) signal (internal var 0x92), meaning unknown | community DBC flags here: bit 52 = AcceleratorPedalPressed, bit 53 = KickDownPressed, bit 54 = CruisePedalActive, bit 55 = CruisePedalInactive | previous name (firmware field): S0AA_b52 | BMW name ST_CLCTR_V - E65 doc (HeinrichG-V12/E65_ReverseEngineering, Bosch MED9.2.1); the community DBC flags were bit readings of this enum: bit 52 = pedal pressed (9), bit 53 = transgress/kickdown (0xA/0xB), bit 54 = cruise regulation (4..7), bit 55 = no cruise/ACC regulation (8..0xB)";
CM_ SG_ 170 RQAM_FU "BMW name RQAM_FU - E65 doc (HeinrichG-V12/E65_ReverseEngineering, Bosch MED9.2.1); E65 definition, not yet verified on E9x";
CM_ BO_ 192 "E92 M3 DCT 2011 K-CAN trace (superwofy/E9X-M-CAN-Integration-Module, MIT): 2593 frames, DLC {2: 2593}, median interval 200 ms | SPdaten JBBF70.prg: 'Alive Zentrales Gateway' from JBBF | E65 message list: 'Alive Zentrales Gateway' from KGM | undefined bits changing in the trace: [0, 1, 2, 3]";
CM_ BO_ 196 "E92 M3 DCT 2011 K-CAN trace (superwofy/E9X-M-CAN-Integration-Module, MIT): 2593 frames, DLC {7: 2593}, median interval 200 ms | Also on PT-CAN (JBE gateway); signals copied from BMW_E9x_PT-CAN_full.dbc | community DBC name: SteeringWheelAngle | SPdaten JBBF70.prg: 'Lenkradwinkel K-CAN' from EHB3 | E65 message list: 'Lenkradwinkel K-CAN' from DXC_RB/DSC_RB/DSC_CT";
CM_ SG_ 196 SteeringPosition "Scale 0.04395 deg per bit (angle: same raw value in 0x0C4 (DSC) and 0x0C8 (SZL) in the E92 M3 K-CAN trace; same unit as F-CAN 0x0C9 LW_OBEN (DSC_87.prg) assumed (inference); E65 doc STWA); previous community factor 0.0428317";
CM_ SG_ 196 S0C4_b16 "MK60E5 FW 7846816A (M3) signal (internal var 0x52), meaning unknown";
CM_ SG_ 196 SteeringSpeed "Scale 0.04395 deg/s per bit (angle rate: scale from the E65 doc (STWA_V), not verified on E9x); previous community factor 0.0428317";
CM_ SG_ 196 S0C4_b40 "MK60E5 FW 7846816A (M3) signal (internal var 0x54), meaning unknown";
CM_ SG_ 196 S0C4_b48 "MK60E5 FW 7846816A (M3) signal (internal var 0x2E), meaning unknown";
CM_ SG_ 196 S0C4_b50 "MK60E5 FW 7846816A (M3) signal (internal var 0x5E), meaning unknown";
CM_ BO_ 200 "E92 M3 DCT 2011 K-CAN trace (superwofy/E9X-M-CAN-Integration-Module, MIT): 2583 frames, DLC {6: 2583}, median interval 200 ms | Also on PT-CAN (JBE gateway); signals copied from BMW_E9x_PT-CAN_full.dbc | community DBC name: SteeringWheelAngle_slow | SPdaten JBBF70.prg: 'Lenkradwinkel Oben F-CAN' from SZL_LWS/SZL_LWS | superwofy note: '0xC8 Steering angle.txt' | E65 message list: 'Lenkradwinkel Oben K-CAN' from SZL_LWS | undefined bits changing in the trace: [18, 44, 45, 46, 47]";
CM_ SG_ 200 SteeringPosition "Scale 0.04395 deg per bit (angle: same raw value in 0x0C4 (DSC) and 0x0C8 (SZL) in the E92 M3 K-CAN trace; same unit as F-CAN 0x0C9 LW_OBEN (DSC_87.prg) assumed (inference); E65 doc STWA); previous community factor 0.0428317";
CM_ SG_ 200 SteeringSpeed "Scale 0.04395 deg/s per bit (angle rate: scale from the E65 doc (STWA_V), not verified on E9x); previous community factor 0.0428317";
CM_ BO_ 206 "E92 M3 DCT 2011 K-CAN trace (superwofy/E9X-M-CAN-Integration-Module, MIT): 5184 frames, DLC {8: 5184}, median interval 100 ms | Also on PT-CAN (JBE gateway); signals copied from BMW_E9x_PT-CAN_full.dbc | community DBC name: GESCHWINDIGKEIT_RAD | SPdaten JBBF70.prg: 'Radgeschwindigkeit F-CAN' from EHB3/EHB3 | E65 message list: 'Radgeschwindigkeit K-CAN' from DXC_RB/DSC_RB/DSC_CT";
CM_ SG_ 206 V_WHL_FLH "BMW name V_WHL_FLH - E65 doc (HeinrichG-V12/E65_ReverseEngineering, Bosch MED9.2.1)";
CM_ SG_ 206 V_WHL_FRH "BMW name V_WHL_FRH - E65 doc (HeinrichG-V12/E65_ReverseEngineering, Bosch MED9.2.1)";
CM_ SG_ 206 V_WHL_RLH "BMW name V_WHL_RLH - E65 doc (HeinrichG-V12/E65_ReverseEngineering, Bosch MED9.2.1)";
CM_ SG_ 206 V_WHL_RRH "BMW name V_WHL_RRH - E65 doc (HeinrichG-V12/E65_ReverseEngineering, Bosch MED9.2.1)";
CM_ BO_ 215 "E92 M3 DCT 2011 K-CAN trace (superwofy/E9X-M-CAN-Integration-Module, MIT): 2063 frames, DLC {2: 2063}, median interval 200 ms | SPdaten JBBF70.prg: 'Alive Zähler Sicherheit' from ACSM | E65 message list: 'Alive ZÃ¤hler Sicherheit' from ACSM | undefined bits changing in the trace: [0, 1, 2, 3, 4, 5, 6, 7]";
CM_ BO_ 226 "E92 M3 DCT 2011 K-CAN trace (superwofy/E9X-M-CAN-Integration-Module, MIT): 259 frames, DLC {8: 259}, median interval 160 ms | SPdaten JBBF70.prg: 'Status Zentralverriegelung BFT' from JBBF | E65 message list: 'Status Zentralverriegelung BFT' from KGM | undefined bits changing in the trace: [1]";
CM_ BO_ 230 "E92 M3 DCT 2011 K-CAN trace (superwofy/E9X-M-CAN-Integration-Module, MIT): 255 frames, DLC {8: 255}, median interval 160 ms | SPdaten JBBF70.prg: 'Status Zentralverriegelung BFTH' from JBBF | E65 message list: 'Status Zentralverriegelung BFTH' from KBM | undefined bits changing in the trace: [1]";
CM_ BO_ 234 "E92 M3 DCT 2011 K-CAN trace (superwofy/E9X-M-CAN-Integration-Module, MIT): 255 frames, DLC {8: 255}, median interval 160 ms | SPdaten JBBF70.prg: 'Status Zentralverriegelung FAT' from JBBF | E65 message list: 'Status Zentralverriegelung FAT' from KGM | undefined bits changing in the trace: [1, 24]";
CM_ BO_ 238 "E92 M3 DCT 2011 K-CAN trace (superwofy/E9X-M-CAN-Integration-Module, MIT): 257 frames, DLC {8: 257}, median interval 160 ms | SPdaten JBBF70.prg: 'Status Zentralverriegelung FATH' from JBBF | E65 message list: 'Status Zentralverriegelung FATH' from KBM | undefined bits changing in the trace: [1]";
CM_ BO_ 242 "E92 M3 DCT 2011 K-CAN trace (superwofy/E9X-M-CAN-Integration-Module, MIT): 62 frames, DLC {8: 62}, median interval 10003 ms | SPdaten JBBF70.prg: 'Status Zentralverriegelung HK' from JBBF | E65 message list: 'Status Zentralverriegelung HK' from KBM | undefined bits changing in the trace: [1, 2, 3]";
CM_ BO_ 246 "E92 M3 DCT 2011 K-CAN trace (superwofy/E9X-M-CAN-Integration-Module, MIT): 8 frames, DLC {2: 8}, median interval 150 ms | E65 message list: 'Steuerung AuÃŸenspiegel' from KGM";
CM_ BO_ 250 "E92 M3 DCT 2011 K-CAN trace (superwofy/E9X-M-CAN-Integration-Module, MIT): 12 frames, DLC {3: 12}, median interval 110 ms | SPdaten JBBF70.prg: 'Steuerung Fensterheber FAT' from FRMFA | E65 message list: 'Steuerung Fensterheber FAT' from KGM | undefined bits changing in the trace: [0, 1, 2]";
CM_ BO_ 304 "E92 M3 DCT 2011 K-CAN trace (superwofy/E9X-M-CAN-Integration-Module, MIT): 23761 frames, DLC {5: 23761}, median interval 100 ms | Also on PT-CAN (JBE gateway); signals copied from BMW_E9x_PT-CAN_full.dbc | community DBC name: TerminalStatus | SPdaten JBBF70.prg: 'Klemmenstatus' from CAS/CAS | E65 message list: 'Klemmenstatus' from CAS | undefined bits changing in the trace: [30, 31]";
CM_ SG_ 304 ST_KL_R "MK60E5 FW 7846816A (M3) signal (internal var 0x7A), meaning unknown | previous name (firmware field): S130_b0 | BMW name ST_KL_R - E65 doc (HeinrichG-V12/E65_ReverseEngineering, Bosch MED9.2.1)";
CM_ SG_ 304 ST_KL_15 "MK60E5 FW 7846816A (M3) signal (internal var 0xA2), meaning unknown | previous name (firmware field): S130_b2 | BMW name ST_KL_15 - E65 doc (HeinrichG-V12/E65_ReverseEngineering, Bosch MED9.2.1)";
CM_ SG_ 304 ST_KL_50 "MK60E5 FW 7846816A (M3) signal (internal var 0xA3), meaning unknown | previous name (firmware field): S130_b4 | BMW name ST_KL_50 - E65 doc (HeinrichG-V12/E65_ReverseEngineering, Bosch MED9.2.1)";
CM_ SG_ 304 ST_KEY_VLD "BMW name ST_KEY_VLD - E65 doc (HeinrichG-V12/E65_ReverseEngineering, Bosch MED9.2.1); replaces S130_b6 6|1 (community DBC ranks below E65)";
CM_ SG_ 304 NO_KEY "BMW name NO_KEY - E65 doc (HeinrichG-V12/E65_ReverseEngineering, Bosch MED9.2.1); E65 definition, not yet verified on E9x";
CM_ SG_ 304 ST_KEY_TYP "BMW name ST_KEY_TYP - E65 doc (HeinrichG-V12/E65_ReverseEngineering, Bosch MED9.2.1); E65 definition, not yet verified on E9x";
CM_ SG_ 304 ST_KEY_PLGD "BMW name ST_KEY_PLGD - E65 doc (HeinrichG-V12/E65_ReverseEngineering, Bosch MED9.2.1); E65 definition, not yet verified on E9x";
CM_ SG_ 304 ST_VHIM "BMW name ST_VHIM - E65 doc (HeinrichG-V12/E65_ReverseEngineering, Bosch MED9.2.1); E65 definition, not yet verified on E9x";
CM_ SG_ 304 ST_LOKG_STCO "BMW name ST_LOKG_STCO - E65 doc (HeinrichG-V12/E65_ReverseEngineering, Bosch MED9.2.1); E65 definition, not yet verified on E9x";
CM_ SG_ 304 PO_ID_PU "BMW name PO_ID_PU - E65 doc (HeinrichG-V12/E65_ReverseEngineering, Bosch MED9.2.1); E65 definition, not yet verified on E9x";
CM_ SG_ 304 ST_PSVA_ACV "BMW name ST_PSVA_ACV - E65 doc (HeinrichG-V12/E65_ReverseEngineering, Bosch MED9.2.1); E65 definition, not yet verified on E9x";
CM_ SG_ 304 ST_ILK_COD_BM "BMW name ST_ILK_COD_BM - E65 doc (HeinrichG-V12/E65_ReverseEngineering, Bosch MED9.2.1); E65 definition, not yet verified on E9x";
CM_ SG_ 304 ALIV_KL "4-bit alive counter, counts 0..14 (320i log) | previous name (community DBC): Counter_304 | BMW name ALIV_KL - E65 doc (HeinrichG-V12/E65_ReverseEngineering, Bosch MED9.2.1)";
CM_ SG_ 304 CHKSM_KL "BMW 4-bit checksum: s = fold8(sum(bytes, checksum nibble = 0) + 0x31); chk = ((s >> 4) + (s & 0xF)) & 0xF - verified 100 % in 320i log | previous name (community DBC): Checksum_304 | BMW name CHKSM_KL - E65 doc (HeinrichG-V12/E65_ReverseEngineering, Bosch MED9.2.1)";
CM_ BO_ 309 "E92 M3 DCT 2011 K-CAN trace (superwofy/E9X-M-CAN-Integration-Module, MIT): 41 frames, DLC {2: 41}, median interval 10000 ms | Also on PT-CAN (JBE gateway); signals copied from BMW_E9x_PT-CAN_full.dbc | community DBC name: CrashDisconnectControl | SPdaten JBBF70.prg: 'Steuerung Crashabschaltung EKP' from ACSM | E65 message list: 'Steuerung Crashabschaltung EKP' from ACSM";
CM_ SG_ 309 CTR_CR_SWO_EKP "BMW name CTR_CR_SWO_EKP (Steuerung Crash Abschaltung EKP) - MEVD17.2 function description 15.3.3.1-DSPLECU_CO.md; range/values: 0101b - Keine 1010b - 1111b - Crashabschaltung EKP Crashabschaltung EKP Signal ungültig; raw value (no conversion given)";
CM_ BO_ 370 "E92 M3 DCT 2011 K-CAN trace (superwofy/E9X-M-CAN-Integration-Module, MIT): 96 frames, DLC {5: 96}, median interval 5000 ms | SPdaten JBBF70.prg: 'Quittierung Anforderung Kombi' from CHAMP_M_ASK2/CCC_GW | E65 message list: 'Quittierung Anforderung Kombi' from M_ASK/CCC_GW | undefined bits changing in the trace: [0, 1, 2, 3, 4, 5, 6, 7, 8, 9, 10, 11, 12, 13, 14, 15, 16, 17, 18, 19, 20, 21, 22, 23, 24, 25, 26, 27, 29, 30, 31, 32]";
CM_ BO_ 373 "E92 M3 DCT 2011 K-CAN trace (superwofy/E9X-M-CAN-Integration-Module, MIT): 5185 frames, DLC {3: 5185}, median interval 100 ms | Also on PT-CAN (JBE gateway); signals copied from BMW_E9x_PT-CAN_full.dbc | community DBC name: Display_motor_data | SPdaten JBBF70.prg: 'Anzeige Motordaten' from DME1/DDE1 | undefined bits changing in the trace: [0, 1, 2, 3, 10, 11, 12, 13, 14, 15, 16, 17, 18, 19, 20]";
CM_ BO_ 405 "E92 M3 DCT 2011 K-CAN trace (superwofy/E9X-M-CAN-Integration-Module, MIT): 60 frames, DLC {2: 60}, median interval 9998 ms | SPdaten JBBF70.prg: 'Bedienung Taster MSA' from IHKA | undefined bits changing in the trace: [0, 2]";
CM_ BO_ 414 "E92 M3 DCT 2011 K-CAN trace (superwofy/E9X-M-CAN-Integration-Module, MIT): 2644 frames, DLC {8: 2644}, median interval 200 ms | Also on PT-CAN (JBE gateway); signals copied from BMW_E9x_PT-CAN_full.dbc | community DBC name: STAT_DSC | SPdaten JBBF70.prg: 'Status DSC K-CAN' from EHB3 | E65 message list: 'Status DSC K-CAN' from DXC_RB/DSC_RB/DSC_CT";
CM_ SG_ 414 ST_CLCTR "BMW name ST_CLCTR - E65 doc (HeinrichG-V12/E65_ReverseEngineering, Bosch MED9.2.1) | superwofy/E9X-M-CAN-Integration-Module notes (MIT): firmware evaluate_dsc_status(): bit field of active regulations, 0x01 ABS, 0x02 ASC, 0x04 DSC, 0x08 HBA, 0x10 MSR, 0x20 EBV, 0x40 dyno mode, 0xFF invalid; bits combine";
CM_ SG_ 414 S19E_b8 "MK60E5 FW 7846816A (M3) signal (internal var 0x37), meaning unknown";
CM_ SG_ 414 ST_DSC "BMW name ST_DSC - E65 doc (HeinrichG-V12/E65_ReverseEngineering, Bosch MED9.2.1) | superwofy/E9X-M-CAN-Integration-Module notes (MIT): firmware evaluate_dsc_status(): 0 DSC on, 1 DSC off, 2 DSC fault, 4 DTC/MDM, 5 ABS fault, 6 undervoltage, 7 invalid; the E92 M3 trace shows 0, 1, 2, 4 and 6";
CM_ SG_ 414 S19E_b14 "MK60E5 FW 7846816A (M3) signal (internal var 0x3E), meaning unknown";
CM_ SG_ 414 S19E_b16 "MK60E5 FW 7846816A (M3) signal (internal var 0x43), meaning unknown";
CM_ SG_ 414 S19E_b18 "MK60E5 FW 7846816A (M3) signal (internal var 0x41), meaning unknown";
CM_ SG_ 414 ALIV_19E "MK60E5 FW 7846816A (M3) signal (internal var 0x29), meaning unknown | 4-bit alive counter, counts 0..14 (320i log); advances only about every 2nd frame";
CM_ SG_ 414 S19E_b24 "MK60E5 FW 7846816A (M3) signal (internal var 0x12), meaning unknown";
CM_ SG_ 414 S19E_b26 "MK60E5 FW 7846816A (M3) signal (internal var 0x2C), meaning unknown";
CM_ SG_ 414 S19E_b28 "MK60E5 FW 7846816A (M3) signal (internal var 0x51), meaning unknown";
CM_ SG_ 414 S19E_b30 "MK60E5 FW 7846816A (M3) signal (internal var 0x3A), meaning unknown";
CM_ SG_ 414 ST_DCRN_AVL "BMW name ST_DCRN_AVL - E65 doc (HeinrichG-V12/E65_ReverseEngineering, Bosch MED9.2.1)";
CM_ SG_ 414 S19E_b36 "MK60E5 FW 7846816A (M3) signal (internal var 0x39), meaning unknown";
CM_ SG_ 414 S19E_b38 "MK60E5 FW 7846816A (M3) signal (internal var 0x46), meaning unknown";
CM_ SG_ 414 S19E_b40 "MK60E5 FW 7846816A (M3) signal (internal var 0x47), meaning unknown";
CM_ SG_ 414 S19E_b42 "MK60E5 FW 7846816A (M3) signal (internal var 0x38), meaning unknown";
CM_ SG_ 414 S19E_b44 "MK60E5 FW 7846816A (M3) signal (internal var 0x1F), meaning unknown";
CM_ SG_ 414 S19E_b46 "MK60E5 FW 7846816A (M3) signal (internal var 0x42), meaning unknown";
CM_ SG_ 414 S19E_b48 "MK60E5 FW 7846816A (M3) signal (internal var 0x36), meaning unknown";
CM_ SG_ 414 CHKSM_19E "BMW 8-bit checksum: s = sum(other bytes) + (ID & 0xFF) + (ID >> 8); chk = (s & 0xFF) + (s >> 8) - verified 100 % in 320i log";
CM_ BO_ 416 "E92 M3 DCT 2011 K-CAN trace (superwofy/E9X-M-CAN-Integration-Module, MIT): 5200 frames, DLC {8: 5200}, median interval 100 ms | Also on PT-CAN (JBE gateway); signals copied from BMW_E9x_PT-CAN_full.dbc | community DBC name: GESCHWINDIGKEIT | SPdaten JBBF70.prg: 'Geschwindigkeit K-CAN' from EHB3 | superwofy note: '0x1A0 Speed.txt' | E65 message list: 'Geschwindigkeit K-CAN' from DXC_RB/DSC_RB/DSC_CT";
CM_ SG_ 416 V_VEH "BMW name V_VEH - E65 doc (HeinrichG-V12/E65_ReverseEngineering, Bosch MED9.2.1)";
CM_ SG_ 416 ST_VEH_DVCO "BMW name ST_VEH_DVCO (status vehicle driver choice) - E65 doc (HeinrichG-V12/E65_ReverseEngineering, Bosch MED9.2.1)";
CM_ SG_ 416 ACLH_VEH_LN_DSC "BMW name ACLH_VEH_LN_DSC (horizontal longitudinal acceleration) - E65 doc (HeinrichG-V12/E65_ReverseEngineering, Bosch MED9.2.1)";
CM_ SG_ 416 ACLH_VEH_ACRO_DSC "BMW name ACLH_VEH_ACRO_DSC (horizontal cross acceleration) - E65 doc (HeinrichG-V12/E65_ReverseEngineering, Bosch MED9.2.1)";
CM_ SG_ 416 ANGV_YAW_DSC "BMW name ANGV_YAW_DSC (yaw angle) - E65 doc (HeinrichG-V12/E65_ReverseEngineering, Bosch MED9.2.1)";
CM_ SG_ 416 ALIV_V "4-bit alive counter, counts 0..14 (320i log) | BMW name ALIV_V - E65 doc (HeinrichG-V12/E65_ReverseEngineering, Bosch MED9.2.1)";
CM_ SG_ 416 CHKSM_V_V "BMW 8-bit checksum: s = sum(other bytes) + (ID & 0xFF) + (ID >> 8); chk = (s & 0xFF) + (s >> 8) - verified 100 % in 320i log | BMW name CHKSM_V_V - E65 doc (HeinrichG-V12/E65_ReverseEngineering, Bosch MED9.2.1)";
CM_ BO_ 422 "E92 M3 DCT 2011 K-CAN trace (superwofy/E9X-M-CAN-Integration-Module, MIT): 5184 frames, DLC {8: 5184}, median interval 100 ms | Also on PT-CAN (JBE gateway); signals copied from BMW_E9x_PT-CAN_full.dbc | community DBC name: DistanceRoute | SPdaten JBBF70.prg: 'Wegstrecke' from EHB3 | E65 message list: 'Wegstrecke' from DXC_RB/DSC_RB/DSC_CT";
CM_ SG_ 422 S1A6_b0 "MK60E5 FW 7846816A (M3) signal (internal var 0x6D), meaning unknown";
CM_ SG_ 422 S1A6_b16 "MK60E5 FW 7846816A (M3) signal (internal var 0x23), meaning unknown";
CM_ SG_ 422 S1A6_b32 "MK60E5 FW 7846816A (M3) signal (internal var 0x24), meaning unknown";
CM_ SG_ 422 S1A6_b48 "MK60E5 FW 7846816A (M3) signal (internal var 0x25), meaning unknown";
CM_ BO_ 426 "E92 M3 DCT 2011 K-CAN trace (superwofy/E9X-M-CAN-Integration-Module, MIT): 1 frames, DLC {8: 1} | SPdaten JBBF70.prg: 'Effekt ErgoCommander' from CHAMP_M_ASK2/CCC_GW | E65 message list: 'Effekt ErgoCommander' from M_ASK/CCC_GW";
CM_ BO_ 436 "E92 M3 DCT 2011 K-CAN trace (superwofy/E9X-M-CAN-Integration-Module, MIT): 4128 frames, DLC {8: 4128}, median interval 100 ms | Also on PT-CAN (JBE gateway); signals copied from BMW_E9x_PT-CAN_full.dbc | community DBC name: InstrumentClusterStatus_KOMBI | SPdaten JBBF70.prg: 'Status Kombi' from Kombi | E65 message list: 'Status Kombi' from Kombi | undefined bits changing in the trace: [33, 34, 38, 40, 42, 46]";
CM_ SG_ 436 V_VEH_SPDM "MK60E5 FW 7846816A (M3) signal (internal var 0x77), meaning unknown | previous name (firmware field): S1B4_b0 | BMW name V_VEH_SPDM - E65 doc (HeinrichG-V12/E65_ReverseEngineering, Bosch MED9.2.1)";
CM_ SG_ 436 ST_UN_V_SPDM "MK60E5 FW 7846816A (M3) signal (internal var 0xC0), meaning unknown | previous name (firmware field): S1B4_b12 | BMW name ST_UN_V_SPDM (status unit speedometer) - E65 doc (HeinrichG-V12/E65_ReverseEngineering, Bosch MED9.2.1)";
CM_ SG_ 436 S1B4_b16 "MK60E5 FW 7846816A (M3) signal (internal var 0xB2), meaning unknown";
CM_ SG_ 436 ST_INTF_CCTRA_KL "MK60E5 FW 7846816A (M3) signal (internal var 0x91), meaning unknown | previous name (firmware field): S1B4_b18 | BMW name ST_INTF_CCTRA_KL (status unit speedometer) - E65 doc (HeinrichG-V12/E65_ReverseEngineering, Bosch MED9.2.1)";
CM_ SG_ 436 ALIV_COU_KL "MK60E5 FW 7846816A (M3) signal (internal var 0xCA), meaning unknown | previous name (firmware field): S1B4_b24 | BMW name ALIV_COU_KL - E65 doc (HeinrichG-V12/E65_ReverseEngineering, Bosch MED9.2.1)";
CM_ SG_ 436 ST_WALI_ENG "BMW name ST_WALI_ENG (MIL indicator) - E65 doc (HeinrichG-V12/E65_ReverseEngineering, Bosch MED9.2.1); E65 definition, not yet verified on E9x";
CM_ SG_ 436 S1B4_b48 "MK60E5 FW 7846816A (M3) signal (internal var 0xA0), meaning unknown";
CM_ SG_ 436 CHKSM_1B4 "BMW 8-bit checksum: s = sum(other bytes) + (ID & 0xFF) + (ID >> 8); chk = (s & 0xFF) + (s >> 8) - verified 100 % in 320i log";
CM_ BO_ 437 "E92 M3 DCT 2011 K-CAN trace (superwofy/E9X-M-CAN-Integration-Module, MIT): 628 frames, DLC {7: 628}, median interval 1000 ms | Also on PT-CAN (JBE gateway); signals copied from BMW_E9x_PT-CAN_full.dbc | community DBC name: HeatFlow_LoadTorqueClimate | SPdaten JBBF70.prg: 'Wärmestrom/Lastmoment Klima' from IHKA | E65 message list: 'WÃ¤rmestrom/Lastmoment Klima' from IHKA";
CM_ SG_ 437 HTFL_RQ_AIC "BMW name HTFL_RQ_AIC (not used at the moment, always 0xFF) - E65 doc (HeinrichG-V12/E65_ReverseEngineering, Bosch MED9.2.1); E65 definition, not yet verified on E9x";
CM_ SG_ 437 HTFL_ST_AIC "BMW name HTFL_ST_AIC (not used at the moment, always 0xFF) - E65 doc (HeinrichG-V12/E65_ReverseEngineering, Bosch MED9.2.1); E65 definition, not yet verified on E9x";
CM_ SG_ 437 TORQ_TAR_ACCM "BMW name TORQ_TAR_ACCM - E65 doc (HeinrichG-V12/E65_ReverseEngineering, Bosch MED9.2.1); E65 definition, not yet verified on E9x";
CM_ SG_ 437 CTR_EFAN_AIC "BMW name CTR_EFAN_AIC (level / fan speed) - E65 doc (HeinrichG-V12/E65_ReverseEngineering, Bosch MED9.2.1); E65 definition, not yet verified on E9x";
CM_ SG_ 437 CTR_AIC_SPFN "BMW name CTR_AIC_SPFN - E65 doc (HeinrichG-V12/E65_ReverseEngineering, Bosch MED9.2.1); E65 definition, not yet verified on E9x";
CM_ SG_ 437 CTR_CLMP "BMW name CTR_CLMP - E65 doc (HeinrichG-V12/E65_ReverseEngineering, Bosch MED9.2.1); E65 definition, not yet verified on E9x";
CM_ SG_ 437 CTR_AIC_RDI "BMW name CTR_AIC_RDI (air condition readyness) - E65 doc (HeinrichG-V12/E65_ReverseEngineering, Bosch MED9.2.1); E65 definition, not yet verified on E9x";
CM_ BO_ 438 "E92 M3 DCT 2011 K-CAN trace (superwofy/E9X-M-CAN-Integration-Module, MIT): 518 frames, DLC {8: 518}, median interval 1000 ms | Also on PT-CAN (JBE gateway); signals copied from BMW_E9x_PT-CAN_full.dbc; PT-CAN DLC 7 | community DBC name: HeatFlowEngine | SPdaten JBBF70.prg: 'Wärmestrom Motor' from DME1/DDE1 | E65 message list: 'WÃ¤rmestrom Motor' from DME1/DDE1";
CM_ SG_ 438 HTFL_RQ_DME "BMW name HTFL_RQ_DME (not used at the moment, always 0xFF) - E65 doc (HeinrichG-V12/E65_ReverseEngineering, Bosch MED9.2.1); E65 definition, not yet verified on E9x";
CM_ SG_ 438 HTFL_ST_DME "BMW name HTFL_ST_DME (not used at the moment, always 0xFF) - E65 doc (HeinrichG-V12/E65_ReverseEngineering, Bosch MED9.2.1); E65 definition, not yet verified on E9x";
CM_ SG_ 438 ACCM_LIM_TORQ "BMW name ACCM_LIM_TORQ (torque limit) - E65 doc (HeinrichG-V12/E65_ReverseEngineering, Bosch MED9.2.1); E65 definition, not yet verified on E9x";
CM_ SG_ 438 ST_CRAW_ENG "BMW name ST_CRAW_ENG (current requirement engine) - E65 doc (HeinrichG-V12/E65_ReverseEngineering, Bosch MED9.2.1); E65 definition, not yet verified on E9x";
CM_ SG_ 438 ST_I_GEN "BMW name ST_I_GEN (generator current) - E65 doc (HeinrichG-V12/E65_ReverseEngineering, Bosch MED9.2.1); E65 definition, not yet verified on E9x";
CM_ SG_ 438 ST_GEN "BMW name ST_GEN (generator status) - E65 doc (HeinrichG-V12/E65_ReverseEngineering, Bosch MED9.2.1); E65 definition, not yet verified on E9x";
CM_ SG_ 438 ST_LDST_GEN "BMW name ST_LDST_GEN (load condition generator electrical/thermal) - E65 doc (HeinrichG-V12/E65_ReverseEngineering, Bosch MED9.2.1); E65 definition, not yet verified on E9x";
CM_ SG_ 438 LDST_GEN "BMW name LDST_GEN (load signal received from the generator) - E65 doc (HeinrichG-V12/E65_ReverseEngineering, Bosch MED9.2.1); E65 definition, not yet verified on E9x";
CM_ BO_ 450 "E92 M3 DCT 2011 K-CAN trace (superwofy/E9X-M-CAN-Integration-Module, MIT): 293 frames, DLC {8: 293}, median interval 450 ms | SPdaten JBBF70.prg: 'Abstandsmeldung PDC' from PDC | E65 message list: 'Abstandsmeldung PDC' from PDC | undefined bits changing in the trace: [0, 1, 2, 3, 4, 5, 7, 8, 9, 10, 11, 12, 13, 14, 16, 17, 18, 19, 20, 21, 22, 24, 25, 26, 27, 28, 29, 30, 32, 33, 34, 35, 36, 37, 38, 39, 40, 41, 42, 43, 44, 45, 46, 47, 48, 49, 50, 51, 52, 53, 54, 56, 57, 58, 59, 60, 61, 62]";
CM_ BO_ 454 "E92 M3 DCT 2011 K-CAN trace (superwofy/E9X-M-CAN-Integration-Module, MIT): 142 frames, DLC {4: 142}, median interval 2048 ms | SPdaten JBBF70.prg: 'Akustikmeldung PDC' from PDC | E65 message list: 'Akustikmeldung PDC' from PDC | undefined bits changing in the trace: [17]";
CM_ BO_ 464 "E92 M3 DCT 2011 K-CAN trace (superwofy/E9X-M-CAN-Integration-Module, MIT): 5185 frames, DLC {8: 5185}, median interval 100 ms | Also on PT-CAN (JBE gateway); signals copied from BMW_E9x_PT-CAN_full.dbc | community DBC name: EngineData | SPdaten JBBF70.prg: 'Motordaten' from DME1/DDE1 | E65 message list: 'Motordaten' from DME1/DDE1";
CM_ SG_ 464 TEMP_ENG "BMW name TEMP_ENG - E65 doc (HeinrichG-V12/E65_ReverseEngineering, Bosch MED9.2.1)";
CM_ SG_ 464 TEMP_EOI "BMW name TEMP_EOI - E65 doc (HeinrichG-V12/E65_ReverseEngineering, Bosch MED9.2.1)";
CM_ SG_ 464 ALIV_COUNT_DME "previous name (community DBC): Counter_464 | BMW name ALIV_COUNT_DME - E65 doc (HeinrichG-V12/E65_ReverseEngineering, Bosch MED9.2.1)";
CM_ SG_ 464 ST_ENG_RUN "E65 name: ST_ENGINE_RUN | BMW name ST_ENGINE_RUN (Status engine run) - E65 doc (HeinrichG-V12/E65_ReverseEngineering, Bosch MED9.2.1)";
CM_ SG_ 464 ST_SW_WAUP "BMW name ST_SW_WAUP (Warm-up status) - E65 doc (HeinrichG-V12/E65_ReverseEngineering, Bosch MED9.2.1)";
CM_ SG_ 464 AIP_ENG "BMW name AIP_ENG - E65 doc (HeinrichG-V12/E65_ReverseEngineering, Bosch MED9.2.1)";
CM_ SG_ 464 IJV_FU "BMW name IJV_FU - E65 doc (HeinrichG-V12/E65_ReverseEngineering, Bosch MED9.2.1)";
CM_ SG_ 464 CTR_SLCK "E65 name: CTL_SLCK | BMW name CTL_SLCK (Shift lock control) - E65 doc (HeinrichG-V12/E65_ReverseEngineering, Bosch MED9.2.1)";
CM_ SG_ 464 RPM_IDLG_TAR "E65 name: RPM_IDLE_TARGET | BMW name RPM_IDLE_TARGET - E65 doc (HeinrichG-V12/E65_ReverseEngineering, Bosch MED9.2.1)";
CM_ BO_ 466 "E92 M3 DCT 2011 K-CAN trace (superwofy/E9X-M-CAN-Integration-Module, MIT): 2634 frames, DLC {6: 2634}, median interval 200 ms | Also on PT-CAN (JBE gateway); signals copied from BMW_E9x_PT-CAN_full.dbc | community DBC name: TransmissionDataDisplay | SPdaten JBBF70.prg: 'Anzeige Getriebedaten' from EGS_EL | superwofy note: '0x1D2 Gear display.txt' | E65 message list: 'Anzeige Getriebedaten' from SMG_M/SMG/EGS_MECH+NAVI/EGS_MECH/DKG | undefined bits changing in the trace: [8, 27, 35]";
CM_ SG_ 466 GearAct "TransmissionDataDisplay";
CM_ SG_ 466 ShiftLeverMode "On the dashboard, there are displayed: D1...D7 in Normal. S1...S6 in Sport. M1..M7 in Manual";
CM_ BO_ 470 "E92 M3 DCT 2011 K-CAN trace (superwofy/E9X-M-CAN-Integration-Module, MIT): 563 frames, DLC {2: 563}, median interval 1000 ms | Also on PT-CAN (JBE gateway); signals copied from BMW_E9x_PT-CAN_full.dbc | community DBC name: SteeringButtons | SPdaten JBBF70.prg: 'Bedienung Taster Audio/Telefon' from SZL_LWS/SZL_LWS | superwofy note: '0x1D6 Steering Wheel MFL buttons.txt' | E65 message list: 'Bedienung Taster Audio/Telefon' from SZL_LWS";
CM_ SG_ 470 TASTER_TELEFON "DSC_87.prg job STATUS_F_CAN_TASTER_AUDIO_TEL result STAT_TASTER_TELEFON (TEL_Status aus F_CAN Telegramm); value table SGBD | replaces community signals Telephone 0|1";
CM_ SG_ 470 TASTER_AUDIO_LAUTSTAERKE "DSC_87.prg job STATUS_F_CAN_TASTER_AUDIO_TEL result STAT_TASTER_AUDIO_LAUTSTAERKE (TEL_Status aus F_CAN Telegramm); value table SGBD | replaces community signals Volume_UP 3|1, Volume_DOWN 2|1";
CM_ SG_ 470 TASTER_AUDIO_SUCHLAUF "DSC_87.prg job STATUS_F_CAN_TASTER_AUDIO_TEL result STAT_TASTER_AUDIO_SUCHLAUF (TEL_Status aus F_CAN Telegramm); value table SGBD | replaces community signals Next_up 5|1, Previous_down 4|1";
CM_ SG_ 470 TASTER_PUSH_TO_TALK "DSC_87.prg job STATUS_F_CAN_TASTER_AUDIO_TEL result STAT_TASTER_PUSH_TO_TALK (TEL_Status aus F_CAN Telegramm); value table SGBD | replaces community signals VoiceControl 8|1";
CM_ SG_ 470 TASTER_SONDERFUNKTION "DSC_87.prg job STATUS_F_CAN_TASTER_AUDIO_TEL result STAT_TASTER_SONDERFUNKTION (TEL_Status aus F_CAN Telegramm); value table SGBD";
CM_ SG_ 470 TASTER_PUSH_TO_HEAR "DSC_87.prg job STATUS_F_CAN_TASTER_AUDIO_TEL result STAT_TASTER_PUSH_TO_HEAR (TEL_Status aus F_CAN Telegramm); value table SGBD";
CM_ BO_ 473 "Not in the E92 M3 trace (CCC iDrive or option not fitted on that car); DLC from the superwofy note | SPdaten JBBF70.prg: 'Bedienung Taster M-Drive' from SZL_LWS/SZL_LWS | superwofy note: '0x1D9 Steering Wheel M button status.txt' | E65 message list: 'Bedienung Taster M-Drive' from SZL_LWS";
CM_ SG_ 473 MDriveButton_inv "superwofy/E9X-M-CAN-Integration-Module notes (MIT) (0x1D9 Steering Wheel M button status.txt): byte 0 = 0xFF released, 0xBF pressed";
CM_ SG_ 473 MDriveButton "superwofy/E9X-M-CAN-Integration-Module notes (MIT) (0x1D9 Steering Wheel M button status.txt): byte 1 = 0x3F released, 0x7F pressed";
CM_ SG_ 473 Counter_1D9 "superwofy/E9X-M-CAN-Integration-Module notes (MIT) (0x1D9 Steering Wheel M button status.txt): low nibble of byte 2 counts 0..15; sent every 1 s, every 100 ms while the button is pressed";
CM_ BO_ 481 "E92 M3 DCT 2011 K-CAN trace (superwofy/E9X-M-CAN-Integration-Module, MIT): 2600 frames, DLC {6: 2600}, median interval 200 ms | Also on PT-CAN (JBE gateway); signals copied from BMW_E9x_PT-CAN_full.dbc | undefined bits changing in the trace: [0, 1, 2, 3, 4, 5, 8, 9, 10, 11, 16]";
CM_ BO_ 483 "E92 M3 DCT 2011 K-CAN trace (superwofy/E9X-M-CAN-Integration-Module, MIT): 4 frames, DLC {2: 4} | SPdaten JBBF70.prg: 'Bedienung Taster Innenbeleuchtung' from FZD | undefined bits changing in the trace: [0]";
CM_ BO_ 487 "E92 M3 DCT 2011 K-CAN trace (superwofy/E9X-M-CAN-Integration-Module, MIT): 15 frames, DLC {2: 15}, median interval 97 ms | SPdaten JBBF70.prg: 'Bedienung Sitzheizung/Sitzklima FA' from IHKA | superwofy note: '0x1E7 Seat heating button driver.txt' | E65 message list: 'Bedienung Sitzheizung/Sitzklima FA' from SZM_MIT_KBUS/SZM";
CM_ SG_ 487 SeatHeatingButton_FA "superwofy/E9X-M-CAN-Integration-Module notes (MIT) (0x1E7 Seat heating button driver.txt): driver seat heating button: byte 0 = 0xFC released, 0xFD pressed";
CM_ BO_ 488 "E92 M3 DCT 2011 K-CAN trace (superwofy/E9X-M-CAN-Integration-Module, MIT): 13 frames, DLC {2: 13}, median interval 93 ms | SPdaten JBBF70.prg: 'Bedienung Sitzheizung/Sitzklima BF' from IHKA | E65 message list: 'Bedienung Sitzheizung/Sitzklima BF' from SZM_MIT_KBUS/SZM";
CM_ SG_ 488 SeatHeatingButton_BF "superwofy/E9X-M-CAN-Integration-Module notes (MIT) (by analogy with 0x1E7 (passenger side); the M3 trace shows the same FC/FD values): passenger seat heating button (by analogy with 0x1E7)";
CM_ BO_ 494 "E92 M3 DCT 2011 K-CAN trace (superwofy/E9X-M-CAN-Integration-Module, MIT): 520 frames, DLC {2: 520}, median interval 1000 ms | SPdaten JBBF70.prg: 'Bedienung Lenkstockstaster' from FRMFA | E65 message list: 'Bedienung Lenkstockstaster' from SZL_LWS";
CM_ BO_ 512 "E92 M3 DCT 2011 K-CAN trace (superwofy/E9X-M-CAN-Integration-Module, MIT): 2009 frames, DLC {8: 2009}, median interval 200 ms | Also on PT-CAN (JBE gateway); signals copied from BMW_E9x_PT-CAN_full.dbc | community DBC name: CruiseControlStatus | SPdaten JBBF70.prg: 'Regelgeschwindigkeit Stufentempomat' from DME1/DDE1 | E65 message list: 'Regelgeschwindigkeit Stufentempomat' from DME1/DDE1 | undefined bits changing in the trace: [18, 20]";
CM_ SG_ 512 V_CLCTR_CCTR "BMW name V_CLCTR_CCTR - E65 doc (HeinrichG-V12/E65_ReverseEngineering, Bosch MED9.2.1); replaces CruiseControlSetpointSpeed 7|8 (community CruiseControlSetpointSpeed used only the low byte)";
CM_ SG_ 512 ST_V_CLCTR_CCTR "BMW name ST_V_CLCTR_CCTR - E65 doc (HeinrichG-V12/E65_ReverseEngineering, Bosch MED9.2.1); replaces CruiseCoontrolActiveFlag 13|1, CruiseControlInactiveFlag 12|1 (enum 1 = inactive / 2 = active matches the community DBC flags at bits 12/13)";
CM_ SG_ 512 CTR_DISP_CCTR "BMW name CTR_DISP_CCTR - E65 doc (HeinrichG-V12/E65_ReverseEngineering, Bosch MED9.2.1); E65 definition, not yet verified on E9x";
CM_ SG_ 512 IDX_NO "BMW name IDX_NO - E65 doc (HeinrichG-V12/E65_ReverseEngineering, Bosch MED9.2.1); E65 definition, not yet verified on E9x";
CM_ SG_ 512 V_CCTR_IDX_NO_1 "BMW name V_CCTR_IDX_NO_1 - E65 doc (HeinrichG-V12/E65_ReverseEngineering, Bosch MED9.2.1); E65 definition, not yet verified on E9x";
CM_ SG_ 512 V_CCTR_IDX_NO_2 "BMW name V_CCTR_IDX_NO_2 - E65 doc (HeinrichG-V12/E65_ReverseEngineering, Bosch MED9.2.1); E65 definition, not yet verified on E9x";
CM_ SG_ 512 V_CCTR_IDX_NO_3 "BMW name V_CCTR_IDX_NO_3 - E65 doc (HeinrichG-V12/E65_ReverseEngineering, Bosch MED9.2.1); E65 definition, not yet verified on E9x";
CM_ BO_ 514 "E92 M3 DCT 2011 K-CAN trace (superwofy/E9X-M-CAN-Integration-Module, MIT): 106 frames, DLC {2: 106}, median interval 5000 ms | Also on PT-CAN (JBE gateway); signals copied from BMW_E9x_PT-CAN_full.dbc | community DBC name: Dimming | SPdaten JBBF70.prg: 'Dimmung' from FRMFA | SPdaten JBBF70.prg: 'Dimmung' from Kombi | superwofy note: '0x202 Dimming.txt' | E65 message list: 'Dimmung' from LM";
CM_ SG_ 514 DimmerPosition "superwofy/E9X-M-CAN-Integration-Module notes (MIT) (0x202 Dimming.txt): instrument lighting dimmer, sent by KOMBI; intermediate values occur (0x7E in the M3 trace) | superwofy/E9X-M-CAN-Integration-Module notes (MIT) (0x202 Dimming.txt): instrument lighting dimmer, sent by KOMBI; intermediate values occur (0x7E in the M3 trace)";
CM_ BO_ 517 "E92 M3 DCT 2011 K-CAN trace (superwofy/E9X-M-CAN-Integration-Module, MIT): 6 frames, DLC {2: 6}, median interval 56 ms | SPdaten JBBF70.prg: 'Akustikanforderung Kombi' from Kombi | superwofy note: '0x205 Kombi CC gong.txt' | E65 message list: 'Akustikanforderung Kombi' from Kombi";
CM_ SG_ 517 GongRequest "superwofy/E9X-M-CAN-Integration-Module notes (MIT) (0x205 Kombi CC gong.txt): acoustic request to KOMBI";
CM_ BO_ 518 "Not in the E92 M3 trace (CCC iDrive or option not fitted on that car); DLC from the superwofy note | SPdaten JBBF70.prg: 'Steuerung Anzeige Shiftlights' from DME1 | superwofy note: '0x206 M3 DCT shiftlights.txt' | E65 message list: 'Steuerung Anzeige Shiftlights' from DME1";
CM_ SG_ 518 ShiftlightMode "superwofy/E9X-M-CAN-Integration-Module notes (MIT) (0x206 M3 DCT shiftlights.txt): M3 DCT shift lights (DME to KOMBI)";
CM_ SG_ 518 ShiftlightParameter "superwofy/E9X-M-CAN-Integration-Module notes (MIT) (0x206 M3 DCT shiftlights.txt): 0x3E with mode 0x86, 0x00 otherwise; meaning unknown";
CM_ BO_ 538 "E92 M3 DCT 2011 K-CAN trace (superwofy/E9X-M-CAN-Integration-Module, MIT): 224 frames, DLC {3: 224}, median interval 300 ms | Also on PT-CAN (JBE gateway); signals copied from BMW_E9x_PT-CAN_full.dbc | community DBC name: LampStatus | SPdaten JBBF70.prg: 'Lampenzustand' from FRMFA | E65 message list: 'Lampenzustand' from LM | undefined bits changing in the trace: [0, 2, 6, 7, 8, 9, 12, 13]";
CM_ BO_ 550 "E92 M3 DCT 2011 K-CAN trace (superwofy/E9X-M-CAN-Integration-Module, MIT): 53 frames, DLC {5: 53}, median interval 8192 ms | Also on PT-CAN (JBE gateway); signals copied from BMW_E9x_PT-CAN_full.dbc | community DBC name: RainSensorWiperSpeed | SPdaten JBBF70.prg: 'Regensensor-Wischergeschwindigkeit' from FZD | E65 message list: 'Regensensor-Wischergeschwindigkeit' from RLS | E65 message list: 'Regensensor-Wischergeschwindigkeit' from LM | undefined bits changing in the trace: [30]";
CM_ SG_ 550 S226_b0 "MK60E5 FW 7846816A (M3) signal (internal var 0x87), meaning unknown";
CM_ SG_ 550 S226_b8 "MK60E5 FW 7846816A (M3) signal (internal var 0xC1), meaning unknown";
CM_ SG_ 550 S226_b24 "MK60E5 FW 7846816A (M3) signal (internal var 0x06), meaning unknown";
CM_ BO_ 552 "E92 M3 DCT 2011 K-CAN trace (superwofy/E9X-M-CAN-Integration-Module, MIT): 1 frames, DLC {2: 1} | SPdaten JBBF70.prg: 'Bedienung Sonderfunktion' from CHAMP_M_ASK2/CCC_GW | SPdaten JBBF70.prg: 'Bedienung Sonderfunktion' from RAD1 | E65 message list: 'Bedienung Sonderfunktion' from M_ASK/CCC_GW | E65 message list: 'Bedienung Sonderfunktion' from CCC_MM";
CM_ BO_ 554 "E92 M3 DCT 2011 K-CAN trace (superwofy/E9X-M-CAN-Integration-Module, MIT): 54 frames, DLC {3: 54}, median interval 10001 ms | SPdaten JBBF70.prg: 'Status BFS' from SM_BF | SPdaten JBBF70.prg: 'Status BFS' from JBBF | E65 message list: 'Status BFS' from SM_BF | undefined bits changing in the trace: [4, 5]";
CM_ BO_ 556 "E92 M3 DCT 2011 K-CAN trace (superwofy/E9X-M-CAN-Integration-Module, MIT): 13 frames, DLC {2: 13}, median interval 150 ms | SPdaten JBBF70.prg: 'Bedienung Taster NSL' from FRMFA | undefined bits changing in the trace: [0, 1]";
CM_ BO_ 562 "E92 M3 DCT 2011 K-CAN trace (superwofy/E9X-M-CAN-Integration-Module, MIT): 54 frames, DLC {3: 54}, median interval 10003 ms | SPdaten JBBF70.prg: 'Status FAS' from SM_FA | SPdaten JBBF70.prg: 'Status FAS' from JBBF | E65 message list: 'Status FAS' from SM_FA | undefined bits changing in the trace: [4, 5]";
CM_ BO_ 570 "E92 M3 DCT 2011 K-CAN trace (superwofy/E9X-M-CAN-Integration-Module, MIT): 26 frames, DLC {4: 26}, median interval 100 ms | SPdaten JBBF70.prg: 'Status Funkschlüssel' from CAS | superwofy note: '0x23A Lock unlock.txt' | E65 message list: 'Status FunkschlÃ¼ssel' from CAS";
CM_ SG_ 570 S23A_b8 "superwofy/E9X-M-CAN-Integration-Module notes (MIT) (0x23A Lock unlock.txt): 0x30 normally, 0x33 after a lock command";
CM_ SG_ 570 KeyFobButton "superwofy/E9X-M-CAN-Integration-Module notes (MIT) (0x23A Lock unlock.txt): radio key button (CAS)";
CM_ BO_ 578 "E92 M3 DCT 2011 K-CAN trace (superwofy/E9X-M-CAN-Integration-Module, MIT): 65 frames, DLC {5: 65}, median interval 9997 ms | Also on PT-CAN (JBE gateway); signals copied from BMW_E9x_PT-CAN_full.dbc | community DBC name: ClimateFrontStatus | SPdaten JBBF70.prg: 'Status Klima Front' from IHKA | E65 message list: 'Status Klima Front' from IHKA | undefined bits changing in the trace: [4, 5, 8]";
CM_ BO_ 582 "E92 M3 DCT 2011 K-CAN trace (superwofy/E9X-M-CAN-Integration-Module, MIT): 500 frames, DLC {5: 500}, median interval 998 ms | SPdaten JBBF70.prg: 'Status Klima Front Bedienteil' from IHKA | undefined bits changing in the trace: [10, 11, 16, 17, 18, 19, 20, 21, 22]";
CM_ BO_ 586 "E92 M3 DCT 2011 K-CAN trace (superwofy/E9X-M-CAN-Integration-Module, MIT): 201 frames, DLC {2: 201}, median interval 2048 ms | SPdaten JBBF70.prg: 'Status PDC' from PDC | superwofy note: '0x24A PDC status.txt' | E65 message list: 'Status PDC' from PDC";
CM_ SG_ 586 PDC_Status "superwofy/E9X-M-CAN-Integration-Module notes (MIT) (0x24A PDC status.txt)";
CM_ BO_ 587 "E92 M3 DCT 2011 K-CAN trace (superwofy/E9X-M-CAN-Integration-Module, MIT): 73 frames, DLC {2: 73}, median interval 9999 ms | SPdaten JBBF70.prg: 'Status Türsensoren' from FRMFA | undefined bits changing in the trace: [0]";
CM_ BO_ 594 "E92 M3 DCT 2011 K-CAN trace (superwofy/E9X-M-CAN-Integration-Module, MIT): 23 frames, DLC {2: 23}, median interval 50 ms | SPdaten JBBF70.prg: 'Wischerstatus' from JBBF | superwofy note: '0x252 Wiper status.txt' | E65 message list: 'Wischerstatus' from KBM";
CM_ SG_ 594 WiperState "superwofy/E9X-M-CAN-Integration-Module notes (MIT) (0x252 Wiper status.txt): sent twice per event";
CM_ BO_ 612 "E92 M3 DCT 2011 K-CAN trace (superwofy/E9X-M-CAN-Integration-Module, MIT): 105 frames, DLC {6: 105}, median interval 91 ms | undefined bits changing in the trace: [32, 33, 34, 35, 36, 37, 38, 39]";
CM_ SG_ 612 Counter_264 "superwofy/E9X-M-CAN-Integration-Module notes (MIT) (0x1B8 CCC ZBE.txt (CIC rotation)): increments with every message";
CM_ SG_ 612 ControllerRotation "superwofy/E9X-M-CAN-Integration-Module notes (MIT) (0x1B8 CCC ZBE.txt (CIC rotation)): iDrive controller (CIC): +1 per detent clockwise, -1 anti-clockwise; wraps below 0 (0xFB..0xFE in the M3 trace)";
CM_ BO_ 615 "E92 M3 DCT 2011 K-CAN trace (superwofy/E9X-M-CAN-Integration-Module, MIT): 164 frames, DLC {6: 164}, median interval 155 ms";
CM_ SG_ 615 Counter_267 "superwofy/E9X-M-CAN-Integration-Module notes (MIT) (0x1B8 CCC ZBE.txt (CIC buttons)): increments with every change";
CM_ SG_ 615 ControllerButtonPressed "superwofy/E9X-M-CAN-Integration-Module notes (MIT) (0x1B8 CCC ZBE.txt (CIC buttons))";
CM_ SG_ 615 ControllerDirection "superwofy/E9X-M-CAN-Integration-Module notes (MIT) (0x1B8 CCC ZBE.txt (CIC buttons)): only north documented";
CM_ SG_ 615 ControllerButton "superwofy/E9X-M-CAN-Integration-Module notes (MIT) (0x1B8 CCC ZBE.txt (CIC buttons)): iDrive controller (CIC) button; only these codes documented";
CM_ BO_ 621 "E92 M3 DCT 2011 K-CAN trace (superwofy/E9X-M-CAN-Integration-Module, MIT): 6 frames, DLC {3: 6}, median interval 101 ms | SPdaten JBBF70.prg: 'Bedienung Rollos MK' from IHR/IHKR/IHKA | E65 message list: 'Bedienung Rollos MK' from unbekannt | undefined bits changing in the trace: [0]";
CM_ BO_ 622 "E92 M3 DCT 2011 K-CAN trace (superwofy/E9X-M-CAN-Integration-Module, MIT): 267 frames, DLC {8: 267}, median interval 2000 ms | SPdaten JBBF70.prg: 'Steuerung FH/SHD Zentrale (Komfort)' from CAS | E65 message list: 'Steuerung FH/SHD Zentrale (Komfort)' from CAS | undefined bits changing in the trace: [6, 14, 22]";
CM_ BO_ 627 "E92 M3 DCT 2011 K-CAN trace (superwofy/E9X-M-CAN-Integration-Module, MIT): 10 frames, DLC {8: 10}, median interval 16741 ms | superwofy note: '0x273 0x277 E zbe cic status response.txt' | superwofy note: '0x273 CIC status.txt'";
CM_ SG_ 627 Counter_273 "superwofy/E9X-M-CAN-Integration-Module notes (MIT) (0x273 CIC status.txt): CIC status counter: +1 every 2 s, restarts at 1 after a CIC reboot";
CM_ BO_ 631 "E92 M3 DCT 2011 K-CAN trace (superwofy/E9X-M-CAN-Integration-Module, MIT): 25 frames, DLC {4: 25}, median interval 161 ms | superwofy note: '0x273 0x277 E zbe cic status response.txt'";
CM_ SG_ 631 EchoCounter_273 "superwofy/E9X-M-CAN-Integration-Module notes (MIT) (0x273 0x277 E zbe cic status response.txt): iDrive controller response: echoes byte 7 of 0x273";
CM_ BO_ 632 "E92 M3 DCT 2011 K-CAN trace (superwofy/E9X-M-CAN-Integration-Module, MIT): 117 frames, DLC {8: 117}, median interval 155 ms | SPdaten ACC2.prg: 'Navigationsgraph' from CCC | E65 message list: 'Navigationsgraph' from CCC_GW | undefined bits changing in the trace: [0, 1, 2, 3, 4, 5, 6, 8, 9, 10, 11, 12, 13, 14, 16, 17, 28, 29, 30, 31, 32, 33, 34, 35, 36, 37, 38, 39, 40, 41, 42, 43, 44, 45, 46, 47, 48, 49, 50, 51, 52, 53, 58, 59, 60, 61, 62, 63]";
CM_ BO_ 634 "E92 M3 DCT 2011 K-CAN trace (superwofy/E9X-M-CAN-Integration-Module, MIT): 38 frames, DLC {8: 38}, median interval 680 ms | SPdaten ACC2.prg: 'Synchronisation_Navigationsgraph' from CCC | E65 message list: 'Synchronisation Navigationsgraph' from CCC_GW | undefined bits changing in the trace: [0, 1, 2, 8, 9, 10, 11, 12, 13, 16, 17, 18, 19, 20, 21, 22, 23, 24, 25, 26, 27, 28, 29, 30, 31, 50, 57, 59, 62]";
CM_ BO_ 646 "E92 M3 DCT 2011 K-CAN trace (superwofy/E9X-M-CAN-Integration-Module, MIT): 787 frames, DLC {2: 787}, median interval 512 ms | SPdaten JBBF70.prg: 'Steuerung Elektrochrom Abblenden' from FZD | undefined bits changing in the trace: [0]";
CM_ BO_ 658 "E92 M3 DCT 2011 K-CAN trace (superwofy/E9X-M-CAN-Integration-Module, MIT): 104 frames, DLC {2: 104}, median interval 3995 ms | SPdaten JBBF70.prg: 'Steuerung Fernlicht-Assistent' from FLA | E65 message list: 'Steuerung Fernlicht-Assistent' from FLA | undefined bits changing in the trace: [10, 11, 12]";
CM_ BO_ 672 "E92 M3 DCT 2011 K-CAN trace (superwofy/E9X-M-CAN-Integration-Module, MIT): 118 frames, DLC {8: 118}, median interval 5000 ms | SPdaten JBBF70.prg: 'Steuerung Zentralverriegelung' from CAS | E65 message list: 'Steuerung Zentralverriegelung' from CAS | undefined bits changing in the trace: [0, 1, 3, 4, 5, 7, 8, 9, 11, 12, 13, 15, 20, 21, 23, 24, 33, 34, 35, 36, 42, 48, 49, 54, 58]";
CM_ BO_ 678 "E92 M3 DCT 2011 K-CAN trace (superwofy/E9X-M-CAN-Integration-Module, MIT): 524 frames, DLC {2: 524}, median interval 1000 ms | Also on PT-CAN (JBE gateway); signals copied from BMW_E9x_PT-CAN_full.dbc | community DBC name: WiperSwitch | SPdaten JBBF70.prg: 'Bedienung Wischertaster' from SZL_LWS/SZL_LWS | E65 message list: 'Bedienung Wischertaster' from SZL_LWS";
CM_ SG_ 678 WISCHERTASTER "MK60E5 FW 7846816A (M3) signal (internal var 0x88), meaning unknown | community DBC flags here: bit 0 = AutoWipersOn | previous name (firmware field): S2A6_b0 | DSC_87.prg job STATUS_F_CAN_WISCHERTASTER result STAT_WISCHERTASTER (Status_Bit aus SG Antwort); value table SGBD";
CM_ SG_ 678 WISCHERPOTI "MK60E5 FW 7846816A (M3) signal (internal var 0x8E), meaning unknown | previous name (firmware field): S2A6_b8 | DSC_87.prg job STATUS_F_CAN_WISCHERTASTER result STAT_WISCHERPOTI (Status_Bit aus SG Antwort); value table SGBD";
CM_ BO_ 690 "E92 M3 DCT 2011 K-CAN trace (superwofy/E9X-M-CAN-Integration-Module, MIT): 7430 frames, DLC {8: 7430}, median interval 76 ms | Also on PT-CAN (JBE gateway); signals copied from BMW_E9x_PT-CAN_full.dbc | community DBC name: WheelPressure_KCAN | SPdaten JBBF70.prg: 'Raddrücke K-CAN' from EHB3 | E65 message list: 'RaddrÃ¼cke K-CAN' from DXC_RB/DSC_RB/DSC_CT";
CM_ SG_ 690 S2B2_b0 "MK60E5 FW 7846816A (M3) signal (internal var 0x26), meaning unknown";
CM_ SG_ 690 S2B2_b8 "MK60E5 FW 7846816A (M3) signal (internal var 0x1B), meaning unknown";
CM_ SG_ 690 S2B2_b16 "MK60E5 FW 7846816A (M3) signal (internal var 0x1C), meaning unknown";
CM_ SG_ 690 S2B2_b24 "MK60E5 FW 7846816A (M3) signal (internal var 0x1D), meaning unknown";
CM_ SG_ 690 S2B2_b32 "MK60E5 FW 7846816A (M3) signal (internal var 0x1E), meaning unknown";
CM_ SG_ 690 S2B2_b34 "MK60E5 FW 7846816A (M3) signal (internal var 0x56), meaning unknown";
CM_ SG_ 690 S2B2_b36 "MK60E5 FW 7846816A (M3) signal (internal var 0x55), meaning unknown";
CM_ SG_ 690 S2B2_b48 "MK60E5 FW 7846816A (M3) signal (internal var 0x18), meaning unknown";
CM_ SG_ 690 S2B2_b50 "MK60E5 FW 7846816A (M3) signal (internal var 0x4A), meaning unknown";
CM_ SG_ 690 S2B2_b53 "MK60E5 FW 7846816A (M3) signal (internal var 0x4B), meaning unknown";
CM_ SG_ 690 S2B2_b56 "MK60E5 FW 7846816A (M3) signal (internal var 0x35), meaning unknown";
CM_ SG_ 690 S2B2_b59 "MK60E5 FW 7846816A (M3) signal (internal var 0x48), meaning unknown";
CM_ SG_ 690 S2B2_b61 "MK60E5 FW 7846816A (M3) signal (internal var 0x3D), meaning unknown";
CM_ BO_ 692 "E92 M3 DCT 2011 K-CAN trace (superwofy/E9X-M-CAN-Integration-Module, MIT): 6 frames, DLC {2: 6}, median interval 200 ms | SPdaten JBBF70.prg: 'DWA-Alarm' from FZD | SPdaten JBBF70.prg: 'DWA-Alarm' from DWA | superwofy note: '0x2B4 Alarm lights control.txt' | E65 message list: 'DWA-Alarm' from DWA";
CM_ SG_ 692 AlarmFlashHazards "superwofy/E9X-M-CAN-Integration-Module notes (MIT) (0x2B4 Alarm lights control.txt): continuous flashing of the hazard lights (bit 3 has no effect)";
CM_ SG_ 692 AlarmFlashXenon "superwofy/E9X-M-CAN-Integration-Module notes (MIT) (0x2B4 Alarm lights control.txt): continuous headlight flashing";
CM_ SG_ 692 AlarmFlashAngelEyes "superwofy/E9X-M-CAN-Integration-Module notes (MIT) (0x2B4 Alarm lights control.txt): continuous angel-eye flashing";
CM_ SG_ 692 ConfirmationFlash "superwofy/E9X-M-CAN-Integration-Module notes (MIT) (0x2B4 Alarm lights control.txt): DWA lock/unlock confirmation";
CM_ BO_ 696 "Not in the E92 M3 trace (CCC iDrive or option not fitted on that car); DLC from the superwofy note | SPdaten JBBF70.prg: 'Bedienung Bordcomputer' from CHAMP_M_ASK2/CCC_GW | superwofy note: '0x2B8 Operation on-board computer and speed warning setting.txt' | E65 message list: 'Bedienung Bordcomputer' from M_ASK/CCC_GW";
CM_ SG_ 696 SpeedWarningOn "superwofy/E9X-M-CAN-Integration-Module notes (MIT) (0x2B8 Operation on-board computer and speed warning setting.txt): byte 0 = 0x7E on, 0x3E off (CIC to KOMBI)";
CM_ SG_ 696 SpeedWarningLimit "superwofy/E9X-M-CAN-Integration-Module notes (MIT) (0x2B8 Operation on-board computer and speed warning setting.txt): speed limit; 6..330 km/h observed";
CM_ BO_ 698 "E92 M3 DCT 2011 K-CAN trace (superwofy/E9X-M-CAN-Integration-Module, MIT): 84 frames, DLC {5: 84}, median interval 5000 ms | SPdaten JBBF70.prg: 'Stoppuhr' from Kombi | E65 message list: 'Stoppuhr' from Kombi | undefined bits changing in the trace: [36, 37]";
CM_ BO_ 704 "E92 M3 DCT 2011 K-CAN trace (superwofy/E9X-M-CAN-Integration-Module, MIT): 55 frames, DLC {3: 55}, median interval 10000 ms | Also on PT-CAN (JBE gateway); signals copied from BMW_E9x_PT-CAN_full.dbc | community DBC name: LCD_lighting | SPdaten JBBF70.prg: 'LCD-Leuchtdichte' from Kombi | superwofy note: '0x2C0 Kombi LCD brightness.txt' | E65 message list: 'LCD-Leuchtdichte' from Kombi";
CM_ SG_ 704 LCD_Brightness "superwofy/E9X-M-CAN-Integration-Module notes (MIT) (0x2C0 Kombi LCD brightness.txt): KOMBI LCD brightness: 0x3F in darkness, up to 0xF4 in bright light | superwofy/E9X-M-CAN-Integration-Module notes (MIT) (0x2C0 Kombi LCD brightness.txt): KOMBI LCD brightness: 0x3F in darkness, up to 0xF4 in bright light";
CM_ SG_ 704 S2C0_b8 "superwofy/E9X-M-CAN-Integration-Module notes (MIT) (0x2C0 Kombi LCD brightness.txt): 0x00/0x7F/0x81/0xE0 observed; meaning unknown | superwofy/E9X-M-CAN-Integration-Module notes (MIT) (0x2C0 Kombi LCD brightness.txt): 0x00/0x7F/0x81/0xE0 observed; meaning unknown";
CM_ SG_ 704 CID_Brightness "superwofy/E9X-M-CAN-Integration-Module notes (MIT) (0x2C0 Kombi LCD brightness.txt): central display (CID) follows this byte, 0..0xFE | superwofy/E9X-M-CAN-Integration-Module notes (MIT) (0x2C0 Kombi LCD brightness.txt): central display (CID) follows this byte, 0..0xFE";
CM_ BO_ 707 "E92 M3 DCT 2011 K-CAN trace (superwofy/E9X-M-CAN-Integration-Module, MIT): 86 frames, DLC {5: 86}, median interval 4999 ms | undefined bits changing in the trace: [0, 1, 2, 3, 10, 12]";
CM_ BO_ 714 "E92 M3 DCT 2011 K-CAN trace (superwofy/E9X-M-CAN-Integration-Module, MIT): 532 frames, DLC {2: 532}, median interval 1000 ms | SPdaten JBBF70.prg: 'Außentemperatur' from Kombi | E65 message list: 'AuÃŸentemperatur' from Kombi";
CM_ BO_ 718 "E92 M3 DCT 2011 K-CAN trace (superwofy/E9X-M-CAN-Integration-Module, MIT): 43 frames, DLC {3: 43}, median interval 10001 ms | SPdaten JBBF70.prg: 'Steuerung Monitor' from CHAMP_M_ASK2/CCC_GW | E65 message list: 'Steuerung Monitor' from M_ASK/CCC_GW | undefined bits changing in the trace: [16]";
CM_ BO_ 719 "E92 M3 DCT 2011 K-CAN trace (superwofy/E9X-M-CAN-Integration-Module, MIT): 33 frames, DLC {2: 33}, median interval 20006 ms | Also on PT-CAN (JBE gateway); signals copied from BMW_E9x_PT-CAN_full.dbc | community DBC name: Status_of_auxiliary_water_pump | SPdaten JBBF70.prg: 'Status Zusatzwasserpumpe' from JBBF | undefined bits changing in the trace: [0, 1]";
CM_ BO_ 720 "E92 M3 DCT 2011 K-CAN trace (superwofy/E9X-M-CAN-Integration-Module, MIT): 22 frames, DLC {2: 22}, median interval 20007 ms | SPdaten JBBF70.prg: 'Status Sensor AUC' from JBBF";
CM_ BO_ 721 "E92 M3 DCT 2011 K-CAN trace (superwofy/E9X-M-CAN-Integration-Module, MIT): 20 frames, DLC {2: 20}, median interval 20481 ms | SPdaten JBBF70.prg: 'Status Beschlag Scheibe V' from FZD";
CM_ BO_ 722 "E92 M3 DCT 2011 K-CAN trace (superwofy/E9X-M-CAN-Integration-Module, MIT): 67 frames, DLC {3: 67}, median interval 4244 ms | SPdaten JBBF70.prg: 'Status Druck Kältekreislauf' from JBBF | undefined bits changing in the trace: [0, 1, 2, 3, 4]";
CM_ BO_ 723 "E92 M3 DCT 2011 K-CAN trace (superwofy/E9X-M-CAN-Integration-Module, MIT): 23 frames, DLC {4: 23}, median interval 20007 ms | SPdaten JBBF70.prg: 'Status Schichtung Fond' from JBBF | undefined bits changing in the trace: [0, 1, 2, 3, 4, 5, 6, 7]";
CM_ BO_ 725 "E92 M3 DCT 2011 K-CAN trace (superwofy/E9X-M-CAN-Integration-Module, MIT): 136 frames, DLC {2: 136}, median interval 3001 ms | SPdaten JBBF70.prg: 'Status Heizung Heckscheibe' from JBBF | E65 message list: 'Status Heizung Heckscheibe' from IHKA";
CM_ BO_ 726 "E92 M3 DCT 2011 K-CAN trace (superwofy/E9X-M-CAN-Integration-Module, MIT): 21 frames, DLC {3: 21}, median interval 20007 ms | SPdaten JBBF70.prg: 'Status Ventil Klimakompressor' from JBBF";
CM_ BO_ 742 "E92 M3 DCT 2011 K-CAN trace (superwofy/E9X-M-CAN-Integration-Module, MIT): 150 frames, DLC {8: 150}, median interval 160 ms | SPdaten JBBF70.prg: 'Status Klima Luftverteilung FA' from IHKA | superwofy note: '0x2E6 0x3DF auto climate status.txt' | E65 message list: 'Status Klima Luftverteilung FA' from IHKA | undefined bits changing in the trace: [0, 1, 2, 3, 5, 6, 8, 9, 10, 11, 13, 16, 17, 18, 19, 20, 21, 22, 40, 41, 42]";
CM_ SG_ 742 AutoAirDistribution "superwofy/E9X-M-CAN-Integration-Module notes (MIT) (0x2E6 0x3DF auto climate status.txt): byte 4 = 0x20 when on";
CM_ SG_ 742 AutoFan "superwofy/E9X-M-CAN-Integration-Module notes (MIT) (0x2E6 0x3DF auto climate status.txt): byte 6 = 0x7F auto, 0x3F manual";
CM_ BO_ 746 "E92 M3 DCT 2011 K-CAN trace (superwofy/E9X-M-CAN-Integration-Module, MIT): 45 frames, DLC {8: 45}, median interval 9998 ms | SPdaten JBBF70.prg: 'Status Klima Luftverteilung BF' from IHKA | E65 message list: 'Status Klima Luftverteilung BF' from IHKA";
CM_ BO_ 750 "E92 M3 DCT 2011 K-CAN trace (superwofy/E9X-M-CAN-Integration-Module, MIT): 6 frames, DLC {2: 6}, median interval 159 ms | SPdaten JBBF70.prg: 'Status Klima Zusatzprogramme' from IHKA | E65 message list: 'Status Klima Zusatzprogramme' from IHKA";
CM_ BO_ 752 "E92 M3 DCT 2011 K-CAN trace (superwofy/E9X-M-CAN-Integration-Module, MIT): 208 frames, DLC {2: 208}, median interval 2000 ms | SPdaten JBBF70.prg: 'Status Klima Standfunktionen' from IHKA | E65 message list: 'Status Klima Standfunktionen' from IHKA";
CM_ BO_ 753 "E92 M3 DCT 2011 K-CAN trace (superwofy/E9X-M-CAN-Integration-Module, MIT): 415 frames, DLC {3: 415}, median interval 1000 ms | Also on PT-CAN (JBE gateway); signals copied from BMW_E9x_PT-CAN_full.dbc | community DBC name: Status_driver_detection | SPdaten JBBF70.prg: 'Status Fahrererkennung' from MRSZ/ACSM | undefined bits changing in the trace: [0, 1, 2, 3, 4, 8, 9, 10, 11, 16, 17]";
CM_ BO_ 756 "E92 M3 DCT 2011 K-CAN trace (superwofy/E9X-M-CAN-Integration-Module, MIT): 89 frames, DLC {4: 89}, median interval 4998 ms | SPdaten JBBF70.prg: 'Steuerung Klima SH/ZH Zusatzwasserpumpe' from IHR/IHKR/IHKA | E65 message list: 'Steuerung Klima SH/ZH Zusatzwasserpumpe' from IHKA";
CM_ BO_ 758 "E92 M3 DCT 2011 K-CAN trace (superwofy/E9X-M-CAN-Integration-Module, MIT): 129 frames, DLC {2: 129}, median interval 5010 ms | Also on PT-CAN (JBE gateway); signals copied from BMW_E9x_PT-CAN_full.dbc | community DBC name: LightControl | SPdaten JBBF70.prg: 'Steuerung Licht' from FRMFA | E65 message list: 'Steuerung Licht' from KBM | undefined bits changing in the trace: [0, 2, 4, 6, 8, 10]";
CM_ BO_ 759 "E92 M3 DCT 2011 K-CAN trace (superwofy/E9X-M-CAN-Integration-Module, MIT): 6 frames, DLC {4: 6}, median interval 175 ms | SPdaten JBBF70.prg: 'Einheiten' from Kombi | superwofy note: '0x2F7 Kombi Units.txt' | E65 message list: 'Einheiten' from M_ASK/CCC_GW | E65 message list: 'Einheiten' from CCC_MM";
CM_ SG_ 759 DistanceUnit "superwofy/E9X-M-CAN-Integration-Module notes (MIT) (0x2F7 Kombi Units.txt): byte 2 = 0x79 km, 0xB9 miles; sent 3 times at terminal R";
CM_ BO_ 760 "E92 M3 DCT 2011 K-CAN trace (superwofy/E9X-M-CAN-Integration-Module, MIT): 47 frames, DLC {8: 47}, median interval 14997 ms | Also on PT-CAN (JBE gateway); signals copied from BMW_E9x_PT-CAN_full.dbc | community DBC name: Time_Date | SPdaten JBBF70.prg: 'Uhrzeit/Datum' from Kombi | E65 message list: 'Uhrzeit/Datum' from Kombi";
CM_ SG_ 760 DISP_HR "BMW name DISP_HR (Anzeige Stunde [-]) - MEVD17.2 function description 15.3.3.1-DSPLECU_CO.md; range/values: 0 - 254; raw value (no conversion given)";
CM_ SG_ 760 DISP_MN "BMW name DISP_MN (Anzeige Minute [-]) - MEVD17.2 function description 15.3.3.1-DSPLECU_CO.md; range/values: 0 - 254; raw value (no conversion given)";
CM_ SG_ 760 DISP_SEC "BMW name DISP_SEC (Anzeige Sekunde[-]) - MEVD17.2 function description 15.3.3.1-DSPLECU_CO.md; range/values: 0 - 254; raw value (no conversion given)";
CM_ SG_ 760 DISP_DATE_DAY "BMW name DISP_DATE_DAY (Anzeige Tag [-]) - MEVD17.2 function description 15.3.3.1-DSPLECU_CO.md; range/values: 1 - 31; raw value (no conversion given)";
CM_ SG_ 760 DISP_DATE_WDAY "BMW name DISP_DATE_WDAY (Anzeige Wochentag [-]) - MEVD17.2 function description 15.3.3.1-DSPLECU_CO.md; range/values: 1 - 7; raw value (no conversion given)";
CM_ SG_ 760 DISP_DATE_MON "BMW name DISP_DATE_MON (Anzeige Monat [-]) - MEVD17.2 function description 15.3.3.1-DSPLECU_CO.md; range/values: 1 - 15 - Signal 12 ungültig; raw value (no conversion given)";
CM_ SG_ 760 DISP_DATE_YR "BMW name DISP_DATE_YR (Anzeige Jahr [-]) - MEVD17.2 function description 15.3.3.1-DSPLECU_CO.md; range/values: 1 - 65534 [-]; raw value (no conversion given)";
CM_ SG_ 760 ST_DISP_CTI_DATE "BMW name ST_DISP_CTI_DATE (Status Anzeige Uhrzeit [-]) - MEVD17.2 function description 15.3.3.1-DSPLECU_CO.md; range/values: ---0 Daten nicht ---1 Daten --0- --1-1111 gültig gültig Winterzeit Sommerzeit Signal ungültig; raw value (no conversion given)";
CM_ BO_ 762 "E92 M3 DCT 2011 K-CAN trace (superwofy/E9X-M-CAN-Integration-Module, MIT): 88 frames, DLC {5: 88}, median interval 5000 ms | Also on PT-CAN (JBE gateway); signals copied from BMW_E9x_PT-CAN_full.dbc | community DBC name: OccupancySeatBeltContact | SPdaten JBBF70.prg: 'Sitzbelegung Gurtkontakte' from ACSM | E65 message list: 'Sitzbelegung Gurtkontakte' from ACSM";
CM_ BO_ 764 "E92 M3 DCT 2011 K-CAN trace (superwofy/E9X-M-CAN-Integration-Module, MIT): 123 frames, DLC {7: 123}, median interval 5000 ms | Also on PT-CAN (JBE gateway); signals copied from BMW_E9x_PT-CAN_full.dbc | community DBC name: TrunkStatus | SPdaten JBBF70.prg: 'ZV und Klappenzustand' from CAS | superwofy note: '0x2FC Door hood boot status.txt' | E65 message list: 'ZV und Klappenzustand' from CAS | undefined bits changing in the trace: [0, 2, 4, 5, 7]";
CM_ SG_ 764 ST_DSW_DRD "BMW name ST_DSW_DRD (Status Türkontakt FAT) - MEVD17.2 function description 15.3.1.2-CASECU_co.md; formula: `-`; range/values: 0 - FAT ist 1 - FAT ist 2 - 3 - Signal geschlossen offen Signal unplausibel ungültig; raw value (no conversion given)";
CM_ SG_ 764 ST_CT_BON "BMW name ST_CT_BON (Status Kontakt Motorhaube) - MEVD17.2 function description 15.3.1.2-CASECU_co.md; formula: `-`; range/values: 0 - Motorhaube 1 - Motorhaube 3 - Signal geschlossen offen ungültig; raw value (no conversion given)";
CM_ BO_ 772 "E92 M3 DCT 2011 K-CAN trace (superwofy/E9X-M-CAN-Integration-Module, MIT): 556 frames, DLC {2: 556}, median interval 1000 ms | SPdaten JBBF70.prg: 'Status Gang' from EGS_EL | E65 message list: 'Status Gang' from SMG_M/SMG/EGS_MECH+NAVI/EGS_MECH/DKG | undefined bits changing in the trace: [0, 1, 2, 3, 4, 5]";
CM_ BO_ 774 "E92 M3 DCT 2011 K-CAN trace (superwofy/E9X-M-CAN-Integration-Module, MIT): 413 frames, DLC {2: 413}, median interval 1000 ms | SPdaten JBBF70.prg: 'Fahrzeugneigung' from FRMFA | E65 message list: 'Fahrzeugneigung' from LM | undefined bits changing in the trace: [1, 2, 3, 4, 5, 6, 7, 8, 11]";
CM_ BO_ 776 "E92 M3 DCT 2011 K-CAN trace (superwofy/E9X-M-CAN-Integration-Module, MIT): 844 frames, DLC {3: 844}, median interval 500 ms | Also on PT-CAN (JBE gateway); signals copied from BMW_E9x_PT-CAN_full.dbc | community DBC name: Status_MSA | SPdaten JBBF70.prg: 'Status MSA' from DME1/DDE1 | E65 message list: 'Status MSA' from DME1/DDE1";
CM_ SG_ 776 S308_b0 "MK60E5 FW 7846816A (M3) signal (internal var 0xB1), meaning unknown";
CM_ SG_ 776 S308_b4 "MK60E5 FW 7846816A (M3) signal (internal var 0xCE), meaning unknown";
CM_ SG_ 776 S308_b8 "MK60E5 FW 7846816A (M3) signal (internal var 0x78), meaning unknown";
CM_ SG_ 776 S308_b10 "MK60E5 FW 7846816A (M3) signal (internal var 0xA7), meaning unknown";
CM_ SG_ 776 S308_b12 "MK60E5 FW 7846816A (M3) signal (internal var 0xA8), meaning unknown";
CM_ SG_ 776 S308_b14 "MK60E5 FW 7846816A (M3) signal (internal var 0x95), meaning unknown";
CM_ SG_ 776 S308_b16 "MK60E5 FW 7846816A (M3) signal (internal var 0x85), meaning unknown";
CM_ SG_ 776 S308_b18 "MK60E5 FW 7846816A (M3) signal (internal var 0xAB), meaning unknown";
CM_ SG_ 776 S308_b20 "MK60E5 FW 7846816A (M3) signal (internal var 0xAE), meaning unknown";
CM_ BO_ 785 "E92 M3 DCT 2011 K-CAN trace (superwofy/E9X-M-CAN-Integration-Module, MIT): 20 frames, DLC {2: 20}, median interval 201 ms | SPdaten JBBF70.prg: 'Nachtankmenge' from Kombi | E65 message list: 'Nachtankmenge' from Kombi";
CM_ BO_ 786 "E92 M3 DCT 2011 K-CAN trace (superwofy/E9X-M-CAN-Integration-Module, MIT): 1 frames, DLC {2: 1} | SPdaten JBBF70.prg: 'Service Call Teleservice' from Kombi | E65 message list: 'Service Call Teleservice' from Kombi";
CM_ BO_ 787 "E92 M3 DCT 2011 K-CAN trace (superwofy/E9X-M-CAN-Integration-Module, MIT): 1 frames, DLC {2: 1} | SPdaten JBBF70.prg: 'Status Service Call Teleservice' from TEL_BPI | SPdaten JBBF70.prg: 'Status Service Call Teleservice' from CHAMP_M_ASK2/CCC_GW | E65 message list: 'Status Service Call Teleservice' from TEL_BPI | E65 message list: 'Status Service Call Teleservice' from M_ASK/CCC_GW";
CM_ BO_ 788 "E92 M3 DCT 2011 K-CAN trace (superwofy/E9X-M-CAN-Integration-Module, MIT): 203 frames, DLC {3: 203}, median interval 2048 ms | SPdaten JBBF70.prg: 'Status Fahrlicht' from FZD | superwofy note: '0x314 RLS status.txt' | E65 message list: 'Status Fahrlicht' from RLS | E65 message list: 'Status Fahrlicht' from LM";
CM_ SG_ 788 HeadlightRequest "superwofy/E9X-M-CAN-Integration-Module notes (MIT) (0x314 RLS status.txt): rain/light sensor requests the headlights";
CM_ BO_ 789 "E92 M3 DCT 2011 K-CAN trace (superwofy/E9X-M-CAN-Integration-Module, MIT): 846 frames, DLC {2: 846}, median interval 500 ms | Also on PT-CAN (JBE gateway); signals copied from BMW_E9x_PT-CAN_full.dbc | community DBC name: Vehicle_mode | SPdaten JBBF70.prg: 'Fahrzeugmodus' from JBBF | superwofy note: '0x315 trace EDC.txt' | E65 message list: 'Fahrzeugmodus' from SZM_MIT_KBUS/SZM";
CM_ SG_ 789 S315_b0 "superwofy/E9X-M-CAN-Integration-Module notes (MIT) (0x315 trace EDC.txt): changes with the counter and the mode; probably a checksum | superwofy/E9X-M-CAN-Integration-Module notes (MIT) (0x315 trace EDC.txt): changes with the counter and the mode; probably a checksum";
CM_ SG_ 789 Counter_315 "superwofy/E9X-M-CAN-Integration-Module notes (MIT) (0x315 trace EDC.txt): +1 per message | superwofy/E9X-M-CAN-Integration-Module notes (MIT) (0x315 trace EDC.txt): +1 per message";
CM_ SG_ 789 VehicleMode "superwofy/E9X-M-CAN-Integration-Module notes (MIT) (0x315 trace EDC.txt): EDC button / vehicle mode (JBBF); same content on PT-CAN and K-CAN | superwofy/E9X-M-CAN-Integration-Module notes (MIT) (0x315 trace EDC.txt): EDC button / vehicle mode (JBBF); same content on PT-CAN and K-CAN";
CM_ BO_ 791 "E92 M3 DCT 2011 K-CAN trace (superwofy/E9X-M-CAN-Integration-Module, MIT): 5 frames, DLC {2: 5} | SPdaten JBBF70.prg: 'Bedienung Taster Einparkhilfen' from IHKA | superwofy note: '0x317 PDC button.txt' | E65 message list: 'Bedienung Taster PDC' from SZM_MIT_KBUS/SZM";
CM_ SG_ 791 PDC_Button "superwofy/E9X-M-CAN-Integration-Module notes (MIT) (0x317 PDC button.txt): byte 0 = 0xFC released, 0xFD pressed";
CM_ BO_ 793 "E92 M3 DCT 2011 K-CAN trace (superwofy/E9X-M-CAN-Integration-Module, MIT): 6 frames, DLC {2: 6}, median interval 160 ms | Also on PT-CAN (JBE gateway); signals copied from BMW_E9x_PT-CAN_full.dbc | community DBC name: Operation_push_button_RDC | SPdaten JBBF70.prg: 'Bedienung Taster RDC' from Kombi | SPdaten JBBF70.prg: 'Bedienung Taster RDC' from JBBF | E65 message list: 'Bedienung Taster RDC' from SZM";
CM_ SG_ 793 S319_b0 "MK60E5 FW 7846816A (M3) signal (internal var 0x8A), meaning unknown | superwofy/E9X-M-CAN-Integration-Module notes (MIT): RPA (flat tyre monitor) reset button: byte 0 = 0xFC released, 0xFD pressed";
CM_ BO_ 797 "E92 M3 DCT 2011 K-CAN trace (superwofy/E9X-M-CAN-Integration-Module, MIT): 83 frames, DLC {2: 83}, median interval 5000 ms | Also on PT-CAN (JBE gateway); signals copied from BMW_E9x_PT-CAN_full.dbc | community DBC name: TirePressureStatus | SPdaten JBBF70.prg: 'Status Reifenpannenanzeige' from EHB3 | superwofy note: '0x31D FTM status.txt' | E65 message list: 'Status Reifenpannenanzeige' from DXC_RB/DSC_RB/DSC_CT";
CM_ SG_ 797 S31D_b0 "MK60E5 FW 7846816A (M3) signal (internal var 0x6C), meaning unknown | superwofy/E9X-M-CAN-Integration-Module notes (MIT): FTM (flat tyre monitor) state: byte 0 = 0x00 normal, 0x03 for about 10 s after a reset, 0x01 failure";
CM_ SG_ 797 S31D_b3 "MK60E5 FW 7846816A (M3) signal (internal var 0x4C), meaning unknown";
CM_ SG_ 797 S31D_b8 "MK60E5 FW 7846816A (M3) signal (internal var 0x34), meaning unknown";
CM_ BO_ 806 "E92 M3 DCT 2011 K-CAN trace (superwofy/E9X-M-CAN-Integration-Module, MIT): 2593 frames, DLC {2: 2593}, median interval 200 ms | SPdaten JBBF70.prg: 'Status Dämpferprogramm' from VDM | superwofy note: '0x326 EDC damper mode.txt' | E65 message list: 'Status DÃ¤mpferprogramm' from EDCK_Modul";
CM_ SG_ 806 DamperProgram "superwofy/E9X-M-CAN-Integration-Module notes (MIT) (0x326 EDC damper mode.txt): EDC damper program";
CM_ SG_ 806 Counter_326 "superwofy/E9X-M-CAN-Integration-Module notes (MIT) (0x326 EDC damper mode.txt): +1 per message";
CM_ BO_ 808 "E92 M3 DCT 2011 K-CAN trace (superwofy/E9X-M-CAN-Integration-Module, MIT): 523 frames, DLC {6: 523}, median interval 1000 ms | SPdaten JBBF70.prg: 'Relativzeit' from Kombi | E65 message list: 'Relativzeit' from Kombi | undefined bits changing in the trace: [0, 1, 2, 3, 4, 5, 6, 7, 8, 9, 10]";
CM_ BO_ 814 "E92 M3 DCT 2011 K-CAN trace (superwofy/E9X-M-CAN-Integration-Module, MIT): 413 frames, DLC {8: 413}, median interval 1000 ms | SPdaten JBBF70.prg: 'Status Klima Interne Regelinfo' from IHKA | E65 message list: 'Status Klima Interne Regelinfo' from IHKA | undefined bits changing in the trace: [24, 25, 26, 27, 28, 29, 30, 31, 32, 33, 34, 35, 36, 37, 38, 39, 40, 41, 42, 43, 44, 45, 46, 48, 49, 50, 56, 57, 58, 59, 60, 61]";
CM_ BO_ 818 "E92 M3 DCT 2011 K-CAN trace (superwofy/E9X-M-CAN-Integration-Module, MIT): 30 frames, DLC {2: 30}, median interval 160 ms | Also on PT-CAN (JBE gateway); signals copied from BMW_E9x_PT-CAN_full.dbc | community DBC name: Driver_display_speed_range | SPdaten JBBF70.prg: 'Fahreranzeige Drehzahlbereich' from DME1/DDE1 | E65 message list: 'Fahreranzeige Drehzahlbereich' from DME1/DDE1";
CM_ SG_ 818 RPM_TEMP_DOM_1 "BMW name RPM_TEMP_DOM_1 (variable engine speed warning field, actual value) - E65 doc (HeinrichG-V12/E65_ReverseEngineering, Bosch MED9.2.1); E65 definition, not yet verified on E9x";
CM_ SG_ 818 RPM_TEMP_DOM_2 "BMW name RPM_TEMP_DOM_2 (engine max RPM) - E65 doc (HeinrichG-V12/E65_ReverseEngineering, Bosch MED9.2.1); E65 definition, not yet verified on E9x";
CM_ BO_ 822 "E92 M3 DCT 2011 K-CAN trace (superwofy/E9X-M-CAN-Integration-Module, MIT): 36 frames, DLC {7: 36}, median interval 2401 ms | SPdaten JBBF70.prg: 'Anzeige Checkcontrol-Meldung (Rolle)' from Kombi | superwofy note: '0x336 CC list display.txt' | E65 message list: 'Anzeige Checkcontrol-Meldung (Rolle)' from Kombi";
CM_ SG_ 822 CC_List_MsgIndex "superwofy/E9X-M-CAN-Integration-Module notes (MIT) (0x336 CC list display.txt): number of this message in the sequence";
CM_ SG_ 822 CC_List_MsgCount "superwofy/E9X-M-CAN-Integration-Module notes (MIT) (0x336 CC list display.txt): total messages in the sequence, counting from 0";
CM_ SG_ 822 CC_List_ID1 "superwofy/E9X-M-CAN-Integration-Module notes (MIT) (0x336 CC list display.txt): Check Control ID shown in the vehicle status list";
CM_ SG_ 822 CC_List_ID2 "superwofy/E9X-M-CAN-Integration-Module notes (MIT) (0x336 CC list display.txt)";
CM_ SG_ 822 CC_List_ID3 "superwofy/E9X-M-CAN-Integration-Module notes (MIT) (0x336 CC list display.txt)";
CM_ BO_ 824 "E92 M3 DCT 2011 K-CAN trace (superwofy/E9X-M-CAN-Integration-Module, MIT): 103 frames, DLC {8: 103}, median interval 5000 ms | SPdaten JBBF70.prg: 'Steuerung Anzeige Checkcontrol-Meldung' from Kombi | E65 message list: 'Steuerung Anzeige Checkcontrol-Meldung' from Kombi | undefined bits changing in the trace: [0, 1, 2, 3, 4, 5, 6, 7, 8, 9, 16, 17, 19, 21, 22]";
CM_ BO_ 825 "E92 M3 DCT 2011 K-CAN trace (superwofy/E9X-M-CAN-Integration-Module, MIT): 1 frames, DLC {2: 1} | SPdaten JBBF70.prg: 'Status Anzeige Klima' from CHAMP_M_ASK2/CCC_GW | E65 message list: 'Status Anzeige Funktionen Extern' from M_ASK/CCC_GW";
CM_ BO_ 826 "E92 M3 DCT 2011 K-CAN trace (superwofy/E9X-M-CAN-Integration-Module, MIT): 55 frames, DLC {5: 55}, median interval 10001 ms | SPdaten JBBF70.prg: 'Status Monitor Front' from CID_C_H/CID_C | E65 message list: 'Status Monitor Front' from CID_C_H/CID_C | undefined bits changing in the trace: [14, 15, 24, 25]";
CM_ BO_ 840 "E92 M3 DCT 2011 K-CAN trace (superwofy/E9X-M-CAN-Integration-Module, MIT): 897 frames, DLC {8: 897}, median interval 422 ms | SPdaten ACC2.prg: 'Uebereinstimmung_Navigationsgraph' from CCC | E65 message list: 'Ãœbereinstimmung Navigationsgraph' from CCC_GW | undefined bits changing in the trace: [0, 1, 2, 3, 6, 7, 9, 10, 11, 12, 13, 14, 15, 18, 20, 21, 22, 23, 25, 26, 27, 28, 29, 30, 31, 32, 33, 34, 37, 38, 39, 41, 42, 43, 44, 45, 46, 47, 48, 49, 50, 51, 52, 53, 54, 55, 57]";
CM_ BO_ 841 "E92 M3 DCT 2011 K-CAN trace (superwofy/E9X-M-CAN-Integration-Module, MIT): 2593 frames, DLC {5: 2593}, median interval 200 ms | SPdaten JBBF70.prg: 'Rohdaten Füllstand Tank' from JBBF | undefined bits changing in the trace: [0, 1, 2, 3, 9, 10, 11, 12, 13, 14, 15, 16, 17, 18, 19, 20, 21, 22, 23, 24, 28, 29, 30, 31]";
CM_ BO_ 844 "E92 M3 DCT 2011 K-CAN trace (superwofy/E9X-M-CAN-Integration-Module, MIT): 376 frames, DLC {8: 376}, median interval 1023 ms | SPdaten ACC2.prg: 'Navigation_GPS_2' from CCC | E65 message list: 'Navigation GPS 2' from CCC_GW | undefined bits changing in the trace: [0, 1, 2, 3, 4, 5, 6, 7, 8, 9, 10, 11, 12, 13, 14, 16, 17, 18, 19, 20, 21, 22, 23, 24, 25, 26, 27, 28, 29, 30, 32, 33, 34, 35, 36, 37, 38, 39, 41, 42, 43, 45, 47]";
CM_ BO_ 846 "E92 M3 DCT 2011 K-CAN trace (superwofy/E9X-M-CAN-Integration-Module, MIT): 79 frames, DLC {8: 79}, median interval 5001 ms | SPdaten ACC2.prg: 'Navigation_System_Information' from CCC | E65 message list: 'Navigation System Information' from CCC_GW | undefined bits changing in the trace: [1, 2, 3, 4, 5, 6, 7, 8, 9, 10, 11, 12, 13, 14, 15, 16, 17, 18, 41, 42, 44, 46, 47, 48, 49, 51, 52, 53, 55, 57, 58, 60, 61, 63]";
CM_ BO_ 847 "E92 M3 DCT 2011 K-CAN trace (superwofy/E9X-M-CAN-Integration-Module, MIT): 103 frames, DLC {2: 103}, median interval 5002 ms | Also on PT-CAN (JBE gateway); signals copied from BMW_E9x_PT-CAN_full.dbc | community DBC name: Status_contact_handbrake | SPdaten JBBF70.prg: 'Status Kontakt Handbremse' from JBBF | superwofy note: '0x34F Handbrake status.txt'";
CM_ SG_ 847 Handbrake_push "superwofy/E9X-M-CAN-Integration-Module notes (MIT): Handbrake switch: byte 0 = 0xFE applied, 0xFD released";
CM_ BO_ 860 "E92 M3 DCT 2011 K-CAN trace (superwofy/E9X-M-CAN-Integration-Module, MIT): 84 frames, DLC {4: 84}, median interval 5000 ms | SPdaten JBBF70.prg: 'Status Bordcomputer' from Kombi | E65 message list: 'Status Bordcomputer' from Kombi";
CM_ SG_ 860 SpeedWarningOn "superwofy/E9X-M-CAN-Integration-Module notes (MIT) (0x2B8 Operation on-board computer and speed warning setting.txt (KOMBI response))";
CM_ SG_ 860 SpeedWarningLimit "superwofy/E9X-M-CAN-Integration-Module notes (MIT) (0x2B8 Operation on-board computer and speed warning setting.txt (KOMBI response))";
CM_ BO_ 862 "E92 M3 DCT 2011 K-CAN trace (superwofy/E9X-M-CAN-Integration-Module, MIT): 91 frames, DLC {8: 91}, median interval 5000 ms | SPdaten JBBF70.prg: 'Daten Bordcomputer (Reisedaten)' from Kombi | E65 message list: 'Daten Bordcomputer (Reisedaten)' from Kombi | undefined bits changing in the trace: [0, 16, 17, 19, 20, 21]";
CM_ BO_ 864 "E92 M3 DCT 2011 K-CAN trace (superwofy/E9X-M-CAN-Integration-Module, MIT): 83 frames, DLC {7: 83}, median interval 5000 ms | SPdaten JBBF70.prg: 'Daten Bordcomputer (Fahrtbeginn)' from Kombi | E65 message list: 'Daten Bordcomputer (Fahrtbeginn)' from Kombi";
CM_ BO_ 866 "E92 M3 DCT 2011 K-CAN trace (superwofy/E9X-M-CAN-Integration-Module, MIT): 90 frames, DLC {7: 90}, median interval 5000 ms | SPdaten JBBF70.prg: 'Daten Bordcomputer (Durchschnittswerte)' from Kombi | E65 message list: 'Daten Bordcomputer (Durchschnittswerte)' from Kombi | undefined bits changing in the trace: [0, 1, 2, 3, 4, 12, 24, 25]";
CM_ BO_ 868 "E92 M3 DCT 2011 K-CAN trace (superwofy/E9X-M-CAN-Integration-Module, MIT): 83 frames, DLC {7: 83}, median interval 5000 ms | SPdaten JBBF70.prg: 'Daten Bordcomputer (Ankunft)' from Kombi | E65 message list: 'Daten Bordcomputer (Ankunft)' from Kombi";
CM_ BO_ 870 "E92 M3 DCT 2011 K-CAN trace (superwofy/E9X-M-CAN-Integration-Module, MIT): 91 frames, DLC {4: 91}, median interval 5000 ms | SPdaten JBBF70.prg: 'Anzeige Kombi/Externe Anzeige' from Kombi | E65 message list: 'Anzeige Kombi/Externe Anzeige' from Kombi | undefined bits changing in the trace: [12, 13]";
CM_ BO_ 871 "E92 M3 DCT 2011 K-CAN trace (superwofy/E9X-M-CAN-Integration-Module, MIT): 163 frames, DLC {7: 163}, median interval 53 ms | SPdaten JBBF70.prg: 'Steuerung Anzeige Bedarfsorientierter Service' from Kombi | E65 message list: 'Steuerung Anzeige Bedarfsorientierter Service' from Kombi | undefined bits changing in the trace: [4, 5, 6, 8, 9, 10, 12, 13, 24, 26, 27, 28, 31, 32, 33, 35, 36, 37, 38, 39, 42, 43, 44, 47, 49]";
CM_ BO_ 877 "Not in the E92 M3 trace (CCC iDrive or option not fitted on that car); DLC from the superwofy note | SPdaten JBBF70.prg: 'Einstellung Schalter Fahrdynamik' from JBBF | superwofy note: '0x36D Rear PDC distance.txt'";
CM_ SG_ 877 PDC_Rear_OuterRight "superwofy/E9X-M-CAN-Integration-Module notes (MIT) (0x36D Rear PDC distance.txt): raw distance, smaller = closer; scaling unknown";
CM_ SG_ 877 PDC_Rear_InnerRight "superwofy/E9X-M-CAN-Integration-Module notes (MIT) (0x36D Rear PDC distance.txt): raw distance, smaller = closer; scaling unknown";
CM_ SG_ 877 PDC_Rear_InnerLeft "superwofy/E9X-M-CAN-Integration-Module notes (MIT) (0x36D Rear PDC distance.txt): raw distance, smaller = closer; scaling unknown";
CM_ SG_ 877 PDC_Rear_OuterLeft "superwofy/E9X-M-CAN-Integration-Module notes (MIT) (0x36D Rear PDC distance.txt): raw distance, smaller = closer; scaling unknown";
CM_ BO_ 897 "E92 M3 DCT 2011 K-CAN trace (superwofy/E9X-M-CAN-Integration-Module, MIT): 54 frames, DLC {2: 54}, median interval 10000 ms | Also on PT-CAN (JBE gateway); signals copied from BMW_E9x_PT-CAN_full.dbc | community DBC name: EngineOilLevel | SPdaten JBBF70.prg: 'Elektronischer Motorölmessstab' from DME1/DDE1 | superwofy note: '0x381 Oil level.txt' | E65 message list: 'Elektronischer MotorÃ¶lmessstab' from DME1/DDE1";
CM_ SG_ 897 FLLV_EOI "BMW name FLLV_EOI (Füllstand Motoröl) - MEVD17.2 function description 15.3.4.3-EngECU_co.md; range/values: 124 - 125 - 128 - 12 - 25 - 38 - Zustand zwischen 53 - 69 - Zustand zwischen 85 - 95 - 120 - 121 - 122 - Zustand Oil Level 123 - Zustand Zündung AUS, Motorölstand OK, 126 - 127 - Genaue Messung läuft. 0xFF - Zustand unter MIN Zustand MIN MIN und OK Zustand OK OK und MAX Zustand MAX Zustand Überfüllt Zustand keine Messung möglich Zustand Messung läuft Check OK Zustand Messung OK keine Messung möglich genaue Messung läuft. Motorölstand OK Messung läuft Messdauer: Signal ungültig 1min; raw value (no conversion given)";
CM_ SG_ 897 RECM_RFLV_EOI "BMW name RECM_RFLV_EOI (Erforderliche Nachfüllmenge Motoröl) - MEVD17.2 function description 15.3.4.3-EngECU_co.md; range/values: 0 - alles OK 1 - Überfüllung 2 - 1.0 L nachfüllen 4 - Service 0x0F - Signal ungültig; raw value (no conversion given)";
CM_ BO_ 904 "E92 M3 DCT 2011 K-CAN trace (superwofy/E9X-M-CAN-Integration-Module, MIT): 2 frames, DLC {7: 2} | Also on PT-CAN (JBE gateway); signals copied from BMW_E9x_PT-CAN_full.dbc | community DBC name: Vehicle_type | SPdaten JBBF70.prg: 'Fahrzeugtyp' from CAS | E65 message list: 'Fahrzeugtyp' from CAS";
CM_ SG_ 904 TYP_VEH "MK60E5 FW 7846816A (M3) signal (internal var 0xD8), meaning unknown | previous name (firmware field): S388_b0 | BMW name TYP_FAHRZEUG (Typ_Fahrzeug) - MEVD17.2 function description 15.3.1.2-CASECU_co.md; range/values: 0 Keine 2 4 5 7 9 255 Signal Angabe 1 E65 E66 3 E67 E60 E61 6 E63 E64 8 E90 RR01 10 E81 11 E82 12 E87 13 E91 14 E92 15 E93 16 E70 17 E71 18 E88 19 R55 20 R56 21 R57 22 E89 23 E72 24 F01 25 F02 26 F03 27 F07 28 F10 29 F11 30 F12 31 F13 32 F04 33 F31 34 F32 35 F33 36 F20 37 F30 38 F22 39 F23 40 E84 41 F25 42 R60 43 RR4 ungültig; raw value (no conversion given) | previous name (firmware field): TYP_FAHRZEUG";
CM_ SG_ 904 TYP_BODY "MK60E5 FW 7846816A (M3) signal (internal var 0xBF), meaning unknown | previous name (firmware field): S388_b8 | BMW name TYP_BODY (Typ_Karosserie) - MEVD17.2 function description 15.3.1.2-CASECU_co.md; range/values: 0000 0000 0000 0000 0000 0000 1000 Light 0000 1001 0000 1010 4 x 4 0000 1011 4 x 0000 1100 MCV 0000 1101 BEV 0xFF 0001 Limousine 0000 0010 Coupe 0000 0011 Touring 0100 Cabrio 0101 Roadster 0110 Compact 0111 Sicherheitsfahrzeug Protection Sport-Coupe (Z3 Coupe) single piece tailgate 4 two piece tailgate Mega-City-Vehicle Battery-Electric-Vehicle Signal ungueltig; raw value (no conversion given)";
CM_ SG_ 904 QUAN_CYL "MK60E5 FW 7846816A (M3) signal (internal var 0xBA), meaning unknown | previous name (firmware field): S388_b16 | BMW name QUAN_CYL (cylinder number) - E65 doc (HeinrichG-V12/E65_ReverseEngineering, Bosch MED9.2.1)";
CM_ SG_ 904 QUAN_GR "MK60E5 FW 7846816A (M3) signal (internal var 0x8F), meaning unknown | previous name (firmware field): S388_b20 | BMW name ANZAHL_GANG (Anzahl_Gang) - MEVD17.2 function description 15.3.1.2-CASECU_co.md; range/values: 7 - 7 Gänge Wird 4 - 4 5 - 5 6 - 6 derzeit nur 8 - 8 15 0 Stufenlos Gänge Gänge Gänge in M-Fahrzeugen genutzt! Gänge Signal ungültig (Für SMG Mk3); raw value (no conversion given) | previous name (firmware field): ANZAHL_GANG";
CM_ SG_ 904 TYP_ENG "MK60E5 FW 7846816A (M3) signal (internal var 0x90), meaning unknown | previous name (firmware field): S388_b24 | BMW name TYP_ENG (engine type) - E65 doc (HeinrichG-V12/E65_ReverseEngineering, Bosch MED9.2.1)";
CM_ SG_ 904 TYP_STE "BMW name TYP_STE (steering type) - E65 doc (HeinrichG-V12/E65_ReverseEngineering, Bosch MED9.2.1); E65 definition, not yet verified on E9x";
CM_ SG_ 904 TYP_GRB "MK60E5 FW 7846816A (M3) signal (internal var 0xBD), meaning unknown | previous name (firmware field): S388_b32 | BMW name TYP_GRB (gearbox type) - E65 doc (HeinrichG-V12/E65_ReverseEngineering, Bosch MED9.2.1)";
CM_ SG_ 904 CLAS_PWR "BMW name CLAS_PWR (Klasse_Leistung) - MEVD17.2 function description 15.3.1.2-CASECU_co.md; range/values: 00 Untere 01 Mittlere 10 Obere 0x3 Signal Leistungsklasse (UL) Leistungsklasse (ML) Leistungsklasse (OL) OL und ungueltig TOP; raw value (no conversion given)";
CM_ SG_ 904 TYP_CNT "MK60E5 FW 7846816A (M3) signal (internal var 0xBE), meaning unknown | previous name (firmware field): S388_b40 | BMW name TYP_CNT - E65 doc (HeinrichG-V12/E65_ReverseEngineering, Bosch MED9.2.1)";
CM_ SG_ 904 TYP_CAPA "MK60E5 FW 7846816A (M3) signal (internal var 0xBC), meaning unknown | previous name (firmware field): S388_b48 | BMW name TYP_CAPA (engine diplacement) - E65 doc (HeinrichG-V12/E65_ReverseEngineering, Bosch MED9.2.1)";
CM_ BO_ 906 "E92 M3 DCT 2011 K-CAN trace (superwofy/E9X-M-CAN-Integration-Module, MIT): 12 frames, DLC {2: 12}, median interval 7010 ms | undefined bits changing in the trace: [0, 1]";
CM_ BO_ 907 "E92 M3 DCT 2011 K-CAN trace (superwofy/E9X-M-CAN-Integration-Module, MIT): 3 frames, DLC {5: 3} | Also on PT-CAN (JBE gateway); signals copied from BMW_E9x_PT-CAN_full.dbc | community DBC name: Status_battery | SPdaten JBBF70.prg: 'Status Batterie' from DME1/DDE1";
CM_ BO_ 911 "Not in the E92 M3 trace (CCC iDrive or option not fitted on that car); DLC from the superwofy note | superwofy note: '0x38F 0x39B Rear view camera settings.txt'";
CM_ SG_ 911 Camera "superwofy/E9X-M-CAN-Integration-Module notes (MIT) (0x38F 0x39B Rear view camera settings.txt): camera settings request from CIC";
CM_ SG_ 911 TowView "superwofy/E9X-M-CAN-Integration-Module notes (MIT) (0x38F 0x39B Rear view camera settings.txt)";
CM_ SG_ 911 CameraSetting1 "superwofy/E9X-M-CAN-Integration-Module notes (MIT) (0x38F 0x39B Rear view camera settings.txt): changes with the contrast setting; scaling unclear";
CM_ SG_ 911 CameraSetting2 "superwofy/E9X-M-CAN-Integration-Module notes (MIT) (0x38F 0x39B Rear view camera settings.txt): changes with the brightness setting; scaling unclear";
CM_ BO_ 916 "E92 M3 DCT 2011 K-CAN trace (superwofy/E9X-M-CAN-Integration-Module, MIT): 4 frames, DLC {8: 4} | SPdaten JBBF70.prg: 'RDA Anfrage/Datenablage' from Kombi | E65 message list: 'RDA Anfrage/Datenablage' from Kombi | undefined bits changing in the trace: [2, 3, 8, 9, 10, 11, 16, 18, 19, 20, 21, 22, 23, 24, 25, 26, 27, 28, 29, 30, 31, 33, 34, 35, 36, 39, 41, 43, 44, 45, 46, 47, 48, 49, 50, 51, 52, 53, 54, 55, 56, 57, 60, 61, 62, 63]";
CM_ BO_ 917 "E92 M3 DCT 2011 K-CAN trace (superwofy/E9X-M-CAN-Integration-Module, MIT): 1 frames, DLC {5: 1} | Also on PT-CAN (JBE gateway); signals copied from BMW_E9x_PT-CAN_full.dbc | community DBC name: Coding_power_management | SPdaten JBBF70.prg: 'Codierung Powermanagement' from CAS | E65 message list: 'Codierung Powermanagement' from CAS";
CM_ SG_ 917 CLAS_BT "BMW name CLAS_BT (Klasse Batterie) - MEVD17.2 function description 15.3.1.2-CASECU_co.md; formula: `-`; range/values: 0 - 254; raw value (no conversion given)";
CM_ SG_ 917 QC_VEH "BMW name QC_VEH (Ruhestrom Fahrzeug) - MEVD17.2 function description 15.3.1.2-CASECU_co.md; formula: `-`; range/values: 0 - 254 [mA]";
CM_ SG_ 917 I_SC_MIN_VEH "BMW name I_SC_MIN_VEH (Strom Kurzschluss Kurzschluss Minimal) - MEVD17.2 function description 15.3.1.2-CASECU_co.md; formula: `-`; range/values: 0 - 1000 [A]; raw value (no conversion given)";
CM_ SG_ 917 I_SC_MAX_VEH "BMW name I_SC_MAX_VEH (Strom Kurzschluss Maximal) - MEVD17.2 function description 15.3.1.2-CASECU_co.md; formula: `-`; range/values: 0 - 1000 [A]; raw value (no conversion given)";
CM_ BO_ 921 "E92 M3 DCT 2011 K-CAN trace (superwofy/E9X-M-CAN-Integration-Module, MIT): 99 frames, DLC {6: 99}, median interval 1075 ms | Also on PT-CAN (JBE gateway); signals copied from BMW_E9x_PT-CAN_full.dbc; PT-CAN DLC 5 | community DBC name: Status_MDrive | SPdaten JBBF70.prg: 'Status M-Drive' from DME1 | E65 message list: 'Status M-Drive' from DME1 | undefined bits changing in the trace: [13, 14, 16, 36, 38, 39, 43, 44]";
CM_ SG_ 921 CHKSM_399 "BMW 4-bit checksum: s = fold8(sum(bytes, checksum nibble = 0) + 0x9C); chk = ((s >> 4) + (s & 0xF)) & 0xF - verified 99/99 in the E92 M3 K-CAN trace (superwofy); algorithm as in the superwofy firmware";
CM_ SG_ 921 ALIV_399 "MK60E5 FW 7846816A (M3) signal (internal var 0xCD), meaning unknown | 4-bit alive counter, counts 0..14, +1 per frame (E92 M3 K-CAN trace)";
CM_ SG_ 921 S399_b8 "MK60E5 FW 7846816A (M3) signal (internal var 0x7C), meaning unknown | superwofy/E9X-M-CAN-Integration-Module notes (MIT): firmware update_mdrive_settings_can_message(): +1 on byte 1 when M-Drive is active";
CM_ SG_ 921 S399_b10 "MK60E5 FW 7846816A (M3) signal (internal var 0xA5), meaning unknown | superwofy/E9X-M-CAN-Integration-Module notes (MIT): DSC mode stored in the M-Drive setting (firmware: byte 1 = 0x05 off, 0x09 on, 0x11 MDM, +1 when active). The M3 DSC firmware reads this field; with M3/1M DSC software MDM is selected through 0x399 only. E92 M3 trace: byte 1 = 0x51 (MDM, M-Drive inactive)";
CM_ BO_ 923 "Not in the E92 M3 trace (CCC iDrive or option not fitted on that car); DLC from the superwofy note | superwofy note: '0x38F 0x39B Rear view camera settings.txt'";
CM_ SG_ 923 CameraStatus "superwofy/E9X-M-CAN-Integration-Module notes (MIT) (0x38F 0x39B Rear view camera settings.txt): camera status from TRSVC";
CM_ SG_ 923 CameraSetting1 "superwofy/E9X-M-CAN-Integration-Module notes (MIT) (0x38F 0x39B Rear view camera settings.txt): same as 0x38F byte 1";
CM_ SG_ 923 CameraSetting2 "superwofy/E9X-M-CAN-Integration-Module notes (MIT) (0x38F 0x39B Rear view camera settings.txt): same as 0x38F byte 2";
CM_ SG_ 923 TowView "superwofy/E9X-M-CAN-Integration-Module notes (MIT) (0x38F 0x39B Rear view camera settings.txt)";
CM_ BO_ 936 "Not in the E92 M3 trace (CCC iDrive or option not fitted on that car); DLC from the superwofy note | superwofy note: '0x3A8 0x3A9 DME POWER CKM.txt'";
CM_ SG_ 936 PowerMode_CKM "superwofy/E9X-M-CAN-Integration-Module notes (MIT) (0x3A8 0x3A9 DME POWER CKM.txt): DME POWER setting (car key memory)";
CM_ BO_ 937 "E92 M3 DCT 2011 K-CAN trace (superwofy/E9X-M-CAN-Integration-Module, MIT): 4 frames, DLC {2: 4} | SPdaten JBBF70.prg: 'Status Motorsteuerung CKM' from DME1 | superwofy note: '0x3A8 0x3A9 DME POWER CKM.txt'";
CM_ SG_ 937 PowerMode_CKM "superwofy/E9X-M-CAN-Integration-Module notes (MIT) (0x3A8 0x3A9 DME POWER CKM.txt): DME POWER setting (car key memory), sent at terminal R";
CM_ BO_ 939 "E92 M3 DCT 2011 K-CAN trace (superwofy/E9X-M-CAN-Integration-Module, MIT): 5 frames, DLC {2: 5} | SPdaten JBBF70.prg: 'Status Shiftlights CKM' from Kombi";
CM_ BO_ 940 "E92 M3 DCT 2011 K-CAN trace (superwofy/E9X-M-CAN-Integration-Module, MIT): 59 frames, DLC {2: 59}, median interval 10002 ms | Also on PT-CAN (JBE gateway); signals copied from BMW_E9x_PT-CAN_full.dbc | community DBC name: RunOnTimeTerminal30 | SPdaten JBBF70.prg: 'Nachlaufzeit Klemme 30 fehlergesteuert' from JBBF | E65 message list: 'Nachlaufzeit Klemme 30 fehlergesteuert' from KGM";
CM_ BO_ 942 "Not in the E92 M3 trace (CCC iDrive or option not fitted on that car); DLC from the superwofy note | superwofy note: '0x3AE Camera control from iDrive.txt'";
CM_ SG_ 942 CameraControl "superwofy/E9X-M-CAN-Integration-Module notes (MIT) (0x3AE Camera control from iDrive.txt)";
CM_ BO_ 943 "Not in the E92 M3 trace (CCC iDrive or option not fitted on that car); DLC from the superwofy note | superwofy note: '0x3AF PDC bus states.txt'";
CM_ SG_ 943 Counter_3AF "superwofy/E9X-M-CAN-Integration-Module notes (MIT) (0x3AF PDC bus states.txt): +1 per message";
CM_ SG_ 943 PDC_Active "superwofy/E9X-M-CAN-Integration-Module notes (MIT) (0x3AF PDC bus states.txt)";
CM_ SG_ 943 Camera_Active "superwofy/E9X-M-CAN-Integration-Module notes (MIT) (0x3AF PDC bus states.txt)";
CM_ SG_ 943 PDC_DisplayActive "superwofy/E9X-M-CAN-Integration-Module notes (MIT) (0x3AF PDC bus states.txt): visual PDC / camera shown on the display";
CM_ BO_ 947 "E92 M3 DCT 2011 K-CAN trace (superwofy/E9X-M-CAN-Integration-Module, MIT): 1304 frames, DLC {6: 1304}, median interval 160 ms | Also on PT-CAN (JBE gateway); signals copied from BMW_E9x_PT-CAN_full.dbc | community DBC name: PowerManagmentConsumptionControl | SPdaten JBBF70.prg: 'Powermanagement Verbrauchersteuerung' from DME1/DDE1 | E65 message list: 'Powermanagement Verbrauchersteuerung' from DME1/DDE1";
CM_ SG_ 947 SLCTN_SPCOS "BMW name SLCTN_SPCOS (Auswahl Sonderverbraucher) - MEVD17.2 function description 15.3.4.3-EngECU_co.md; range/values: 0 ... Kein 1 ... 0x0F ... Sonderverbraucher PTC Zuheizer Signal ungültig; raw value (no conversion given)";
CM_ SG_ 947 CTR_PWR_SPCOS "BMW name CTR_PWR_SPCOS (Steuerung Leistung Sonderverbraucher) - MEVD17.2 function description 15.3.4.3-EngECU_co.md; range/values: 0 - 0xFF - 100% Signal ungültig; raw value (no conversion given)";
CM_ SG_ 947 CTR_PWR_COS "BMW name CTR_PWR_COS (Steuerung Leistung Leistung Verbraucher) - MEVD17.2 function description 15.3.4.3-EngECU_co.md; range/values: 0--- 0--- -1-- ---- 0--- ---- 0--- ---- ---- -1-- 0--- ---- ---- ---- --1- ---- Sitzheizung 0--- ---- 0--- ---- 1--- ---- PTC 0--- --1- ---- ---- Lenkradheizung 0--- 1--- 0000 0000 0000 0--- ---- ---- ---1 ---- --1- Lenkradheizung getaktet, Sitzheizung vorne 1--- Sitzheizung vorne 0--- ---- ---1 ---- hinten Stufe 2, -1-- ---- Spiegelheizung hinten 50%, 0--- ---1 ---- ---- ---- Sitzheizung vorne AUS, PTC dritte ---- ---- Sitzklima AUS, 0--1 ---- ---- ---- 0-1- ---- ---- ---- 01-- ---- ---- ---- 0xFFFF - 0000 Keine Reduzierung Heckscheibe getaktet Lenkradheizung getaktet, PTC Stufe 2, Sitzheizung 50%, PTC dritte Aktivsitz AUS PTC hinten 75%, AUS, PTC hinten Frontscheibenheizung 50%, Heckscheibe AUS AUS, Sitzheizung Sitzreihe / Gebläse Frontscheibenheizung Heizungsgebläse 75% Heizungsgebläse 50% Heizungsgebläse 25% Signal ungültig hinten 25% hinten Stufe 1 Sitzreihe 50% Frontscheibenheizung AUS Nackenwärmer AUS hinten AUS 0%, Frontscheibenheizung AUS 75% 25%; raw value (no conversion given)";
CM_ SG_ 947 CTR_CBR "BMW name CTR_CBR (Steuerung Stromzweige) - MEVD17.2 function description 15.3.4.3-EngECU_co.md; range/values: 0--- ---0 Keine 0--- ---1 0--- --01 0--- --11 0--- -0-1 0--- -1-1 0xFF - Ansteuerung Ansteuerung Stromzweig 1 AUS Stromzweig 1 EIN Stromzweig 2 AUS Stromzweig 2 EIN Signal ungültig; raw value (no conversion given)";
CM_ SG_ 947 RQ_PCOS "BMW name RQ_PCOS (Anforderung Standverbraucher) - MEVD17.2 function description 15.3.4.3-EngECU_co.md; range/values: 1 ... 0 ... Keine Standverbraucher 2 ... 3 ... Signal Aktion müssen sich zu erkennen unbelegt ungültig geben; raw value (no conversion given)";
CM_ SG_ 947 CTR_PCOS "BMW name CTR_PCOS (Steuerung Standverbraucher) - MEVD17.2 function description 15.3.4.3-EngECU_co.md; range/values: 0 ... Keine Aktion 1 ... Spezielle Standverbraucher dürfen sich einschalten 2 ... Standverbraucher müssen sich abschalten 3 ... Signal ungültig; raw value (no conversion given)";
CM_ BO_ 948 "E92 M3 DCT 2011 K-CAN trace (superwofy/E9X-M-CAN-Integration-Module, MIT): 304 frames, DLC {8: 304}, median interval 161 ms | Also on PT-CAN (JBE gateway); signals copied from BMW_E9x_PT-CAN_full.dbc | community DBC name: PowerBatteryVoltage | SPdaten JBBF70.prg: 'Powermanagement Batteriespannung' from DME1/DDE1 | E65 message list: 'Powermanagement Batteriespannung' from DME1/DDE1 | undefined bits changing in the trace: [24]";
CM_ SG_ 948 U_BT "BMW name U_BT - E65 doc (HeinrichG-V12/E65_ReverseEngineering, Bosch MED9.2.1); replaces BatteryVoltage 7|24 (community BatteryVoltage 24-bit big-endian decodes to 16777 V; U_BT = 0xFFF (invalid) in 320i log)";
CM_ SG_ 948 ST_BTSW "BMW name ST_BTSW (status battery main switch) - E65 doc (HeinrichG-V12/E65_ReverseEngineering, Bosch MED9.2.1); E65 definition, not yet verified on E9x";
CM_ SG_ 948 ENG_ST "BMW name ENG_ST - E65 doc (HeinrichG-V12/E65_ReverseEngineering, Bosch MED9.2.1); E65 definition, not yet verified on E9x";
CM_ SG_ 948 ST_SWO_KL_30 "BMW name ST_SWO_KL_30 - E65 doc (HeinrichG-V12/E65_ReverseEngineering, Bosch MED9.2.1); E65 definition, not yet verified on E9x";
CM_ SG_ 948 SDWN_COU_BTSW "BMW name SDWN_COU_BTSW - E65 doc (HeinrichG-V12/E65_ReverseEngineering, Bosch MED9.2.1); E65 definition, not yet verified on E9x";
CM_ BO_ 950 "E92 M3 DCT 2011 K-CAN trace (superwofy/E9X-M-CAN-Integration-Module, MIT): 28 frames, DLC {3: 28}, median interval 160 ms | SPdaten JBBF70.prg: 'Position Fensterheber FAT' from FRMFA | E65 message list: 'Position Fensterheber FAT' from KGM | undefined bits changing in the trace: [0, 1, 2, 3, 8, 19, 20]";
CM_ BO_ 951 "E92 M3 DCT 2011 K-CAN trace (superwofy/E9X-M-CAN-Integration-Module, MIT): 7 frames, DLC {3: 7}, median interval 161 ms | SPdaten JBBF70.prg: 'Position Fensterheber FATH' from JBBF | E65 message list: 'Position Fensterheber FATH' from KBM";
CM_ BO_ 952 "E92 M3 DCT 2011 K-CAN trace (superwofy/E9X-M-CAN-Integration-Module, MIT): 4 frames, DLC {3: 4} | SPdaten JBBF70.prg: 'Position Fensterheber BFT' from FRMFA | E65 message list: 'Position Fensterheber BFT' from KGM";
CM_ BO_ 953 "E92 M3 DCT 2011 K-CAN trace (superwofy/E9X-M-CAN-Integration-Module, MIT): 7 frames, DLC {3: 7}, median interval 202 ms | SPdaten JBBF70.prg: 'Position Fensterheber BFTH' from JBBF | E65 message list: 'Position Fensterheber BFTH' from KBM";
CM_ BO_ 957 "E92 M3 DCT 2011 K-CAN trace (superwofy/E9X-M-CAN-Integration-Module, MIT): 487 frames, DLC {2: 487}, median interval 5000 ms | SPdaten JBBF70.prg: 'Status Verbraucherabschaltung' from FRMFA | superwofy note: '0x3BD FRM consumer status.txt' | E65 message list: 'Status Verbraucherabschaltung' from KBM";
CM_ SG_ 957 ConsumerShutdown "superwofy/E9X-M-CAN-Integration-Module notes (MIT) (0x3BD FRM consumer status.txt): byte 0 = 0xFD normal, 0xFC when the 30g relay is about to switch off";
CM_ BO_ 958 "E92 M3 DCT 2011 K-CAN trace (superwofy/E9X-M-CAN-Integration-Module, MIT): 277 frames, DLC {2: 277}, median interval 10000 ms | Also on PT-CAN (JBE gateway); signals copied from BMW_E9x_PT-CAN_full.dbc | community DBC name: PowerRunningTime | SPdaten JBBF70.prg: 'Nachlaufzeit Stromversorgung' from CAS | superwofy note: '0x3BE Power supply follow-up time.txt' | E65 message list: 'Nachlaufzeit Stromversorgung' from CAS";
CM_ SG_ 958 FLLUPT_GPWSUP "BMW name FLLUPT_GPWSUP (Nachlaufzeit_Stromversorgung) - MEVD17.2 function description 15.3.1.2-CASECU_co.md; formula: PHYS = 10*HEX [s]; range/values: 0..FFD FFE 0xFFF Restlaufzeit Dauer EIN Signal ungueltig";
CM_ BO_ 961 "E92 M3 DCT 2011 K-CAN trace (superwofy/E9X-M-CAN-Integration-Module, MIT): 1 frames, DLC {3: 1} | SPdaten JBBF70.prg: 'Konfiguration BFS' from SM_BF | E65 message list: 'Konfiguration BFS' from SM_BF";
CM_ BO_ 964 "E92 M3 DCT 2011 K-CAN trace (superwofy/E9X-M-CAN-Integration-Module, MIT): 5 frames, DLC {2: 5} | SPdaten JBBF70.prg: 'Status EDCK CKM' from JBBF";
CM_ BO_ 970 "E92 M3 DCT 2011 K-CAN trace (superwofy/E9X-M-CAN-Integration-Module, MIT): 19 frames, DLC {5: 19}, median interval 2000 ms | E65 message list: 'Konfiguration M-Drive' from M_ASK/CCC_GW | undefined bits changing in the trace: [4, 5, 6, 8, 10, 12, 13, 17, 19, 21, 24, 28, 29, 32, 35, 36]";
CM_ BO_ 972 "E92 M3 DCT 2011 K-CAN trace (superwofy/E9X-M-CAN-Integration-Module, MIT): 117 frames, DLC {7: 117}, median interval 161 ms | undefined bits changing in the trace: [0, 1, 2, 3, 4, 5, 6, 40, 41, 42, 43, 44, 45, 46, 47, 48, 49, 50, 51]";
CM_ BO_ 981 "E92 M3 DCT 2011 K-CAN trace (superwofy/E9X-M-CAN-Integration-Module, MIT): 6 frames, DLC {2: 6}, median interval 159 ms | SPdaten JBBF70.prg: 'Status Zentralverriegelung CKM' from CAS | E65 message list: 'Status Zentralverriegelung CKM' from CAS";
CM_ BO_ 983 "E92 M3 DCT 2011 K-CAN trace (superwofy/E9X-M-CAN-Integration-Module, MIT): 3 frames, DLC {3: 3} | SPdaten JBBF70.prg: 'Status DWA CKM' from FZD | SPdaten JBBF70.prg: 'Status DWA CKM' from DWA | superwofy note: '0x3D7 DWA Alarm CKM.txt' | E65 message list: 'Status DWA CKM' from DWA";
CM_ SG_ 983 LockVisualSignal_CKM "superwofy/E9X-M-CAN-Integration-Module notes (MIT) (0x3D7 DWA Alarm CKM.txt): visual signal when locking/unlocking";
CM_ BO_ 985 "E92 M3 DCT 2011 K-CAN trace (superwofy/E9X-M-CAN-Integration-Module, MIT): 7 frames, DLC {2: 7}, median interval 98 ms | SPdaten JBBF70.prg: 'Status RLS CKM' from FZD | E65 message list: 'Status RLS CKM' from RLS | E65 message list: 'Status RLS CKM' from LM | undefined bits changing in the trace: [0, 2]";
CM_ BO_ 987 "Not in the E92 M3 trace (CCC iDrive or option not fitted on that car); DLC from the superwofy note | SPdaten JBBF70.prg: 'Status Memorypositionen CKM' from SM_FA | superwofy note: '0x3DB Seat CKM.txt' | E65 message list: 'Status Memorypositionen CKM' from SZM_MIT_KBUS | E65 message list: 'Status Memorypositionen CKM' from SM_FA";
CM_ SG_ 987 SeatLastPosition_CKM "superwofy/E9X-M-CAN-Integration-Module notes (MIT) (0x3DB Seat CKM.txt): last seat position automatically";
CM_ BO_ 989 "E92 M3 DCT 2011 K-CAN trace (superwofy/E9X-M-CAN-Integration-Module, MIT): 3 frames, DLC {3: 3} | SPdaten JBBF70.prg: 'Status Licht CKM' from FRMFA | superwofy note: '0x3DD Lights CKM.txt' | E65 message list: 'Status Licht CKM' from LM";
CM_ SG_ 989 DaytimeRunningLights_CKM "superwofy/E9X-M-CAN-Integration-Module notes (MIT) (0x3DD Lights CKM.txt)";
CM_ BO_ 991 "E92 M3 DCT 2011 K-CAN trace (superwofy/E9X-M-CAN-Integration-Module, MIT): 20 frames, DLC {3: 20}, median interval 162 ms | SPdaten JBBF70.prg: 'Status Klima CKM' from IHKA | superwofy note: '0x2E6 0x3DF auto climate status.txt' | E65 message list: 'Status Klima CKM' from IHKA";
CM_ SG_ 991 AutoFanIntensity "superwofy/E9X-M-CAN-Integration-Module notes (MIT) (0x2E6 0x3DF auto climate status.txt): only these values documented; the M3 trace also has 0, 2 and 0xA";
CM_ BO_ 1009 "E92 M3 DCT 2011 K-CAN trace (superwofy/E9X-M-CAN-Integration-Module, MIT): 3 frames, DLC {2: 3} | SPdaten JBBF70.prg: 'Status Licht Erweitert CKM' from FRMFA | E65 message list: 'Status Licht Erweitert CKM' from LM";
CM_ BO_ 1015 "E92 M3 DCT 2011 K-CAN trace (superwofy/E9X-M-CAN-Integration-Module, MIT): 117 frames, DLC {8: 117}, median interval 160 ms | undefined bits changing in the trace: [0, 1, 2, 3, 4, 5, 6]";
CM_ BO_ 1040 "E92 M3 DCT 2011 K-CAN trace (superwofy/E9X-M-CAN-Integration-Module, MIT): 18 frames, DLC {4: 18}, median interval 995 ms";
CM_ BO_ 1041 "E92 M3 DCT 2011 K-CAN trace (superwofy/E9X-M-CAN-Integration-Module, MIT): 18 frames, DLC {3: 18}, median interval 994 ms | undefined bits changing in the trace: [2, 8, 9, 10, 11]";
CM_ BO_ 1043 "E92 M3 DCT 2011 K-CAN trace (superwofy/E9X-M-CAN-Integration-Module, MIT): 986 frames, DLC {8: 986}, median interval 230 ms | undefined bits changing in the trace: [0, 1, 2, 3, 4, 5, 6, 7, 8, 10, 11, 13, 15, 18, 20, 22, 24, 31, 32, 33, 34, 35, 36, 37, 38, 39, 40, 41, 42, 43, 44, 45, 46, 47, 48, 49, 51, 55, 58, 60, 61, 62]";
CM_ BO_ 1045 "E92 M3 DCT 2011 K-CAN trace (superwofy/E9X-M-CAN-Integration-Module, MIT): 986 frames, DLC {7: 986}, median interval 59 ms | undefined bits changing in the trace: [0, 1, 2, 3, 4, 5, 6, 7, 8, 9, 13, 14, 15, 16, 17, 18, 19, 20, 21, 22, 24, 25, 26, 27, 28, 29, 30, 33, 34, 35, 40, 41, 42, 43, 44, 45, 46, 47, 48, 49, 50, 51, 52, 53, 54]";
CM_ BO_ 1078 "E92 M3 DCT 2011 K-CAN trace (superwofy/E9X-M-CAN-Integration-Module, MIT): 7 frames, DLC {2: 7}, median interval 80 ms | undefined bits changing in the trace: [2]";
CM_ BO_ 1152 "E92 M3 DCT 2011 K-CAN trace (superwofy/E9X-M-CAN-Integration-Module, MIT): 2096 frames, DLC {8: 2096}, median interval 1100 ms | Also on PT-CAN (JBE gateway); signals copied from BMW_E9x_PT-CAN_full.dbc | community DBC name: NetworkManagmentKGM | SPdaten JBBF70.prg: 'Netzwerkmanagement' from JBBF | E65 message list: 'Netzwerkmanagement' from KGM | undefined bits changing in the trace: [1, 4, 5, 6, 8, 9, 12, 14, 20, 21, 22, 23, 25, 26, 27, 28, 29, 30, 31]";
CM_ SG_ 1152 S480_b0 "MK60E5 FW 7846816A (M3) signal (internal var 0xC8), meaning unknown";
CM_ BO_ 1153 "E92 M3 DCT 2011 K-CAN trace (superwofy/E9X-M-CAN-Integration-Module, MIT): 339 frames, DLC {8: 339}, median interval 1380 ms | SPdaten JBBF70.prg: 'Netzwerkmanagement' from ACSM | SPdaten JBBF70.prg: 'Netzwerkmanagement' from ACSM_ROSE | E65 message list: 'Netzwerkmanagement' from ACSM | undefined bits changing in the trace: [25, 26, 27, 28, 29, 30, 31]";
CM_ SG_ 1153 NM_NextNode "superwofy/E9X-M-CAN-Integration-Module notes (MIT) (Network management.txt): control-unit address of the next ring participant";
CM_ SG_ 1153 NM_Alive "superwofy/E9X-M-CAN-Integration-Module notes (MIT) (Network management.txt)";
CM_ SG_ 1153 NM_RingActive "superwofy/E9X-M-CAN-Integration-Module notes (MIT) (Network management.txt)";
CM_ SG_ 1153 NM_SleepIndication "superwofy/E9X-M-CAN-Integration-Module notes (MIT) (Network management.txt)";
CM_ SG_ 1153 NM_SleepAcknowledge "superwofy/E9X-M-CAN-Integration-Module notes (MIT) (Network management.txt)";
CM_ SG_ 1153 NM_RingStable "superwofy/E9X-M-CAN-Integration-Module notes (MIT) (Network management.txt)";
CM_ BO_ 1216 "E92 M3 DCT 2011 K-CAN trace (superwofy/E9X-M-CAN-Integration-Module, MIT): 2094 frames, DLC {8: 2094}, median interval 1100 ms | SPdaten JBBF70.prg: 'Netzwerkmanagement' from CAS | E65 message list: 'Netzwerkmanagement' from CAS | undefined bits changing in the trace: [25, 26, 27, 28, 29, 30, 31, 32, 33, 34, 35, 38, 39, 40, 41, 42, 43, 44, 45, 46, 47, 48, 49, 52, 56, 57, 58, 59, 60, 61, 62, 63]";
CM_ SG_ 1216 NM_NextNode "superwofy/E9X-M-CAN-Integration-Module notes (MIT) (Network management.txt): control-unit address of the next ring participant";
CM_ SG_ 1216 NM_Alive "superwofy/E9X-M-CAN-Integration-Module notes (MIT) (Network management.txt)";
CM_ SG_ 1216 NM_RingActive "superwofy/E9X-M-CAN-Integration-Module notes (MIT) (Network management.txt)";
CM_ SG_ 1216 NM_SleepIndication "superwofy/E9X-M-CAN-Integration-Module notes (MIT) (Network management.txt)";
CM_ SG_ 1216 NM_SleepAcknowledge "superwofy/E9X-M-CAN-Integration-Module notes (MIT) (Network management.txt)";
CM_ SG_ 1216 NM_RingStable "superwofy/E9X-M-CAN-Integration-Module notes (MIT) (Network management.txt)";
CM_ BO_ 1217 "E92 M3 DCT 2011 K-CAN trace (superwofy/E9X-M-CAN-Integration-Module, MIT): 2093 frames, DLC {8: 2093}, median interval 1099 ms | SPdaten JBBF70.prg: 'Netzwerkmanagement' from DWA | E65 message list: 'Netzwerkmanagement' from DWA | undefined bits changing in the trace: [25, 26, 27, 28, 29, 30, 31]";
CM_ SG_ 1217 NM_NextNode "superwofy/E9X-M-CAN-Integration-Module notes (MIT) (Network management.txt): control-unit address of the next ring participant";
CM_ SG_ 1217 NM_Alive "superwofy/E9X-M-CAN-Integration-Module notes (MIT) (Network management.txt)";
CM_ SG_ 1217 NM_RingActive "superwofy/E9X-M-CAN-Integration-Module notes (MIT) (Network management.txt)";
CM_ SG_ 1217 NM_SleepIndication "superwofy/E9X-M-CAN-Integration-Module notes (MIT) (Network management.txt)";
CM_ SG_ 1217 NM_SleepAcknowledge "superwofy/E9X-M-CAN-Integration-Module notes (MIT) (Network management.txt)";
CM_ SG_ 1217 NM_RingStable "superwofy/E9X-M-CAN-Integration-Module notes (MIT) (Network management.txt)";
CM_ BO_ 1238 "E92 M3 DCT 2011 K-CAN trace (superwofy/E9X-M-CAN-Integration-Module, MIT): 2091 frames, DLC {8: 2091}, median interval 1106 ms | SPdaten JBBF70.prg: 'Netzwerkmanagement' from FZD | undefined bits changing in the trace: [16, 25, 26, 27, 28, 29, 30, 31]";
CM_ SG_ 1238 NM_NextNode "superwofy/E9X-M-CAN-Integration-Module notes (MIT) (Network management.txt): control-unit address of the next ring participant";
CM_ SG_ 1238 NM_Alive "superwofy/E9X-M-CAN-Integration-Module notes (MIT) (Network management.txt)";
CM_ SG_ 1238 NM_RingActive "superwofy/E9X-M-CAN-Integration-Module notes (MIT) (Network management.txt)";
CM_ SG_ 1238 NM_SleepIndication "superwofy/E9X-M-CAN-Integration-Module notes (MIT) (Network management.txt)";
CM_ SG_ 1238 NM_SleepAcknowledge "superwofy/E9X-M-CAN-Integration-Module notes (MIT) (Network management.txt)";
CM_ SG_ 1238 NM_RingStable "superwofy/E9X-M-CAN-Integration-Module notes (MIT) (Network management.txt)";
CM_ BO_ 1247 "E92 M3 DCT 2011 K-CAN trace (superwofy/E9X-M-CAN-Integration-Module, MIT): 293 frames, DLC {8: 293}, median interval 1378 ms | SPdaten JBBF70.prg: 'Netzwerkmanagement' from FLA | E65 message list: 'Netzwerkmanagement' from FLA | undefined bits changing in the trace: [25, 26, 27, 28, 29, 30, 31]";
CM_ SG_ 1247 NM_NextNode "superwofy/E9X-M-CAN-Integration-Module notes (MIT) (Network management.txt): control-unit address of the next ring participant";
CM_ SG_ 1247 NM_Alive "superwofy/E9X-M-CAN-Integration-Module notes (MIT) (Network management.txt)";
CM_ SG_ 1247 NM_RingActive "superwofy/E9X-M-CAN-Integration-Module notes (MIT) (Network management.txt)";
CM_ SG_ 1247 NM_SleepIndication "superwofy/E9X-M-CAN-Integration-Module notes (MIT) (Network management.txt)";
CM_ SG_ 1247 NM_SleepAcknowledge "superwofy/E9X-M-CAN-Integration-Module notes (MIT) (Network management.txt)";
CM_ SG_ 1247 NM_RingStable "superwofy/E9X-M-CAN-Integration-Module notes (MIT) (Network management.txt)";
CM_ BO_ 1248 "E92 M3 DCT 2011 K-CAN trace (superwofy/E9X-M-CAN-Integration-Module, MIT): 2090 frames, DLC {8: 2090}, median interval 1101 ms | SPdaten JBBF70.prg: 'Netzwerkmanagement' from Kombi | E65 message list: 'Netzwerkmanagement' from Kombi | undefined bits changing in the trace: [25, 26, 27, 28, 29, 30, 31]";
CM_ SG_ 1248 NM_NextNode "superwofy/E9X-M-CAN-Integration-Module notes (MIT) (Network management.txt): control-unit address of the next ring participant";
CM_ SG_ 1248 NM_Alive "superwofy/E9X-M-CAN-Integration-Module notes (MIT) (Network management.txt)";
CM_ SG_ 1248 NM_RingActive "superwofy/E9X-M-CAN-Integration-Module notes (MIT) (Network management.txt)";
CM_ SG_ 1248 NM_SleepIndication "superwofy/E9X-M-CAN-Integration-Module notes (MIT) (Network management.txt)";
CM_ SG_ 1248 NM_SleepAcknowledge "superwofy/E9X-M-CAN-Integration-Module notes (MIT) (Network management.txt)";
CM_ SG_ 1248 NM_RingStable "superwofy/E9X-M-CAN-Integration-Module notes (MIT) (Network management.txt)";
CM_ BO_ 1249 "E92 M3 DCT 2011 K-CAN trace (superwofy/E9X-M-CAN-Integration-Module, MIT): 2091 frames, DLC {8: 2091}, median interval 1100 ms | SPdaten ACC2.prg: 'Netzwerkmanagement PT-CAN' from Diverse Sender | undefined bits changing in the trace: [25, 26, 27, 28, 29, 30, 31]";
CM_ SG_ 1249 NM_NextNode "superwofy/E9X-M-CAN-Integration-Module notes (MIT) (Network management.txt): control-unit address of the next ring participant";
CM_ SG_ 1249 NM_Alive "superwofy/E9X-M-CAN-Integration-Module notes (MIT) (Network management.txt)";
CM_ SG_ 1249 NM_RingActive "superwofy/E9X-M-CAN-Integration-Module notes (MIT) (Network management.txt)";
CM_ SG_ 1249 NM_SleepIndication "superwofy/E9X-M-CAN-Integration-Module notes (MIT) (Network management.txt)";
CM_ SG_ 1249 NM_SleepAcknowledge "superwofy/E9X-M-CAN-Integration-Module notes (MIT) (Network management.txt)";
CM_ SG_ 1249 NM_RingStable "superwofy/E9X-M-CAN-Integration-Module notes (MIT) (Network management.txt)";
CM_ BO_ 1250 "E92 M3 DCT 2011 K-CAN trace (superwofy/E9X-M-CAN-Integration-Module, MIT): 2079 frames, DLC {8: 2079}, median interval 1100 ms | SPdaten JBBF70.prg: 'Netzwerkmanagement' from CCC_GW/CHAMP_M_ASK2 | E65 message list: 'Netzwerkmanagement' from CCC_GW/M_ASK | undefined bits changing in the trace: [25, 26, 27, 28, 29, 30, 31]";
CM_ SG_ 1250 NM_NextNode "superwofy/E9X-M-CAN-Integration-Module notes (MIT) (Network management.txt): control-unit address of the next ring participant";
CM_ SG_ 1250 NM_Alive "superwofy/E9X-M-CAN-Integration-Module notes (MIT) (Network management.txt)";
CM_ SG_ 1250 NM_RingActive "superwofy/E9X-M-CAN-Integration-Module notes (MIT) (Network management.txt)";
CM_ SG_ 1250 NM_SleepIndication "superwofy/E9X-M-CAN-Integration-Module notes (MIT) (Network management.txt)";
CM_ SG_ 1250 NM_SleepAcknowledge "superwofy/E9X-M-CAN-Integration-Module notes (MIT) (Network management.txt)";
CM_ SG_ 1250 NM_RingStable "superwofy/E9X-M-CAN-Integration-Module notes (MIT) (Network management.txt)";
CM_ BO_ 1252 "E92 M3 DCT 2011 K-CAN trace (superwofy/E9X-M-CAN-Integration-Module, MIT): 293 frames, DLC {8: 293}, median interval 1373 ms | SPdaten JBBF70.prg: 'Netzwerkmanagement' from PDC | E65 message list: 'Netzwerkmanagement' from PDC | undefined bits changing in the trace: [25, 26, 27, 28, 29, 30, 31]";
CM_ SG_ 1252 NM_NextNode "superwofy/E9X-M-CAN-Integration-Module notes (MIT) (Network management.txt): control-unit address of the next ring participant";
CM_ SG_ 1252 NM_Alive "superwofy/E9X-M-CAN-Integration-Module notes (MIT) (Network management.txt)";
CM_ SG_ 1252 NM_RingActive "superwofy/E9X-M-CAN-Integration-Module notes (MIT) (Network management.txt)";
CM_ SG_ 1252 NM_SleepIndication "superwofy/E9X-M-CAN-Integration-Module notes (MIT) (Network management.txt)";
CM_ SG_ 1252 NM_SleepAcknowledge "superwofy/E9X-M-CAN-Integration-Module notes (MIT) (Network management.txt)";
CM_ SG_ 1252 NM_RingStable "superwofy/E9X-M-CAN-Integration-Module notes (MIT) (Network management.txt)";
CM_ BO_ 1255 "E92 M3 DCT 2011 K-CAN trace (superwofy/E9X-M-CAN-Integration-Module, MIT): 2079 frames, DLC {8: 2079}, median interval 1108 ms | SPdaten JBBF70.prg: 'Netzwerkmanagement' from ZBE | E65 message list: 'Netzwerkmanagement' from ZBE/ZBE_LO | undefined bits changing in the trace: [25, 26, 27, 28, 29, 30, 31]";
CM_ SG_ 1255 NM_NextNode "superwofy/E9X-M-CAN-Integration-Module notes (MIT) (Network management.txt): control-unit address of the next ring participant";
CM_ SG_ 1255 NM_Alive "superwofy/E9X-M-CAN-Integration-Module notes (MIT) (Network management.txt)";
CM_ SG_ 1255 NM_RingActive "superwofy/E9X-M-CAN-Integration-Module notes (MIT) (Network management.txt)";
CM_ SG_ 1255 NM_SleepIndication "superwofy/E9X-M-CAN-Integration-Module notes (MIT) (Network management.txt)";
CM_ SG_ 1255 NM_SleepAcknowledge "superwofy/E9X-M-CAN-Integration-Module notes (MIT) (Network management.txt)";
CM_ SG_ 1255 NM_RingStable "superwofy/E9X-M-CAN-Integration-Module notes (MIT) (Network management.txt)";
CM_ BO_ 1261 "E92 M3 DCT 2011 K-CAN trace (superwofy/E9X-M-CAN-Integration-Module, MIT): 1676 frames, DLC {8: 1676}, median interval 1100 ms | SPdaten JBBF70.prg: 'Netzwerkmanagement' from SM_FA | E65 message list: 'Netzwerkmanagement' from SM_FA/SM_FA_KBUS | undefined bits changing in the trace: [16, 25, 26, 27, 28, 29, 30, 31]";
CM_ SG_ 1261 NM_NextNode "superwofy/E9X-M-CAN-Integration-Module notes (MIT) (Network management.txt): control-unit address of the next ring participant";
CM_ SG_ 1261 NM_Alive "superwofy/E9X-M-CAN-Integration-Module notes (MIT) (Network management.txt)";
CM_ SG_ 1261 NM_RingActive "superwofy/E9X-M-CAN-Integration-Module notes (MIT) (Network management.txt)";
CM_ SG_ 1261 NM_SleepIndication "superwofy/E9X-M-CAN-Integration-Module notes (MIT) (Network management.txt)";
CM_ SG_ 1261 NM_SleepAcknowledge "superwofy/E9X-M-CAN-Integration-Module notes (MIT) (Network management.txt)";
CM_ SG_ 1261 NM_RingStable "superwofy/E9X-M-CAN-Integration-Module notes (MIT) (Network management.txt)";
CM_ BO_ 1262 "E92 M3 DCT 2011 K-CAN trace (superwofy/E9X-M-CAN-Integration-Module, MIT): 403 frames, DLC {8: 403}, median interval 1360 ms | SPdaten JBBF70.prg: 'Netzwerkmanagement' from SM_BF | E65 message list: 'Netzwerkmanagement' from SM_BF/SM_BF_KBUS | undefined bits changing in the trace: [16, 25, 26, 27, 28, 29, 30, 31]";
CM_ SG_ 1262 NM_NextNode "superwofy/E9X-M-CAN-Integration-Module notes (MIT) (Network management.txt): control-unit address of the next ring participant";
CM_ SG_ 1262 NM_Alive "superwofy/E9X-M-CAN-Integration-Module notes (MIT) (Network management.txt)";
CM_ SG_ 1262 NM_RingActive "superwofy/E9X-M-CAN-Integration-Module notes (MIT) (Network management.txt)";
CM_ SG_ 1262 NM_SleepIndication "superwofy/E9X-M-CAN-Integration-Module notes (MIT) (Network management.txt)";
CM_ SG_ 1262 NM_SleepAcknowledge "superwofy/E9X-M-CAN-Integration-Module notes (MIT) (Network management.txt)";
CM_ SG_ 1262 NM_RingStable "superwofy/E9X-M-CAN-Integration-Module notes (MIT) (Network management.txt)";
CM_ BO_ 1266 "E92 M3 DCT 2011 K-CAN trace (superwofy/E9X-M-CAN-Integration-Module, MIT): 2095 frames, DLC {8: 2095}, median interval 1100 ms | SPdaten JBBF70.prg: 'Netzwerkmanagement' from FRMFA | E65 message list: 'Netzwerkmanagement' from KBM | undefined bits changing in the trace: [16, 17, 25, 26, 27, 28, 29, 30, 31, 32, 33, 34, 35, 36, 37, 38, 39, 40, 41, 42, 43, 44, 45, 47, 48, 49, 50, 51, 52, 53, 54, 55, 56, 57, 58, 59, 60, 61, 62, 63]";
CM_ SG_ 1266 NM_NextNode "superwofy/E9X-M-CAN-Integration-Module notes (MIT) (Network management.txt): control-unit address of the next ring participant";
CM_ SG_ 1266 NM_Alive "superwofy/E9X-M-CAN-Integration-Module notes (MIT) (Network management.txt)";
CM_ SG_ 1266 NM_RingActive "superwofy/E9X-M-CAN-Integration-Module notes (MIT) (Network management.txt)";
CM_ SG_ 1266 NM_SleepIndication "superwofy/E9X-M-CAN-Integration-Module notes (MIT) (Network management.txt)";
CM_ SG_ 1266 NM_SleepAcknowledge "superwofy/E9X-M-CAN-Integration-Module notes (MIT) (Network management.txt)";
CM_ SG_ 1266 NM_RingStable "superwofy/E9X-M-CAN-Integration-Module notes (MIT) (Network management.txt)";
CM_ BO_ 1267 "E92 M3 DCT 2011 K-CAN trace (superwofy/E9X-M-CAN-Integration-Module, MIT): 2080 frames, DLC {8: 2080}, median interval 1100 ms | SPdaten JBBF70.prg: 'Netzwerkmanagement' from CID_C/CID_C_H | E65 message list: 'Netzwerkmanagement' from CID_C/CID_C_H | undefined bits changing in the trace: [25, 26, 27, 28, 29, 30, 31]";
CM_ SG_ 1267 NM_NextNode "superwofy/E9X-M-CAN-Integration-Module notes (MIT) (Network management.txt): control-unit address of the next ring participant";
CM_ SG_ 1267 NM_Alive "superwofy/E9X-M-CAN-Integration-Module notes (MIT) (Network management.txt)";
CM_ SG_ 1267 NM_RingActive "superwofy/E9X-M-CAN-Integration-Module notes (MIT) (Network management.txt)";
CM_ SG_ 1267 NM_SleepIndication "superwofy/E9X-M-CAN-Integration-Module notes (MIT) (Network management.txt)";
CM_ SG_ 1267 NM_SleepAcknowledge "superwofy/E9X-M-CAN-Integration-Module notes (MIT) (Network management.txt)";
CM_ SG_ 1267 NM_RingStable "superwofy/E9X-M-CAN-Integration-Module notes (MIT) (Network management.txt)";
CM_ BO_ 1272 "E92 M3 DCT 2011 K-CAN trace (superwofy/E9X-M-CAN-Integration-Module, MIT): 2081 frames, DLC {8: 2081}, median interval 1100 ms | SPdaten JBBF70.prg: 'Netzwerkmanagement' from IHKA | E65 message list: 'Netzwerkmanagement' from IHKA | undefined bits changing in the trace: [25, 26, 27, 28, 29, 30, 31]";
CM_ SG_ 1272 NM_NextNode "superwofy/E9X-M-CAN-Integration-Module notes (MIT) (Network management.txt): control-unit address of the next ring participant";
CM_ SG_ 1272 NM_Alive "superwofy/E9X-M-CAN-Integration-Module notes (MIT) (Network management.txt)";
CM_ SG_ 1272 NM_RingActive "superwofy/E9X-M-CAN-Integration-Module notes (MIT) (Network management.txt)";
CM_ SG_ 1272 NM_SleepIndication "superwofy/E9X-M-CAN-Integration-Module notes (MIT) (Network management.txt)";
CM_ SG_ 1272 NM_SleepAcknowledge "superwofy/E9X-M-CAN-Integration-Module notes (MIT) (Network management.txt)";
CM_ SG_ 1272 NM_RingStable "superwofy/E9X-M-CAN-Integration-Module notes (MIT) (Network management.txt)";
CM_ BO_ 1408 "E92 M3 DCT 2011 K-CAN trace (superwofy/E9X-M-CAN-Integration-Module, MIT): 83 frames, DLC {8: 83}, median interval 22 ms | Also on PT-CAN (JBE gateway); signals copied from BMW_E9x_PT-CAN_full.dbc | community DBC name: ServicesKGM | SPdaten JBBF70.prg: 'Dienste' from JBBF | E65 message list: 'Dienste' from KGM | undefined bits changing in the trace: [1, 2, 3, 5, 6, 8, 9, 10, 11, 12, 16, 17, 19, 20, 21, 22, 23, 24, 25, 26, 27, 28, 29, 30, 31]";
CM_ SG_ 1408 S580_b0 "MK60E5 FW 7846816A (M3) signal (internal var 0xD7), meaning unknown";
CM_ BO_ 1409 "E92 M3 DCT 2011 K-CAN trace (superwofy/E9X-M-CAN-Integration-Module, MIT): 86 frames, DLC {8: 86}, median interval 4592 ms | SPdaten JBBF70.prg: 'Dienste' from ACSM/ACSM_ROSE | E65 message list: 'Dienste' from ACSM";
CM_ SG_ 1409 ServiceType "superwofy/E9X-M-CAN-Integration-Module notes (MIT) (Check Control.txt)";
CM_ SG_ 1409 CC_ID "superwofy/E9X-M-CAN-Integration-Module notes (MIT) (Check Control.txt): Check Control ID; valid only when ServiceType = 0x40";
CM_ SG_ 1409 CC_Status "superwofy/E9X-M-CAN-Integration-Module notes (MIT) (Check Control.txt): valid only when ServiceType = 0x40";
CM_ SG_ 1409 CC_CycleTime "superwofy/E9X-M-CAN-Integration-Module notes (MIT) (Check Control.txt): repeat time in s (1..14); valid only when ServiceType = 0x40";
CM_ SG_ 1409 CC_Flashing "superwofy/E9X-M-CAN-Integration-Module notes (MIT) (Check Control.txt): valid only when ServiceType = 0x40";
CM_ BO_ 1426 "E92 M3 DCT 2011 K-CAN trace (superwofy/E9X-M-CAN-Integration-Module, MIT): 39 frames, DLC {8: 39}, median interval 1000 ms | Also on PT-CAN (JBE gateway); signals copied from BMW_E9x_PT-CAN_full.dbc | community DBC name: ServicesDME | SPdaten JBBF70.prg: 'Dienste' from DDE1/DME1 | E65 message list: 'Dienste' from DDE1/DME1 | undefined bits changing in the trace: [32, 33, 34, 35, 36, 37, 38, 39, 40, 41, 42, 43, 44, 45, 46, 47, 48, 49, 50, 51, 52, 53, 54, 55, 56, 57, 58, 59, 60, 61, 62, 63]";
CM_ SG_ 1426 ServiceType "superwofy/E9X-M-CAN-Integration-Module notes (MIT) (Check Control.txt)";
CM_ SG_ 1426 CC_ID "superwofy/E9X-M-CAN-Integration-Module notes (MIT) (Check Control.txt): Check Control ID; valid only when ServiceType = 0x40";
CM_ SG_ 1426 CC_Status "superwofy/E9X-M-CAN-Integration-Module notes (MIT) (Check Control.txt): valid only when ServiceType = 0x40";
CM_ SG_ 1426 CC_CycleTime "superwofy/E9X-M-CAN-Integration-Module notes (MIT) (Check Control.txt): repeat time in s (1..14); valid only when ServiceType = 0x40";
CM_ SG_ 1426 CC_Flashing "superwofy/E9X-M-CAN-Integration-Module notes (MIT) (Check Control.txt): valid only when ServiceType = 0x40";
CM_ BO_ 1432 "E92 M3 DCT 2011 K-CAN trace (superwofy/E9X-M-CAN-Integration-Module, MIT): 8 frames, DLC {8: 8}, median interval 5200 ms | SPdaten JBBF70.prg: 'Dienste' from EGS_EL | E65 message list: 'Dienste' from DKG/EGS_MECH/EGS_MECH+NAVI/SMG/SMG_M";
CM_ SG_ 1432 ServiceType "superwofy/E9X-M-CAN-Integration-Module notes (MIT) (Check Control.txt)";
CM_ SG_ 1432 CC_ID "superwofy/E9X-M-CAN-Integration-Module notes (MIT) (Check Control.txt): Check Control ID; valid only when ServiceType = 0x40";
CM_ SG_ 1432 CC_Status "superwofy/E9X-M-CAN-Integration-Module notes (MIT) (Check Control.txt): valid only when ServiceType = 0x40";
CM_ SG_ 1432 CC_CycleTime "superwofy/E9X-M-CAN-Integration-Module notes (MIT) (Check Control.txt): repeat time in s (1..14); valid only when ServiceType = 0x40";
CM_ SG_ 1432 CC_Flashing "superwofy/E9X-M-CAN-Integration-Module notes (MIT) (Check Control.txt): valid only when ServiceType = 0x40";
CM_ BO_ 1449 "E92 M3 DCT 2011 K-CAN trace (superwofy/E9X-M-CAN-Integration-Module, MIT): 63 frames, DLC {8: 63}, median interval 162 ms | Also on PT-CAN (JBE gateway); signals copied from BMW_E9x_PT-CAN_full.dbc | community DBC name: ServicesDSC | SPdaten JBBF70.prg: 'Dienste' from EHB3 | E65 message list: 'Dienste' from DSC_CT/DSC_RB/DXC_RB | undefined bits changing in the trace: [1, 4, 5, 6, 8, 9, 10, 13, 14, 16, 23, 24, 25, 26, 27, 28, 29, 30, 31, 32, 33, 34, 35, 36, 37, 38, 39, 40, 41, 42, 43, 48, 49, 50, 51, 52, 53, 54, 55, 57, 58, 59, 60, 61, 62, 63]";
CM_ SG_ 1449 S5A9_b0 "MK60E5 FW 7846816A (M3) signal (internal var 0x74), meaning unknown";
CM_ BO_ 1472 "E92 M3 DCT 2011 K-CAN trace (superwofy/E9X-M-CAN-Integration-Module, MIT): 272 frames, DLC {8: 272}, median interval 2000 ms | SPdaten JBBF70.prg: 'Dienste' from CAS | superwofy note: '0x5C0 CAS CC-ID 315.txt' | E65 message list: 'Dienste' from CAS | undefined bits changing in the trace: [32, 33, 34, 35, 36, 37, 38, 39, 40, 41, 42, 43, 44, 45, 46, 47, 48, 49, 50, 51, 52, 53, 54, 55, 56, 57, 58, 59, 60, 61, 62, 63]";
CM_ SG_ 1472 ServiceType "superwofy/E9X-M-CAN-Integration-Module notes (MIT) (Check Control.txt)";
CM_ SG_ 1472 CC_ID "superwofy/E9X-M-CAN-Integration-Module notes (MIT) (Check Control.txt): Check Control ID; valid only when ServiceType = 0x40";
CM_ SG_ 1472 CC_Status "superwofy/E9X-M-CAN-Integration-Module notes (MIT) (Check Control.txt): valid only when ServiceType = 0x40";
CM_ SG_ 1472 CC_CycleTime "superwofy/E9X-M-CAN-Integration-Module notes (MIT) (Check Control.txt): repeat time in s (1..14); valid only when ServiceType = 0x40";
CM_ SG_ 1472 CC_Flashing "superwofy/E9X-M-CAN-Integration-Module notes (MIT) (Check Control.txt): valid only when ServiceType = 0x40";
CM_ BO_ 1473 "E92 M3 DCT 2011 K-CAN trace (superwofy/E9X-M-CAN-Integration-Module, MIT): 5 frames, DLC {8: 5} | SPdaten JBBF70.prg: 'Dienste' from DWA | E65 message list: 'Dienste' from DWA";
CM_ SG_ 1473 ServiceType "superwofy/E9X-M-CAN-Integration-Module notes (MIT) (Check Control.txt)";
CM_ SG_ 1473 CC_ID "superwofy/E9X-M-CAN-Integration-Module notes (MIT) (Check Control.txt): Check Control ID; valid only when ServiceType = 0x40";
CM_ SG_ 1473 CC_Status "superwofy/E9X-M-CAN-Integration-Module notes (MIT) (Check Control.txt): valid only when ServiceType = 0x40";
CM_ SG_ 1473 CC_CycleTime "superwofy/E9X-M-CAN-Integration-Module notes (MIT) (Check Control.txt): repeat time in s (1..14); valid only when ServiceType = 0x40";
CM_ SG_ 1473 CC_Flashing "superwofy/E9X-M-CAN-Integration-Module notes (MIT) (Check Control.txt): valid only when ServiceType = 0x40";
CM_ BO_ 1494 "E92 M3 DCT 2011 K-CAN trace (superwofy/E9X-M-CAN-Integration-Module, MIT): 39 frames, DLC {8: 39}, median interval 10343 ms | Also on PT-CAN (JBE gateway); signals copied from BMW_E9x_PT-CAN_full.dbc | SPdaten JBBF70.prg: 'Dienste' from FZD";
CM_ SG_ 1494 ServiceType "superwofy/E9X-M-CAN-Integration-Module notes (MIT) (Check Control.txt)";
CM_ SG_ 1494 CC_ID "superwofy/E9X-M-CAN-Integration-Module notes (MIT) (Check Control.txt): Check Control ID; valid only when ServiceType = 0x40";
CM_ SG_ 1494 CC_Status "superwofy/E9X-M-CAN-Integration-Module notes (MIT) (Check Control.txt): valid only when ServiceType = 0x40";
CM_ SG_ 1494 CC_CycleTime "superwofy/E9X-M-CAN-Integration-Module notes (MIT) (Check Control.txt): repeat time in s (1..14); valid only when ServiceType = 0x40";
CM_ SG_ 1494 CC_Flashing "superwofy/E9X-M-CAN-Integration-Module notes (MIT) (Check Control.txt): valid only when ServiceType = 0x40";
CM_ BO_ 1504 "E92 M3 DCT 2011 K-CAN trace (superwofy/E9X-M-CAN-Integration-Module, MIT): 284 frames, DLC {8: 284}, median interval 500 ms | Also on PT-CAN (JBE gateway); signals copied from BMW_E9x_PT-CAN_full.dbc | community DBC name: ServicesKOMBI | SPdaten JBBF70.prg: 'Dienste' from Kombi | E65 message list: 'Dienste' from Kombi | undefined bits changing in the trace: [32, 33, 34, 35, 36, 37, 38, 39, 40, 41, 42, 43, 44, 45, 46, 47, 48, 49, 50, 51, 52, 53, 54, 55]";
CM_ SG_ 1504 ServiceType "superwofy/E9X-M-CAN-Integration-Module notes (MIT) (Check Control.txt)";
CM_ SG_ 1504 CC_ID "superwofy/E9X-M-CAN-Integration-Module notes (MIT) (Check Control.txt): Check Control ID; valid only when ServiceType = 0x40";
CM_ SG_ 1504 CC_Status "superwofy/E9X-M-CAN-Integration-Module notes (MIT) (Check Control.txt): valid only when ServiceType = 0x40";
CM_ SG_ 1504 CC_CycleTime "superwofy/E9X-M-CAN-Integration-Module notes (MIT) (Check Control.txt): repeat time in s (1..14); valid only when ServiceType = 0x40";
CM_ SG_ 1504 CC_Flashing "superwofy/E9X-M-CAN-Integration-Module notes (MIT) (Check Control.txt): valid only when ServiceType = 0x40";
CM_ BO_ 1506 "E92 M3 DCT 2011 K-CAN trace (superwofy/E9X-M-CAN-Integration-Module, MIT): 10 frames, DLC {8: 10}, median interval 676 ms | SPdaten JBBF70.prg: 'Dienste' from CCC_GW/CHAMP_M_ASK2 | superwofy note: '0x5E2 iDrive settings to KOMBI.txt' | E65 message list: 'Dienste' from CCC_GW/M_ASK";
CM_ SG_ 1506 ServiceType "superwofy/E9X-M-CAN-Integration-Module notes (MIT) (Check Control.txt)";
CM_ SG_ 1506 CC_ID "superwofy/E9X-M-CAN-Integration-Module notes (MIT) (Check Control.txt): Check Control ID; valid only when ServiceType = 0x40";
CM_ SG_ 1506 CC_Status "superwofy/E9X-M-CAN-Integration-Module notes (MIT) (Check Control.txt): valid only when ServiceType = 0x40";
CM_ SG_ 1506 CC_CycleTime "superwofy/E9X-M-CAN-Integration-Module notes (MIT) (Check Control.txt): repeat time in s (1..14); valid only when ServiceType = 0x40";
CM_ SG_ 1506 CC_Flashing "superwofy/E9X-M-CAN-Integration-Module notes (MIT) (Check Control.txt): valid only when ServiceType = 0x40";
CM_ BO_ 1511 "E92 M3 DCT 2011 K-CAN trace (superwofy/E9X-M-CAN-Integration-Module, MIT): 259 frames, DLC {8: 259}, median interval 2014 ms | SPdaten JBBF70.prg: 'Dienste' from ZBE | E65 message list: 'Dienste' from ZBE/ZBE_LO | undefined bits changing in the trace: [32, 33, 34]";
CM_ SG_ 1511 ServiceType "superwofy/E9X-M-CAN-Integration-Module notes (MIT) (Check Control.txt)";
CM_ SG_ 1511 CC_ID "superwofy/E9X-M-CAN-Integration-Module notes (MIT) (Check Control.txt): Check Control ID; valid only when ServiceType = 0x40";
CM_ SG_ 1511 CC_Status "superwofy/E9X-M-CAN-Integration-Module notes (MIT) (Check Control.txt): valid only when ServiceType = 0x40";
CM_ SG_ 1511 CC_CycleTime "superwofy/E9X-M-CAN-Integration-Module notes (MIT) (Check Control.txt): repeat time in s (1..14); valid only when ServiceType = 0x40";
CM_ SG_ 1511 CC_Flashing "superwofy/E9X-M-CAN-Integration-Module notes (MIT) (Check Control.txt): valid only when ServiceType = 0x40";
CM_ BO_ 1522 "E92 M3 DCT 2011 K-CAN trace (superwofy/E9X-M-CAN-Integration-Module, MIT): 109 frames, DLC {8: 109}, median interval 4800 ms | Also on PT-CAN (JBE gateway); signals copied from BMW_E9x_PT-CAN_full.dbc | community DBC name: ServicesKBM | SPdaten JBBF70.prg: 'Dienste' from FRMFA/FRMFA_ALC | E65 message list: 'Dienste' from KBM";
CM_ SG_ 1522 ServiceType "superwofy/E9X-M-CAN-Integration-Module notes (MIT) (Check Control.txt)";
CM_ SG_ 1522 CC_ID "superwofy/E9X-M-CAN-Integration-Module notes (MIT) (Check Control.txt): Check Control ID; valid only when ServiceType = 0x40";
CM_ SG_ 1522 CC_Status "superwofy/E9X-M-CAN-Integration-Module notes (MIT) (Check Control.txt): valid only when ServiceType = 0x40";
CM_ SG_ 1522 CC_CycleTime "superwofy/E9X-M-CAN-Integration-Module notes (MIT) (Check Control.txt): repeat time in s (1..14); valid only when ServiceType = 0x40";
CM_ SG_ 1522 CC_Flashing "superwofy/E9X-M-CAN-Integration-Module notes (MIT) (Check Control.txt): valid only when ServiceType = 0x40";
CM_ BO_ 1523 "E92 M3 DCT 2011 K-CAN trace (superwofy/E9X-M-CAN-Integration-Module, MIT): 2 frames, DLC {8: 2} | SPdaten JBBF70.prg: 'Dienste' from CID_C/CID_C_H | E65 message list: 'Dienste' from CID_C/CID_C_H";
CM_ SG_ 1523 ServiceType "superwofy/E9X-M-CAN-Integration-Module notes (MIT) (Check Control.txt)";
CM_ SG_ 1523 CC_ID "superwofy/E9X-M-CAN-Integration-Module notes (MIT) (Check Control.txt): Check Control ID; valid only when ServiceType = 0x40";
CM_ SG_ 1523 CC_Status "superwofy/E9X-M-CAN-Integration-Module notes (MIT) (Check Control.txt): valid only when ServiceType = 0x40";
CM_ SG_ 1523 CC_CycleTime "superwofy/E9X-M-CAN-Integration-Module notes (MIT) (Check Control.txt): repeat time in s (1..14); valid only when ServiceType = 0x40";
CM_ SG_ 1523 CC_Flashing "superwofy/E9X-M-CAN-Integration-Module notes (MIT) (Check Control.txt): valid only when ServiceType = 0x40";
CM_ BO_ 1528 "E92 M3 DCT 2011 K-CAN trace (superwofy/E9X-M-CAN-Integration-Module, MIT): 209 frames, DLC {8: 209}, median interval 999 ms | SPdaten JBBF70.prg: 'Dienste' from IHKA | E65 message list: 'Dienste' from IHKA";
CM_ SG_ 1528 ServiceType "superwofy/E9X-M-CAN-Integration-Module notes (MIT) (Check Control.txt)";
CM_ SG_ 1528 CC_ID "superwofy/E9X-M-CAN-Integration-Module notes (MIT) (Check Control.txt): Check Control ID; valid only when ServiceType = 0x40";
CM_ SG_ 1528 CC_Status "superwofy/E9X-M-CAN-Integration-Module notes (MIT) (Check Control.txt): valid only when ServiceType = 0x40";
CM_ SG_ 1528 CC_CycleTime "superwofy/E9X-M-CAN-Integration-Module notes (MIT) (Check Control.txt): repeat time in s (1..14); valid only when ServiceType = 0x40";
CM_ SG_ 1528 CC_Flashing "superwofy/E9X-M-CAN-Integration-Module notes (MIT) (Check Control.txt): valid only when ServiceType = 0x40";
CM_ BO_ 1987 "E92 M3 DCT 2011 K-CAN trace (superwofy/E9X-M-CAN-Integration-Module, MIT): 215 frames, DLC {8: 215}, median interval 85 ms | SPdaten JBBF70.prg: 'CAS Steuerung 1' from CAS | E65 message list: 'CAS Applikationsnachricht 2' from TOOL_BANDENDE_CAS | undefined bits changing in the trace: [0, 1, 2, 3, 4, 8, 9, 10, 11, 12, 13, 14, 15, 16, 17, 18, 19, 20, 21, 22, 23, 24, 25, 26, 27, 28, 29, 30, 31, 32, 33, 34, 35, 36, 37, 38, 39, 40, 41, 42, 43, 44, 45, 46, 47, 48, 49, 50, 51, 52, 53, 54, 55, 56, 57, 58, 59, 60, 61, 62, 63]";
BA_DEF_ BO_ "GenMsgCycleTime" INT 0 65535;
BA_DEF_ BO_ "GenMsgSendType" ENUM "Cyclic","Event";
BA_DEF_ "BusType" STRING ;
BA_DEF_ "DBName" STRING ;
BA_DEF_DEF_ "GenMsgCycleTime" 0;
BA_DEF_DEF_ "GenMsgSendType" "Event";
BA_DEF_DEF_ "BusType" "CAN";
BA_DEF_DEF_ "DBName" "";
BA_ "DBName" "BMW_E9x_K_CAN";
BA_ "GenMsgCycleTime" BO_ 168 100;
BA_ "GenMsgSendType" BO_ 168 0;
BA_ "GenMsgCycleTime" BO_ 169 100;
BA_ "GenMsgSendType" BO_ 169 0;
BA_ "GenMsgCycleTime" BO_ 170 100;
BA_ "GenMsgSendType" BO_ 170 0;
BA_ "GenMsgCycleTime" BO_ 192 200;
BA_ "GenMsgSendType" BO_ 192 0;
BA_ "GenMsgCycleTime" BO_ 196 200;
BA_ "GenMsgSendType" BO_ 196 0;
BA_ "GenMsgCycleTime" BO_ 200 200;
BA_ "GenMsgSendType" BO_ 200 0;
BA_ "GenMsgCycleTime" BO_ 206 100;
BA_ "GenMsgSendType" BO_ 206 0;
BA_ "GenMsgCycleTime" BO_ 215 200;
BA_ "GenMsgSendType" BO_ 215 0;
BA_ "GenMsgCycleTime" BO_ 242 10000;
BA_ "GenMsgSendType" BO_ 242 0;
BA_ "GenMsgCycleTime" BO_ 250 100;
BA_ "GenMsgSendType" BO_ 250 0;
BA_ "GenMsgCycleTime" BO_ 304 100;
BA_ "GenMsgSendType" BO_ 304 0;
BA_ "GenMsgCycleTime" BO_ 309 10000;
BA_ "GenMsgSendType" BO_ 309 0;
BA_ "GenMsgCycleTime" BO_ 370 5000;
BA_ "GenMsgSendType" BO_ 370 0;
BA_ "GenMsgCycleTime" BO_ 373 100;
BA_ "GenMsgSendType" BO_ 373 0;
BA_ "GenMsgCycleTime" BO_ 405 10000;
BA_ "GenMsgSendType" BO_ 405 0;
BA_ "GenMsgCycleTime" BO_ 414 200;
BA_ "GenMsgSendType" BO_ 414 0;
BA_ "GenMsgCycleTime" BO_ 416 100;
BA_ "GenMsgSendType" BO_ 416 0;
BA_ "GenMsgCycleTime" BO_ 422 100;
BA_ "GenMsgSendType" BO_ 422 0;
BA_ "GenMsgCycleTime" BO_ 436 100;
BA_ "GenMsgSendType" BO_ 436 0;
BA_ "GenMsgCycleTime" BO_ 437 1000;
BA_ "GenMsgSendType" BO_ 437 0;
BA_ "GenMsgCycleTime" BO_ 438 1000;
BA_ "GenMsgSendType" BO_ 438 0;
BA_ "GenMsgCycleTime" BO_ 450 500;
BA_ "GenMsgSendType" BO_ 450 0;
BA_ "GenMsgCycleTime" BO_ 454 2000;
BA_ "GenMsgSendType" BO_ 454 0;
BA_ "GenMsgCycleTime" BO_ 464 100;
BA_ "GenMsgSendType" BO_ 464 0;
BA_ "GenMsgCycleTime" BO_ 466 200;
BA_ "GenMsgSendType" BO_ 466 0;
BA_ "GenMsgCycleTime" BO_ 470 1000;
BA_ "GenMsgSendType" BO_ 470 0;
BA_ "GenMsgCycleTime" BO_ 481 200;
BA_ "GenMsgSendType" BO_ 481 0;
BA_ "GenMsgCycleTime" BO_ 487 100;
BA_ "GenMsgSendType" BO_ 487 0;
BA_ "GenMsgCycleTime" BO_ 488 100;
BA_ "GenMsgSendType" BO_ 488 0;
BA_ "GenMsgCycleTime" BO_ 494 1000;
BA_ "GenMsgSendType" BO_ 494 0;
BA_ "GenMsgCycleTime" BO_ 512 200;
BA_ "GenMsgSendType" BO_ 512 0;
BA_ "GenMsgCycleTime" BO_ 514 5000;
BA_ "GenMsgSendType" BO_ 514 0;
BA_ "GenMsgCycleTime" BO_ 554 10000;
BA_ "GenMsgSendType" BO_ 554 0;
BA_ "GenMsgCycleTime" BO_ 562 10000;
BA_ "GenMsgSendType" BO_ 562 0;
BA_ "GenMsgCycleTime" BO_ 570 100;
BA_ "GenMsgSendType" BO_ 570 0;
BA_ "GenMsgCycleTime" BO_ 578 10000;
BA_ "GenMsgSendType" BO_ 578 0;
BA_ "GenMsgCycleTime" BO_ 582 1000;
BA_ "GenMsgSendType" BO_ 582 0;
BA_ "GenMsgCycleTime" BO_ 586 2000;
BA_ "GenMsgSendType" BO_ 586 0;
BA_ "GenMsgCycleTime" BO_ 587 10000;
BA_ "GenMsgSendType" BO_ 587 0;
BA_ "GenMsgCycleTime" BO_ 594 50;
BA_ "GenMsgSendType" BO_ 594 0;
BA_ "GenMsgCycleTime" BO_ 612 100;
BA_ "GenMsgSendType" BO_ 612 0;
BA_ "GenMsgCycleTime" BO_ 621 100;
BA_ "GenMsgSendType" BO_ 621 0;
BA_ "GenMsgCycleTime" BO_ 622 2000;
BA_ "GenMsgSendType" BO_ 622 0;
BA_ "GenMsgCycleTime" BO_ 646 500;
BA_ "GenMsgSendType" BO_ 646 0;
BA_ "GenMsgCycleTime" BO_ 672 5000;
BA_ "GenMsgSendType" BO_ 672 0;
BA_ "GenMsgCycleTime" BO_ 678 1000;
BA_ "GenMsgSendType" BO_ 678 0;
BA_ "GenMsgCycleTime" BO_ 692 200;
BA_ "GenMsgSendType" BO_ 692 0;
BA_ "GenMsgCycleTime" BO_ 698 5000;
BA_ "GenMsgSendType" BO_ 698 0;
BA_ "GenMsgCycleTime" BO_ 704 10000;
BA_ "GenMsgSendType" BO_ 704 0;
BA_ "GenMsgCycleTime" BO_ 707 5000;
BA_ "GenMsgSendType" BO_ 707 0;
BA_ "GenMsgCycleTime" BO_ 714 1000;
BA_ "GenMsgSendType" BO_ 714 0;
BA_ "GenMsgCycleTime" BO_ 718 10000;
BA_ "GenMsgSendType" BO_ 718 0;
BA_ "GenMsgCycleTime" BO_ 746 10000;
BA_ "GenMsgSendType" BO_ 746 0;
BA_ "GenMsgCycleTime" BO_ 752 2000;
BA_ "GenMsgSendType" BO_ 752 0;
BA_ "GenMsgCycleTime" BO_ 753 1000;
BA_ "GenMsgSendType" BO_ 753 0;
BA_ "GenMsgCycleTime" BO_ 756 5000;
BA_ "GenMsgSendType" BO_ 756 0;
BA_ "GenMsgCycleTime" BO_ 758 5000;
BA_ "GenMsgSendType" BO_ 758 0;
BA_ "GenMsgCycleTime" BO_ 762 5000;
BA_ "GenMsgSendType" BO_ 762 0;
BA_ "GenMsgCycleTime" BO_ 764 5000;
BA_ "GenMsgSendType" BO_ 764 0;
BA_ "GenMsgCycleTime" BO_ 772 1000;
BA_ "GenMsgSendType" BO_ 772 0;
BA_ "GenMsgCycleTime" BO_ 774 1000;
BA_ "GenMsgSendType" BO_ 774 0;
BA_ "GenMsgCycleTime" BO_ 776 500;
BA_ "GenMsgSendType" BO_ 776 0;
BA_ "GenMsgCycleTime" BO_ 785 200;
BA_ "GenMsgSendType" BO_ 785 0;
BA_ "GenMsgCycleTime" BO_ 788 2000;
BA_ "GenMsgSendType" BO_ 788 0;
BA_ "GenMsgCycleTime" BO_ 789 500;
BA_ "GenMsgSendType" BO_ 789 0;
BA_ "GenMsgCycleTime" BO_ 797 5000;
BA_ "GenMsgSendType" BO_ 797 0;
BA_ "GenMsgCycleTime" BO_ 806 200;
BA_ "GenMsgSendType" BO_ 806 0;
BA_ "GenMsgCycleTime" BO_ 808 1000;
BA_ "GenMsgSendType" BO_ 808 0;
BA_ "GenMsgCycleTime" BO_ 814 1000;
BA_ "GenMsgSendType" BO_ 814 0;
BA_ "GenMsgCycleTime" BO_ 824 5000;
BA_ "GenMsgSendType" BO_ 824 0;
BA_ "GenMsgCycleTime" BO_ 826 10000;
BA_ "GenMsgSendType" BO_ 826 0;
BA_ "GenMsgCycleTime" BO_ 841 200;
BA_ "GenMsgSendType" BO_ 841 0;
BA_ "GenMsgCycleTime" BO_ 844 1000;
BA_ "GenMsgSendType" BO_ 844 0;
BA_ "GenMsgCycleTime" BO_ 846 5000;
BA_ "GenMsgSendType" BO_ 846 0;
BA_ "GenMsgCycleTime" BO_ 847 5000;
BA_ "GenMsgSendType" BO_ 847 0;
BA_ "GenMsgCycleTime" BO_ 860 5000;
BA_ "GenMsgSendType" BO_ 860 0;
BA_ "GenMsgCycleTime" BO_ 862 5000;
BA_ "GenMsgSendType" BO_ 862 0;
BA_ "GenMsgCycleTime" BO_ 864 5000;
BA_ "GenMsgSendType" BO_ 864 0;
BA_ "GenMsgCycleTime" BO_ 866 5000;
BA_ "GenMsgSendType" BO_ 866 0;
BA_ "GenMsgCycleTime" BO_ 868 5000;
BA_ "GenMsgSendType" BO_ 868 0;
BA_ "GenMsgCycleTime" BO_ 870 5000;
BA_ "GenMsgSendType" BO_ 870 0;
BA_ "GenMsgCycleTime" BO_ 871 50;
BA_ "GenMsgSendType" BO_ 871 0;
BA_ "GenMsgCycleTime" BO_ 897 10000;
BA_ "GenMsgSendType" BO_ 897 0;
BA_ "GenMsgCycleTime" BO_ 921 1000;
BA_ "GenMsgSendType" BO_ 921 0;
BA_ "GenMsgCycleTime" BO_ 940 10000;
BA_ "GenMsgSendType" BO_ 940 0;
BA_ "GenMsgCycleTime" BO_ 953 200;
BA_ "GenMsgSendType" BO_ 953 0;
BA_ "GenMsgCycleTime" BO_ 957 5000;
BA_ "GenMsgSendType" BO_ 957 0;
BA_ "GenMsgCycleTime" BO_ 958 10000;
BA_ "GenMsgSendType" BO_ 958 0;
BA_ "GenMsgCycleTime" BO_ 970 2000;
BA_ "GenMsgSendType" BO_ 970 0;
BA_ "GenMsgCycleTime" BO_ 985 100;
BA_ "GenMsgSendType" BO_ 985 0;
BA_ "GenMsgCycleTime" BO_ 1040 1000;
BA_ "GenMsgSendType" BO_ 1040 0;
BA_ "GenMsgCycleTime" BO_ 1041 1000;
BA_ "GenMsgSendType" BO_ 1041 0;
BA_ "GenMsgCycleTime" BO_ 1217 1000;
BA_ "GenMsgSendType" BO_ 1217 0;
BA_ "GenMsgCycleTime" BO_ 1272 1000;
BA_ "GenMsgSendType" BO_ 1272 0;
BA_ "GenMsgCycleTime" BO_ 1408 20;
BA_ "GenMsgSendType" BO_ 1408 0;
BA_ "GenMsgCycleTime" BO_ 1409 5000;
BA_ "GenMsgSendType" BO_ 1409 0;
BA_ "GenMsgCycleTime" BO_ 1426 1000;
BA_ "GenMsgSendType" BO_ 1426 0;
BA_ "GenMsgCycleTime" BO_ 1432 5000;
BA_ "GenMsgSendType" BO_ 1432 0;
BA_ "GenMsgCycleTime" BO_ 1472 2000;
BA_ "GenMsgSendType" BO_ 1472 0;
BA_ "GenMsgCycleTime" BO_ 1494 10000;
BA_ "GenMsgSendType" BO_ 1494 0;
BA_ "GenMsgCycleTime" BO_ 1504 500;
BA_ "GenMsgSendType" BO_ 1504 0;
BA_ "GenMsgCycleTime" BO_ 1511 2000;
BA_ "GenMsgSendType" BO_ 1511 0;
BA_ "GenMsgCycleTime" BO_ 1522 5000;
BA_ "GenMsgSendType" BO_ 1522 0;
BA_ "GenMsgCycleTime" BO_ 1528 1000;
BA_ "GenMsgSendType" BO_ 1528 0;
VAL_ 168 ST_TORQ_AVL 0 "intervention request executed" 1 "intervention ignition request not executed" 2 "intervention injection request not executed" 3 "intervention ignition and injection request not executed" 15 "signal invalid" ;
VAL_ 168 ST_DMEA_SWO 0 "no error" 1 "shutdown because of error" ;
VAL_ 169 ST_SW_LEV_RPM 0 "idle speed > the treshold value" 1 "idle speed < the treshold value" ;
VAL_ 169 ST_INFS 0 "no action" 1 "thrust cutoff active" ;
VAL_ 170 ANG_ACPD 0 "unpressed" 255 "pedal on the floor" ;
VAL_ 170 RPM_ENG_ERR 0 "signal clear and correct" 1 "speed sensor defective" 3 "signal invalid" ;
VAL_ 170 ST_IDLG_ENG 0 "idle" 1 "no idle" 3 "signal invalid" ;
VAL_ 170 ST_CLCTR_V 0 "acc regulation, pedal not pressed" 1 "acc regulation, pedal pressed" 4 "cc regulation, retard" 5 "cc regulation, constant speed" 6 "cc regulation, recall" 7 "cc regulation, speed up" 8 "pedal not pressed" 9 "pedal pressed" 10 "pedal transgress" 11 "pedal kickdown" ;
VAL_ 309 CTR_CR_SWO_EKP 15 "Signal invalid" ;
VAL_ 414 ST_CLCTR 0 "No Regulation" 1 "ABS Regulation" 2 "ASC Control" 4 "DSC Control" 8 "HBA Control" 16 "I&C Control" 32 "EBV control" 64 "Dyno mode active" 255 "Signal Invalid" ;
VAL_ 414 ST_DSC 0 "OK" 1 "Passive" 2 "Defect" 3 "reserved" 4 "Traction Mode" 5 "ABS fault" 6 "Undervoltage" 7 "Signal Invalid" ;
VAL_ 414 ST_DCRN_AVL 0 "No Requirement" 1 "requirement EMF accepted" 2 "Request EMF Accepted" 15 "Signal Invalid" ;
VAL_ 416 ST_VEH_DVCO 0 "Vehicle Standing" 1 "Vehicle Moves Forward, FL/FR forward" 2 "Vehicle Moves Backward, FL/FR backward" 3 "Vehicle Moves, Direction Detection Not Possible" 7 "Signal Invalid" ;
VAL_ 436 ST_UN_V_SPDM 0 "km/h" 1 "mph" 3 "signal invalid" ;
VAL_ 436 ST_INTF_CCTRA_KL 0 "okay" 1 "error in kombi" 2 "error in acc module" 4 "error in cruise control" ;
VAL_ 436 ST_WALI_ENG 0 "off" 1 "yellow on" 3 "signal invalid" ;
VAL_ 437 CTR_EFAN_AIC 0 "0" 14 "14" 15 "signal invalid" ;
VAL_ 437 CTR_AIC_RDI 0 "readyness switch off" 1 "readyness switch on" 2 "readyness switch on, rotation speed increase level 1" 4 "readyness switch on, rotation speed increase level 2" 7 "signal invalid" ;
VAL_ 438 ST_GEN 0 "OK" 1 "in high temperature limitation" 2 "defect" 3 "signal invalid" ;
VAL_ 438 ST_LDST_GEN 0 "0% < utilization rate < 50%" 1 "50% < utilization rate < 100%" 2 "utilization rate = 100%" 3 "signal invalid" ;
VAL_ 464 ST_ENG_RUN 0 "engine off" 1 "engine starting" 2 "engine running" 3 "signal invalid" ;
VAL_ 464 ST_SW_WAUP 0 "warming up" 1 "engine warm" 2 "EGS forced switching active" 3 "signal invalid" ;
VAL_ 464 CTR_SLCK 0 "not allowed" 1 "no requirement Shiftlock" 2 "requirement Shiftlock" 3 "signal invalid" ;
VAL_ 466 ShiftLeverPosition 0 "Off" 1 "P" 2 "R" 4 "N" 8 "D" ;
VAL_ 466 ShiftLeverMode 0 "Normal" 1 "Sport" 2 "Manual" ;
VAL_ 470 TASTER_TELEFON 0 "Keine_Aktion" 1 "Taster_TEL_gedrueckt" 3 "Signal_ungueltig" ;
VAL_ 470 TASTER_AUDIO_LAUTSTAERKE 0 "Keine_Aktion" 1 "Lautstaerke_leiser" 2 "Lautstaerke_lauter" 3 "Signal_ungueltig" ;
VAL_ 470 TASTER_AUDIO_SUCHLAUF 0 "Keine_Aktion" 1 "Suchlauf_abwaerts" 2 "Suchlauf_aufwaerts" 3 "Signal_ungueltig" ;
VAL_ 470 TASTER_PUSH_TO_TALK 0 "Keine_Aktion" 1 "Taster_PTT_gedrueckt" 3 "Signal_ungueltig" ;
VAL_ 470 TASTER_SONDERFUNKTION 0 "Keine_Aktion" 1 "Taster_gedrueckt" 3 "Signal_ungueltig" ;
VAL_ 470 TASTER_PUSH_TO_HEAR 0 "Keine_Aktion" 1 "Taster_PTH_gedrueckt" 3 "Signal_ungueltig" ;
VAL_ 473 MDriveButton_inv 0 "Pressed" 1 "Not pressed" ;
VAL_ 473 MDriveButton 0 "Not pressed" 1 "Pressed" ;
VAL_ 487 SeatHeatingButton_FA 0 "Not pressed" 1 "Pressed" ;
VAL_ 488 SeatHeatingButton_BF 0 "Not pressed" 1 "Pressed" ;
VAL_ 512 ST_V_CLCTR_CCTR 0 "cruise control off" 1 "cruise control inactive" 2 "cruise control active" ;
VAL_ 512 CTR_DISP_CCTR 0 "markers off" 1 "markers on" ;
VAL_ 514 DimmerPosition 0 "Below minimum" 28 "Step 1 (min)" 56 "Step 2" 84 "Step 3" 112 "Step 4" 141 "Step 5" 169 "Step 6" 197 "Step 7" 225 "Step 8" 253 "Step 9 (max)" 254 "No dimming, interior lighting inactive" ;
VAL_ 517 GongRequest 0 "Off" 1 "Single gong" 2 "Double gong" 3 "Long triple gong" 5 "Double beep (collision warning)" 8 "Long triple gong" 10 "Four quick beeps" 11 "Two double gongs" 13 "Single horn sound" ;
VAL_ 518 ShiftlightMode 5 "Off" 134 "One more segment per message" 182 "Sweep all segments (11 ms per segment)" ;
VAL_ 570 KeyFobButton 0 "None" 1 "Unlock" 4 "Lock" 16 "Trunk" ;
VAL_ 586 PDC_Status 5 "PDC on" 6 "PDC off" ;
VAL_ 594 WiperState 205 "Wipe started" 206 "Wipe cycle finished (also sent while cranking)" ;
VAL_ 615 ControllerButtonPressed 0 "Released" 1 "Pressed" ;
VAL_ 615 ControllerDirection 0 "Centre" 1 "North" ;
VAL_ 615 ControllerButton 192 "Menu" 221 "Joystick north" 222 "Controller press" ;
VAL_ 678 WISCHERTASTER 0 "Keine_Aktion" 1 "Intervall/Automatik" 2 "Stufe_1" 3 "Stufe_2" 8 "Tippwischen" 16 "Frontwaschen" 64 "Heckwischen" 128 "Heckwaschen" 255 "Signal_ungueltig" ;
VAL_ 678 WISCHERPOTI 0 "Stufe_1" 1 "Stufe_2" 2 "Stufe_3" 4 "Stufe_4" 7 "Signal_ungueltig" ;
VAL_ 692 ConfirmationFlash 0 "None" 1 "Single flash (locked)" 2 "Double flash (unlocked)" 3 "Long single flash" ;
VAL_ 696 SpeedWarningOn 0 "Off" 1 "On" ;
VAL_ 696 SpeedWarningLimit 4093 "Take current speed" 4094 "No change" ;
VAL_ 704 CID_Brightness 255 "Invalid" ;
VAL_ 742 AutoAirDistribution 0 "Off" 1 "On" ;
VAL_ 742 AutoFan 0 "Manual fan control" 1 "Automatic fan control" ;
VAL_ 759 DistanceUnit 1 "km" 2 "miles" ;
VAL_ 760 DISP_HR 255 "Signal invalid" ;
VAL_ 760 DISP_MN 255 "Signal invalid" ;
VAL_ 760 DISP_SEC 255 "Signal invalid" ;
VAL_ 760 DISP_DATE_DAY 255 "Signal invalid" ;
VAL_ 760 DISP_DATE_WDAY 255 "Signal invalid" ;
VAL_ 760 DISP_DATE_MON 15 "Signal invalid" ;
VAL_ 760 DISP_DATE_YR 65535 "Signal invalid" ;
VAL_ 760 ST_DISP_CTI_DATE 15 "Signal invalid" ;
VAL_ 764 ST_DSW_DRD 3 "Signal invalid" ;
VAL_ 764 ST_CT_BON 3 "Signal invalid" ;
VAL_ 788 HeadlightRequest 1 "Twilight" 2 "Darkness" ;
VAL_ 789 VehicleMode 1 "Comfort" 2 "Sport" 10 "M Sport" ;
VAL_ 791 PDC_Button 0 "Not pressed" 1 "Pressed" ;
VAL_ 793 S319_b0 0 "Not pressed" 1 "Pressed" ;
VAL_ 797 S31D_b0 0 "Active" 1 "Failure" 3 "Reset / initialisation" ;
VAL_ 806 DamperProgram 8 "Comfort" 9 "Sport" 11 "M Sport" ;
VAL_ 822 CC_List_ID1 65534 "None" ;
VAL_ 822 CC_List_ID2 65534 "None" ;
VAL_ 822 CC_List_ID3 65534 "None" ;
VAL_ 847 Handbrake_push 1 "Released" 2 "Applied" ;
VAL_ 860 SpeedWarningOn 0 "Off" 1 "On" ;
VAL_ 860 SpeedWarningLimit 4095 "Invalid" ;
VAL_ 877 PDC_Rear_OuterRight 253 "No obstacle" ;
VAL_ 877 PDC_Rear_InnerRight 253 "No obstacle" ;
VAL_ 877 PDC_Rear_InnerLeft 253 "No obstacle" ;
VAL_ 877 PDC_Rear_OuterLeft 253 "No obstacle" ;
VAL_ 897 FLLV_EOI 121 "Signal invalid" ;
VAL_ 897 RECM_RFLV_EOI 0 "Signal invalid" ;
VAL_ 904 TYP_VEH 255 "Signal invalid" ;
VAL_ 904 TYP_BODY 255 "Signal invalid" ;
VAL_ 904 QUAN_GR 15 "Signal invalid" ;
VAL_ 904 TYP_ENG 4 "gasoline" ;
VAL_ 904 TYP_STE 1 "lhd" 2 "rhd" ;
VAL_ 904 TYP_GRB 1 "manual" 2 "automatic" ;
VAL_ 904 CLAS_PWR 3 "Signal invalid" ;
VAL_ 911 Camera 1 "On" 2 "Off" ;
VAL_ 911 TowView 0 "Off" 1 "On" ;
VAL_ 921 S399_b8 1 "M-Drive inactive" 2 "M-Drive active" ;
VAL_ 921 S399_b10 0 "Unchanged" 1 "DSC off" 2 "DSC on" 4 "M Dynamic Mode" ;
VAL_ 923 CameraStatus 209 "On" 226 "Off" ;
VAL_ 923 TowView 0 "Off" 1 "On" ;
VAL_ 936 PowerMode_CKM 1 "Normal" 2 "Sport" ;
VAL_ 937 PowerMode_CKM 1 "Normal" 2 "Sport" ;
VAL_ 942 CameraControl 129 "Left the camera view" 161 "Off" 165 "On" ;
VAL_ 947 SLCTN_SPCOS 15 "Signal invalid" ;
VAL_ 947 CTR_PWR_SPCOS 255 "Signal invalid" ;
VAL_ 947 CTR_PWR_COS 65535 "Signal invalid" ;
VAL_ 947 CTR_CBR 255 "Signal invalid" ;
VAL_ 947 RQ_PCOS 3 "Signal invalid" ;
VAL_ 947 CTR_PCOS 3 "Signal invalid" ;
VAL_ 948 ST_BTSW 0 "battery switch closed" 1 "battery switch opens in 5s" 2 "signal invalid" ;
VAL_ 948 ST_SWO_KL_30 0 "reserved" 1 "no shutdown by PM done" 2 "shutdown by PM done" 3 "signal invalid" ;
VAL_ 957 ConsumerShutdown 0 "Shut down (bus users go to sleep ready)" 1 "Normal" ;
VAL_ 958 FLLUPT_GPWSUP 4095 "Signal invalid" ;
VAL_ 983 LockVisualSignal_CKM 1 "On" 2 "Off" ;
VAL_ 987 SeatLastPosition_CKM 249 "Off" 252 "On" ;
VAL_ 989 DaytimeRunningLights_CKM 1 "Off" 2 "On" ;
VAL_ 991 AutoFanIntensity 5 "Medium" 6 "Low" 9 "High" ;
VAL_ 1409 ServiceType 1 "Service request" 12 "Request bus/subnetwork" 48 "CBS service notification" 50 "CBS service message 2" 64 "Check Control message standard" 65 "Check Control message extended" ;
VAL_ 1409 CC_Status 0 "Reset" 1 "Set" 3 "Invalid" ;
VAL_ 1409 CC_CycleTime 15 "Message disabled" ;
VAL_ 1409 CC_Flashing 0 "No flashing" 1 "Slow flashing" 2 "Fast flashing" 3 "Invalid" ;
VAL_ 1426 ServiceType 1 "Service request" 12 "Request bus/subnetwork" 48 "CBS service notification" 50 "CBS service message 2" 64 "Check Control message standard" 65 "Check Control message extended" ;
VAL_ 1426 CC_Status 0 "Reset" 1 "Set" 3 "Invalid" ;
VAL_ 1426 CC_CycleTime 15 "Message disabled" ;
VAL_ 1426 CC_Flashing 0 "No flashing" 1 "Slow flashing" 2 "Fast flashing" 3 "Invalid" ;
VAL_ 1432 ServiceType 1 "Service request" 12 "Request bus/subnetwork" 48 "CBS service notification" 50 "CBS service message 2" 64 "Check Control message standard" 65 "Check Control message extended" ;
VAL_ 1432 CC_Status 0 "Reset" 1 "Set" 3 "Invalid" ;
VAL_ 1432 CC_CycleTime 15 "Message disabled" ;
VAL_ 1432 CC_Flashing 0 "No flashing" 1 "Slow flashing" 2 "Fast flashing" 3 "Invalid" ;
VAL_ 1472 ServiceType 1 "Service request" 12 "Request bus/subnetwork" 48 "CBS service notification" 50 "CBS service message 2" 64 "Check Control message standard" 65 "Check Control message extended" ;
VAL_ 1472 CC_Status 0 "Reset" 1 "Set" 3 "Invalid" ;
VAL_ 1472 CC_CycleTime 15 "Message disabled" ;
VAL_ 1472 CC_Flashing 0 "No flashing" 1 "Slow flashing" 2 "Fast flashing" 3 "Invalid" ;
VAL_ 1473 ServiceType 1 "Service request" 12 "Request bus/subnetwork" 48 "CBS service notification" 50 "CBS service message 2" 64 "Check Control message standard" 65 "Check Control message extended" ;
VAL_ 1473 CC_Status 0 "Reset" 1 "Set" 3 "Invalid" ;
VAL_ 1473 CC_CycleTime 15 "Message disabled" ;
VAL_ 1473 CC_Flashing 0 "No flashing" 1 "Slow flashing" 2 "Fast flashing" 3 "Invalid" ;
VAL_ 1494 ServiceType 1 "Service request" 12 "Request bus/subnetwork" 48 "CBS service notification" 50 "CBS service message 2" 64 "Check Control message standard" 65 "Check Control message extended" ;
VAL_ 1494 CC_Status 0 "Reset" 1 "Set" 3 "Invalid" ;
VAL_ 1494 CC_CycleTime 15 "Message disabled" ;
VAL_ 1494 CC_Flashing 0 "No flashing" 1 "Slow flashing" 2 "Fast flashing" 3 "Invalid" ;
VAL_ 1504 ServiceType 1 "Service request" 12 "Request bus/subnetwork" 48 "CBS service notification" 50 "CBS service message 2" 64 "Check Control message standard" 65 "Check Control message extended" ;
VAL_ 1504 CC_Status 0 "Reset" 1 "Set" 3 "Invalid" ;
VAL_ 1504 CC_CycleTime 15 "Message disabled" ;
VAL_ 1504 CC_Flashing 0 "No flashing" 1 "Slow flashing" 2 "Fast flashing" 3 "Invalid" ;
VAL_ 1506 ServiceType 1 "Service request" 12 "Request bus/subnetwork" 48 "CBS service notification" 50 "CBS service message 2" 64 "Check Control message standard" 65 "Check Control message extended" ;
VAL_ 1506 CC_Status 0 "Reset" 1 "Set" 3 "Invalid" ;
VAL_ 1506 CC_CycleTime 15 "Message disabled" ;
VAL_ 1506 CC_Flashing 0 "No flashing" 1 "Slow flashing" 2 "Fast flashing" 3 "Invalid" ;
VAL_ 1511 ServiceType 1 "Service request" 12 "Request bus/subnetwork" 48 "CBS service notification" 50 "CBS service message 2" 64 "Check Control message standard" 65 "Check Control message extended" ;
VAL_ 1511 CC_Status 0 "Reset" 1 "Set" 3 "Invalid" ;
VAL_ 1511 CC_CycleTime 15 "Message disabled" ;
VAL_ 1511 CC_Flashing 0 "No flashing" 1 "Slow flashing" 2 "Fast flashing" 3 "Invalid" ;
VAL_ 1522 ServiceType 1 "Service request" 12 "Request bus/subnetwork" 48 "CBS service notification" 50 "CBS service message 2" 64 "Check Control message standard" 65 "Check Control message extended" ;
VAL_ 1522 CC_Status 0 "Reset" 1 "Set" 3 "Invalid" ;
VAL_ 1522 CC_CycleTime 15 "Message disabled" ;
VAL_ 1522 CC_Flashing 0 "No flashing" 1 "Slow flashing" 2 "Fast flashing" 3 "Invalid" ;
VAL_ 1523 ServiceType 1 "Service request" 12 "Request bus/subnetwork" 48 "CBS service notification" 50 "CBS service message 2" 64 "Check Control message standard" 65 "Check Control message extended" ;
VAL_ 1523 CC_Status 0 "Reset" 1 "Set" 3 "Invalid" ;
VAL_ 1523 CC_CycleTime 15 "Message disabled" ;
VAL_ 1523 CC_Flashing 0 "No flashing" 1 "Slow flashing" 2 "Fast flashing" 3 "Invalid" ;
VAL_ 1528 ServiceType 1 "Service request" 12 "Request bus/subnetwork" 48 "CBS service notification" 50 "CBS service message 2" 64 "Check Control message standard" 65 "Check Control message extended" ;
VAL_ 1528 CC_Status 0 "Reset" 1 "Set" 3 "Invalid" ;
VAL_ 1528 CC_CycleTime 15 "Message disabled" ;
VAL_ 1528 CC_Flashing 0 "No flashing" 1 "Slow flashing" 2 "Fast flashing" 3 "Invalid" ;
